VERSION "V1.7.4"

NS_ :

BS_:

BU_: DC RL RR FL FR

BO_ 1934 ReadCmd_FR: 64 FR
 SG_ ReadCmd_Subid_FR : 15|16@0+ (1,0) [0|65535] "" Vector__XXX
 SG_ ReadCmd_Sid_FR : 7|8@0+ (1,0) [0|255] "" Vector__XXX
 SG_ ReadCmd_length_FR : 31|8@0+ (1,0) [0|255] "" Vector__XXX
 SG_ ReadCmd_version2_FR : 103|64@0+ (1,0) [0|1.84467440737096E+019] "" Vector__XXX
 SG_ ReadCmd_version1_FR : 39|64@0+ (1,0) [0|1.84467440737096E+019] "" Vector__XXX

BO_ 1870 ReadCmd_FL: 64 FL
 SG_ ReadCmd_Subid_FL : 15|16@0+ (1,0) [0|65535] "" Vector__XXX
 SG_ ReadCmd_Sid_FL : 7|8@0+ (1,0) [0|255] "" Vector__XXX
 SG_ ReadCmd_length_FL : 31|8@0+ (1,0) [0|255] "" Vector__XXX
 SG_ ReadCmd_version2_FL : 103|64@0+ (1,0) [0|1.84467440737096E+019] "" Vector__XXX
 SG_ ReadCmd_version1_FL : 39|64@0+ (1,0) [0|1.84467440737096E+019] "" Vector__XXX

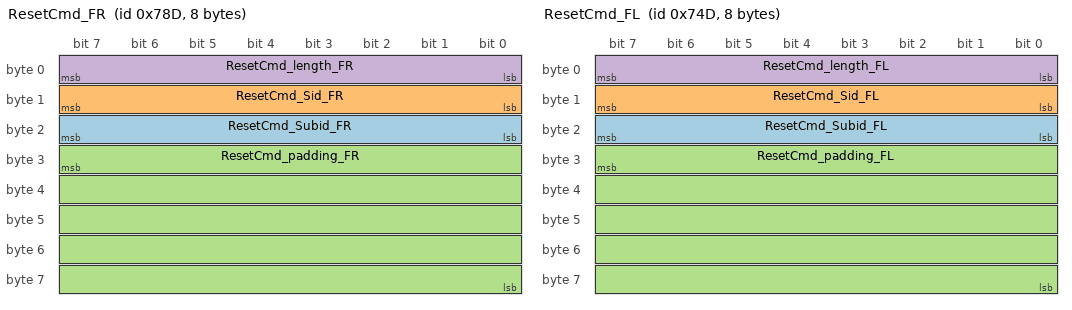
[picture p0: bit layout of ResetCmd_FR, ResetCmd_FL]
BO_ 1933 ResetCmd_FR: 8 FR
 SG_ ResetCmd_Subid_FR : 23|8@0+ (1,0) [0|255] "" Vector__XXX
 SG_ ResetCmd_Sid_FR : 15|8@0+ (1,0) [0|255] "" Vector__XXX
 SG_ ResetCmd_padding_FR : 31|40@0+ (1,0) [0|1099511627775] "" Vector__XXX
 SG_ ResetCmd_length_FR : 7|8@0+ (1,0) [0|255] "" Vector__XXX

BO_ 1869 ResetCmd_FL: 8 FL
 SG_ ResetCmd_Subid_FL : 23|8@0+ (1,0) [0|255] "" Vector__XXX
 SG_ ResetCmd_Sid_FL : 15|8@0+ (1,0) [0|255] "" Vector__XXX
 SG_ ResetCmd_padding_FL : 31|40@0+ (1,0) [0|1099511627775] "" Vector__XXX
 SG_ ResetCmd_length_FL : 7|8@0+ (1,0) [0|255] "" Vector__XXX

BO_ 1408 ObjectList_Obj1_FL: 64 FL
 SG_ RSDS_FL_PER_OBJ1_YawRate : 279|16@0+ (0.002,-3.14) [-3.14|127.93] "" Vector__XXX
 SG_ RSDS_FL_PER_OBJ1_Width : 263|16@0+ (0.01,0) [0|655.35] "" Vector__XXX
 SG_ RSDS_FL_PER_OBJ1_ValidFlag : 97|1@0+ (1,0) [0|1] "" Vector__XXX
 SG_ RSDS_FL_PER_OBJ1_ObstProbability : 255|8@0+ (1,0) [0|255] "" Vector__XXX
 SG_ RSDS_FL_PER_OBJ1_MotionType : 247|3@0+ (1,0) [0|7] "" Vector__XXX
 SG_ RSDS_FL_PER_OBJ1_MeasState : 99|2@0+ (1,0) [0|3] "" Vector__XXX
 SG_ RSDS_FL_PER_OBJ1_LifeCycle : 223|8@0+ (1,0) [0|255] "" Vector__XXX
 SG_ RSDS_FL_PER_OBJ1_Length : 231|16@0+ (0.05,0) [0|3276.75] "" Vector__XXX
 SG_ RSDS_FL_PER_OBJ1_ID : 215|8@0+ (1,0) [0|255] "" Vector__XXX
 SG_ RSDS_FL_PER_OBJ1_HeadingAng : 199|16@0+ (0.002,-3.14) [-3.14|127.93] "" Vector__XXX
 SG_ RSDS_FL_PER_OBJ1_ExistProb : 191|8@0+ (0.03326,0) [0|8.4813] "" Vector__XXX
 SG_ RSDS_FL_PER_OBJ1_DistZStd : 183|8@0+ (0.1,0) [0|25.5] "" Vector__XXX
 SG_ RSDS_FL_PER_OBJ1_DistZ : 167|16@0+ (0.125,-64) [-64|8127.875] "" Vector__XXX
 SG_ RSDS_FL_PER_OBJ1_DistYStd : 143|8@0+ (0.1,0) [0|25.5] "" Vector__XXX
 SG_ RSDS_FL_PER_OBJ1_DistY : 151|16@0+ (0.125,-256) [-256|7935.875] "" Vector__XXX
 SG_ RSDS_FL_PER_OBJ1_DistXStd : 135|8@0+ (0.1,0) [0|25.5] "" Vector__XXX
 SG_ RSDS_FL_PER_OBJ1_DistX : 119|16@0+ (0.0625,-256) [-256|3839.9375] "" Vector__XXX
 SG_ RSDS_FL_PER_OBJ1_ClassTypeProb : 111|8@0+ (1,0) [0|255] "" Vector__XXX
 SG_ RSDS_FL_PER_OBJ1_ClassType : 103|4@0+ (1,0) [0|15] "" Vector__XXX
 SG_ RSDS_FL_PER_OBJ1_AbsVelYStd : 79|8@0+ (0.0625,0) [0|15.9375] "" Vector__XXX
 SG_ RSDS_FL_PER_OBJ1_AbsVelY : 87|16@0+ (0.0312,-128) [-128|1916.692] "" Vector__XXX
 SG_ RSDS_FL_PER_OBJ1_AbsVelXStd : 71|8@0+ (0.0625,0) [0|15.9375] "" Vector__XXX
 SG_ RSDS_FL_PER_OBJ1_AbsVelX : 55|16@0+ (0.0312,-128) [-128|1916.692] "" Vector__XXX
 SG_ RSDS_FL_PER_OBJ1_AbsAccelYStd : 31|8@0+ (0.0625,0) [0|15.9375] "" Vector__XXX
 SG_ RSDS_FL_PER_OBJ1_AbsAccelY : 39|16@0+ (0.03125,-16) [-16|2031.96875] "" Vector__XXX
 SG_ RSDS_FL_PER_OBJ1_AbsAccelXStd : 23|8@0+ (0.0625,0) [0|15.9375] "" Vector__XXX
 SG_ RSDS_FL_PER_OBJ1_AbsAccelX : 7|16@0+ (0.03125,-16) [-16|2031.96875] "" Vector__XXX

BO_ 1502 FrameHeader_RR: 64 RR
 SG_ RSDS_RR_CALIB_RadarStatus : 179|2@0+ (1,0) [0|3] "" Vector__XXX
 SG_ RSDS_RR_NVMBLIND : 181|2@0+ (1,0) [0|3] "" Vector__XXX
 SG_ RSDS_RR_EnabledBLIND : 183|2@0+ (1,0) [0|3] "" Vector__XXX
 SG_ RSDS_RR_algoBLIND : 1|2@0+ (1,0) [0|3] "" Vector__XXX
 SG_ RSDS_RR_CALIB_InCalibState : 175|8@0+ (1,0) [0|255] "" Vector__XXX
 SG_ RSDS_RR_CALIB_FinalCalibState : 167|8@0+ (1,0) [0|255] "" Vector__XXX
 SG_ RSDS_RR_MountPosX : 151|16@0+ (0.001,-10) [-10|10] "" Vector__XXX
 SG_ RSDS_RR_YawMountAngle : 135|16@0+ (0.0001,-3.2) [-3.2|3.2] "" Vector__XXX
 SG_ RSDS_RR_RollMountAngle : 119|16@0+ (0.0001,-0.2) [-0.2|0.2] "" Vector__XXX
 SG_ RSDS_RR_PitchMountAngle : 103|16@0+ (0.0001,-0.2) [-0.2|0.2] "" Vector__XXX
 SG_ RSDS_RR_PER_OBJ_Num : 95|8@0+ (1,0) [0|255] "" Vector__XXX
 SG_ RSDS_RR_PER_HDR_Timestamp : 87|8@0+ (1,0) [0|255] "" Vector__XXX
 SG_ RSDS_RR_PER_HDR_RollingCounter : 5|4@0+ (1,0) [0|15] "" Vector__XXX
 SG_ RSDS_RR_PER_HDR_Checksum : 15|8@0+ (1,0) [0|255] "" Vector__XXX
 SG_ RSDS_RR_MountPosZ : 71|16@0+ (0.001,0) [0|2] "" Vector__XXX
 SG_ RSDS_RR_MountPosY : 55|16@0+ (0.001,-2.5) [-2.5|2.5] "" Vector__XXX
 SG_ RSDS_RR_CALIB_EleOffset : 39|16@0+ (0.0001,-1) [-1|1] "" Vector__XXX
 SG_ RSDS_RR_CALIB_AziOffset : 23|16@0+ (0.0001,-1) [-1|1] "" Vector__XXX
 SG_ RSDS_RR_BLIND : 7|2@0+ (1,0) [0|3] "" Vector__XXX

BO_ 1470 FrameHeader_RL: 64 RL
 SG_ RSDS_RL_CALIB_RadarStatus : 179|2@0+ (1,0) [0|3] "" Vector__XXX
 SG_ RSDS_RL_NVMBLIND : 181|2@0+ (1,0) [0|3] "" Vector__XXX
 SG_ RSDS_RL_EnabledBLIND : 183|2@0+ (1,0) [0|3] "" Vector__XXX
 SG_ RSDS_RL_algoBLIND : 1|2@0+ (1,0) [0|3] "" Vector__XXX
 SG_ RSDS_RL_CALIB_InCalibState : 175|8@0+ (1,0) [0|255] "" Vector__XXX
 SG_ RSDS_RL_CALIB_FinalCalibState : 167|8@0+ (1,0) [0|255] "" Vector__XXX
 SG_ RSDS_RL_MountPosX : 151|16@0+ (0.001,-10) [-10|10] "" Vector__XXX
 SG_ RSDS_RL_YawMountAngle : 135|16@0+ (0.0001,-3.2) [-3.2|3.2] "" Vector__XXX
 SG_ RSDS_RL_RollMountAngle : 119|16@0+ (0.0001,-0.2) [-0.2|0.2] "" Vector__XXX
 SG_ RSDS_RL_PitchMountAngle : 103|16@0+ (0.0001,-0.2) [-0.2|0.2] "" Vector__XXX
 SG_ RSDS_RL_PER_OBJ_Num : 95|8@0+ (1,0) [0|255] "" Vector__XXX
 SG_ RSDS_RL_PER_HDR_Timestamp : 87|8@0+ (1,0) [0|255] "" Vector__XXX
 SG_ RSDS_RL_PER_HDR_RollingCounter : 5|4@0+ (1,0) [0|15] "" Vector__XXX
 SG_ RSDS_RL_PER_HDR_Checksum : 15|8@0+ (1,0) [0|255] "" Vector__XXX
 SG_ RSDS_RL_MountPosZ : 71|16@0+ (0.001,0) [0|2] "" Vector__XXX
 SG_ RSDS_RL_MountPosY : 55|16@0+ (0.001,-2.5) [-2.5|2.5] "" Vector__XXX
 SG_ RSDS_RL_CALIB_EleOffset : 39|16@0+ (0.0001,-1) [-1|1] "" Vector__XXX
 SG_ RSDS_RL_CALIB_AziOffset : 23|16@0+ (0.0001,-1) [-1|1] "" Vector__XXX
 SG_ RSDS_RL_BLIND : 7|2@0+ (1,0) [0|3] "" Vector__XXX

BO_ 1454 FrameHeader_FR: 64 FR
 SG_ RSDS_FR_CALIB_RadarStatus : 179|2@0+ (1,0) [0|3] "" Vector__XXX
 SG_ RSDS_FR_NVMBLIND : 181|2@0+ (1,0) [0|3] "" Vector__XXX
 SG_ RSDS_FR_EnabledBLIND : 183|2@0+ (1,0) [0|3] "" Vector__XXX
 SG_ RSDS_FR_algoBLIND : 1|2@0+ (1,0) [0|3] "" Vector__XXX
 SG_ RSDS_FR_CALIB_InCalibState : 175|8@0+ (1,0) [0|255] "" Vector__XXX
 SG_ RSDS_FR_CALIB_FinalCalibState : 167|8@0+ (1,0) [0|255] "" Vector__XXX
 SG_ RSDS_FR_MountPosX : 151|16@0+ (0.001,-10) [-10|10] "" Vector__XXX
 SG_ RSDS_FR_YawMountAngle : 135|16@0+ (0.0001,-3.2) [-3.2|3.2] "" Vector__XXX
 SG_ RSDS_FR_RollMountAngle : 119|16@0+ (0.0001,-0.2) [-0.2|0.2] "" Vector__XXX
 SG_ RSDS_FR_PitchMountAngle : 103|16@0+ (0.0001,-0.2) [-0.2|0.2] "" Vector__XXX
 SG_ RSDS_FR_PER_OBJ_Num : 95|8@0+ (1,0) [0|255] "" Vector__XXX
 SG_ RSDS_FR_PER_HDR_Timestamp : 87|8@0+ (1,0) [0|255] "" Vector__XXX
 SG_ RSDS_FR_PER_HDR_RollingCounter : 5|4@0+ (1,0) [0|15] "" Vector__XXX
 SG_ RSDS_FR_PER_HDR_Checksum : 15|8@0+ (1,0) [0|255] "" Vector__XXX
 SG_ RSDS_FR_MountPosZ : 71|16@0+ (0.001,0) [0|2] "" Vector__XXX
 SG_ RSDS_FR_MountPosY : 55|16@0+ (0.001,-2.5) [-2.5|2.5] "" Vector__XXX
 SG_ RSDS_FR_CALIB_EleOffset : 39|16@0+ (0.0001,-1) [-1|1] "" Vector__XXX
 SG_ RSDS_FR_CALIB_AziOffset : 23|16@0+ (0.0001,-1) [-1|1] "" Vector__XXX
 SG_ RSDS_FR_BLIND : 7|2@0+ (1,0) [0|3] "" Vector__XXX

BO_ 1486 FrameHeader_FL: 64 FL
 SG_ RSDS_FL_CALIB_RadarStatus : 179|2@0+ (1,0) [0|3] "" Vector__XXX
 SG_ RSDS_FL_NVMBLIND : 181|2@0+ (1,0) [0|3] "" Vector__XXX
 SG_ RSDS_FL_EnabledBLIND : 183|2@0+ (1,0) [0|3] "" Vector__XXX
 SG_ RSDS_FL_algoBLIND : 1|2@0+ (1,0) [0|3] "" Vector__XXX
 SG_ RSDS_FL_CALIB_InCalibState : 175|8@0+ (1,0) [0|255] "" Vector__XXX
 SG_ RSDS_FL_CALIB_FinalCalibState : 167|8@0+ (1,0) [0|255] "" Vector__XXX
 SG_ RSDS_FL_MountPosX : 151|16@0+ (0.001,-10) [-10|10] "" Vector__XXX
 SG_ RSDS_FL_YawMountAngle : 135|16@0+ (0.0001,-3.2) [-3.2|3.2] "" Vector__XXX
 SG_ RSDS_FL_RollMountAngle : 119|16@0+ (0.0001,-0.2) [-0.2|0.2] "" Vector__XXX
 SG_ RSDS_FL_PitchMountAngle : 103|16@0+ (0.0001,-0.2) [-0.2|0.2] "" Vector__XXX
 SG_ RSDS_FL_PER_OBJ_Num : 95|8@0+ (1,0) [0|255] "" Vector__XXX
 SG_ RSDS_FL_PER_HDR_Timestamp : 87|8@0+ (1,0) [0|255] "" Vector__XXX
 SG_ RSDS_FL_PER_HDR_RollingCounter : 5|4@0+ (1,0) [0|15] "" Vector__XXX
 SG_ RSDS_FL_PER_HDR_Checksum : 15|8@0+ (1,0) [0|255] "" Vector__XXX
 SG_ RSDS_FL_MountPosZ : 71|16@0+ (0.001,0) [0|2] "" Vector__XXX
 SG_ RSDS_FL_MountPosY : 55|16@0+ (0.001,-2.5) [-2.5|2.5] "" Vector__XXX
 SG_ RSDS_FL_CALIB_EleOffset : 39|16@0+ (0.0001,-1) [-1|1] "" Vector__XXX
 SG_ RSDS_FL_CALIB_AziOffset : 23|16@0+ (0.0001,-1) [-1|1] "" Vector__XXX
 SG_ RSDS_FL_BLIND : 7|2@0+ (1,0) [0|3] "" Vector__XXX

BO_ 1031 DTC_GROUP2_RR: 64 RR
 SG_ DTC_Entry9_status_mask_RR : 479|8@0+ (1,0) [0|255] "" Vector__XXX
 SG_ DTC_Entry9_dtc_type_RR : 471|8@0+ (1,0) [0|255] "" Vector__XXX
 SG_ DTC_Entry9_dtc_num_RR : 439|32@0+ (1,0) [0|4294967295] "" Vector__XXX
 SG_ DTC_Entry9_change_ts_RR : 407|32@0+ (1,0) [0|4294967295] "" Vector__XXX
 SG_ DTC_Entry8_status_mask_RR : 399|8@0+ (1,0) [0|255] "" Vector__XXX
 SG_ DTC_Entry8_dtc_type_RR : 391|8@0+ (1,0) [0|255] "" Vector__XXX
 SG_ DTC_Entry8_dtc_num_RR : 359|32@0+ (1,0) [0|4294967295] "" Vector__XXX
 SG_ DTC_Entry8_change_ts_RR : 327|32@0+ (1,0) [0|4294967295] "" Vector__XXX
 SG_ DTC_Entry7_status_mask_RR : 319|8@0+ (1,0) [0|255] "" Vector__XXX
 SG_ DTC_Entry7_dtc_type_RR : 311|8@0+ (1,0) [0|255] "" Vector__XXX
 SG_ DTC_Entry7_dtc_num_RR : 279|32@0+ (1,0) [0|4294967295] "" Vector__XXX
 SG_ DTC_Entry7_change_ts_RR : 247|32@0+ (1,0) [0|4294967295] "" Vector__XXX
 SG_ DTC_Entry6_status_mask_RR : 239|8@0+ (1,0) [0|255] "" Vector__XXX
 SG_ DTC_Entry6_dtc_type_RR : 231|8@0+ (1,0) [0|255] "" Vector__XXX
 SG_ DTC_Entry6_dtc_num_RR : 199|32@0+ (1,0) [0|4294967295] "" Vector__XXX
 SG_ DTC_Entry6_change_ts_RR : 167|32@0+ (1,0) [0|4294967295] "" Vector__XXX
 SG_ DTC_Entry11_status_mask_RR : 159|8@0+ (1,0) [0|255] "" Vector__XXX
 SG_ DTC_Entry11_dtc_type_RR : 151|8@0+ (1,0) [0|255] "" Vector__XXX
 SG_ DTC_Entry11_dtc_num_RR : 119|32@0+ (1,0) [0|4294967295] "" Vector__XXX
 SG_ DTC_Entry11_change_ts_RR : 87|32@0+ (1,0) [0|4294967295] "" Vector__XXX
 SG_ DTC_Entry10_status_mask_RR : 79|8@0+ (1,0) [0|255] "" Vector__XXX
 SG_ DTC_Entry10_dtc_type_RR : 71|8@0+ (1,0) [0|255] "" Vector__XXX
 SG_ DTC_Entry10_dtc_num_RR : 39|32@0+ (1,0) [0|4294967295] "" Vector__XXX
 SG_ DTC_Entry10_change_ts_RR : 7|32@0+ (1,0) [0|4294967295] "" Vector__XXX

BO_ 1029 DTC_GROUP2_RL: 64 RL
 SG_ DTC_Entry9_status_mask_RL : 479|8@0+ (1,0) [0|255] "" Vector__XXX
 SG_ DTC_Entry9_dtc_type_RL : 471|8@0+ (1,0) [0|255] "" Vector__XXX
 SG_ DTC_Entry9_dtc_num_RL : 439|32@0+ (1,0) [0|4294967295] "" Vector__XXX
 SG_ DTC_Entry9_change_ts_RL : 407|32@0+ (1,0) [0|4294967295] "" Vector__XXX
 SG_ DTC_Entry8_status_mask_RL : 399|8@0+ (1,0) [0|255] "" Vector__XXX
 SG_ DTC_Entry8_dtc_type_RL : 391|8@0+ (1,0) [0|255] "" Vector__XXX
 SG_ DTC_Entry8_dtc_num_RL : 359|32@0+ (1,0) [0|4294967295] "" Vector__XXX
 SG_ DTC_Entry8_change_ts_RL : 327|32@0+ (1,0) [0|4294967295] "" Vector__XXX
 SG_ DTC_Entry7_status_mask_RL : 319|8@0+ (1,0) [0|255] "" Vector__XXX
 SG_ DTC_Entry7_dtc_type_RL : 311|8@0+ (1,0) [0|255] "" Vector__XXX
 SG_ DTC_Entry7_dtc_num_RL : 279|32@0+ (1,0) [0|4294967295] "" Vector__XXX
 SG_ DTC_Entry7_change_ts_RL : 247|32@0+ (1,0) [0|4294967295] "" Vector__XXX
 SG_ DTC_Entry6_status_mask_RL : 239|8@0+ (1,0) [0|255] "" Vector__XXX
 SG_ DTC_Entry6_dtc_type_RL : 231|8@0+ (1,0) [0|255] "" Vector__XXX
 SG_ DTC_Entry6_dtc_num_RL : 199|32@0+ (1,0) [0|4294967295] "" Vector__XXX
 SG_ DTC_Entry6_change_ts_RL : 167|32@0+ (1,0) [0|4294967295] "" Vector__XXX
 SG_ DTC_Entry11_status_mask_RL : 159|8@0+ (1,0) [0|255] "" Vector__XXX
 SG_ DTC_Entry11_dtc_type_RL : 151|8@0+ (1,0) [0|255] "" Vector__XXX
 SG_ DTC_Entry11_dtc_num_RL : 119|32@0+ (1,0) [0|4294967295] "" Vector__XXX
 SG_ DTC_Entry11_change_ts_RL : 87|32@0+ (1,0) [0|4294967295] "" Vector__XXX
 SG_ DTC_Entry10_status_mask_RL : 79|8@0+ (1,0) [0|255] "" Vector__XXX
 SG_ DTC_Entry10_dtc_type_RL : 71|8@0+ (1,0) [0|255] "" Vector__XXX
 SG_ DTC_Entry10_dtc_num_RL : 39|32@0+ (1,0) [0|4294967295] "" Vector__XXX
 SG_ DTC_Entry10_change_ts_RL : 7|32@0+ (1,0) [0|4294967295] "" Vector__XXX

BO_ 1027 DTC_GROUP2_FR: 64 Vector__XXX
 SG_ DTC_Entry9_status_mask_FR : 479|8@0+ (1,0) [0|255] "" Vector__XXX
 SG_ DTC_Entry9_dtc_type_FR : 471|8@0+ (1,0) [0|255] "" Vector__XXX
 SG_ DTC_Entry9_dtc_num_FR : 439|32@0+ (1,0) [0|4294967295] "" Vector__XXX
 SG_ DTC_Entry9_change_ts_FR : 407|32@0+ (1,0) [0|4294967295] "" Vector__XXX
 SG_ DTC_Entry8_status_mask_FR : 399|8@0+ (1,0) [0|255] "" Vector__XXX
 SG_ DTC_Entry8_dtc_type_FR : 391|8@0+ (1,0) [0|255] "" Vector__XXX
 SG_ DTC_Entry8_dtc_num_FR : 359|32@0+ (1,0) [0|4294967295] "" Vector__XXX
 SG_ DTC_Entry8_change_ts_FR : 327|32@0+ (1,0) [0|4294967295] "" Vector__XXX
 SG_ DTC_Entry7_status_mask_FR : 319|8@0+ (1,0) [0|255] "" Vector__XXX
 SG_ DTC_Entry7_dtc_type_FR : 311|8@0+ (1,0) [0|255] "" Vector__XXX
 SG_ DTC_Entry7_dtc_num_FR : 279|32@0+ (1,0) [0|4294967295] "" Vector__XXX
 SG_ DTC_Entry7_change_ts_FR : 247|32@0+ (1,0) [0|4294967295] "" Vector__XXX
 SG_ DTC_Entry6_status_mask_FR : 239|8@0+ (1,0) [0|255] "" Vector__XXX
 SG_ DTC_Entry6_dtc_type_FR : 231|8@0+ (1,0) [0|255] "" Vector__XXX
 SG_ DTC_Entry6_dtc_num_FR : 199|32@0+ (1,0) [0|4294967295] "" Vector__XXX
 SG_ DTC_Entry6_change_ts_FR : 167|32@0+ (1,0) [0|4294967295] "" Vector__XXX
 SG_ DTC_Entry11_status_mask_FR : 159|8@0+ (1,0) [0|255] "" Vector__XXX
 SG_ DTC_Entry11_dtc_type_FR : 151|8@0+ (1,0) [0|255] "" Vector__XXX
 SG_ DTC_Entry11_dtc_num_FR : 119|32@0+ (1,0) [0|4294967295] "" Vector__XXX
 SG_ DTC_Entry11_change_ts_FR : 87|32@0+ (1,0) [0|4294967295] "" Vector__XXX
 SG_ DTC_Entry10_status_mask_FR : 79|8@0+ (1,0) [0|255] "" Vector__XXX
 SG_ DTC_Entry10_dtc_type_FR : 71|8@0+ (1,0) [0|255] "" Vector__XXX
 SG_ DTC_Entry10_dtc_num_FR : 39|32@0+ (1,0) [0|4294967295] "" Vector__XXX
 SG_ DTC_Entry10_change_ts_FR : 7|32@0+ (1,0) [0|4294967295] "" Vector__XXX

BO_ 1030 DTC_GROUP1_RR: 64 RR
 SG_ DTC_TimeStamp_RR : 439|32@0+ (1,0) [0|4294967295] "" Vector__XXX
 SG_ DTC_Number_RR : 431|8@0+ (1,0) [0|255] "" Vector__XXX
 SG_ DTC_MessageType_RR : 423|8@0+ (1,0) [0|255] "" Vector__XXX
 SG_ DTC_Frame_Number_RR : 407|16@0+ (1,0) [0|65535] "" Vector__XXX
 SG_ DTC_Entry5_status_mask_RR : 399|8@0+ (1,0) [0|255] "" Vector__XXX
 SG_ DTC_Entry5_dtc_type_RR : 391|8@0+ (1,0) [0|255] "" Vector__XXX
 SG_ DTC_Entry5_dtc_num_RR : 359|32@0+ (1,0) [0|4294967295] "" Vector__XXX
 SG_ DTC_Entry5_change_ts_RR : 327|32@0+ (1,0) [0|4294967295] "" Vector__XXX
 SG_ DTC_Entry4_status_mask_RR : 319|8@0+ (1,0) [0|255] "" Vector__XXX
 SG_ DTC_Entry4_dtc_type_RR : 311|8@0+ (1,0) [0|255] "" Vector__XXX
 SG_ DTC_Entry4_dtc_num_RR : 279|32@0+ (1,0) [0|4294967295] "" Vector__XXX
 SG_ DTC_Entry4_change_ts_RR : 247|32@0+ (1,0) [0|4294967295] "" Vector__XXX
 SG_ DTC_Entry3_status_mask_RR : 239|8@0+ (1,0) [0|255] "" Vector__XXX
 SG_ DTC_Entry3_dtc_type_RR : 231|8@0+ (1,0) [0|255] "" Vector__XXX
 SG_ DTC_Entry3_dtc_num_RR : 199|32@0+ (1,0) [0|4294967295] "" Vector__XXX
 SG_ DTC_Entry3_change_ts_RR : 167|32@0+ (1,0) [0|4294967295] "" Vector__XXX
 SG_ DTC_Entry2_status_mask_RR : 159|8@0+ (1,0) [0|255] "" Vector__XXX
 SG_ DTC_Entry2_dtc_type_RR : 151|8@0+ (1,0) [0|255] "" Vector__XXX
 SG_ DTC_Entry2_dtc_num_RR : 119|32@0+ (1,0) [0|4294967295] "" Vector__XXX
 SG_ DTC_Entry2_change_ts_RR : 87|32@0+ (1,0) [0|4294967295] "" Vector__XXX
 SG_ DTC_Entry1_status_mask_RR : 79|8@0+ (1,0) [0|255] "" Vector__XXX
 SG_ DTC_Entry1_dtc_type_RR : 71|8@0+ (1,0) [0|255] "" Vector__XXX
 SG_ DTC_Entry1_dtc_num_RR : 39|32@0+ (1,0) [0|4294967295] "" Vector__XXX
 SG_ DTC_Entry1_change_ts_RR : 7|32@0+ (1,0) [0|4294967295] "" Vector__XXX

BO_ 1028 DTC_GROUP1_RL: 64 RL
 SG_ DTC_TimeStamp_RL : 439|32@0+ (1,0) [0|4294967295] "" Vector__XXX
 SG_ DTC_Number_RL : 431|8@0+ (1,0) [0|255] "" Vector__XXX
 SG_ DTC_MessageType_RL : 423|8@0+ (1,0) [0|255] "" Vector__XXX
 SG_ DTC_Frame_Number_RL : 407|16@0+ (1,0) [0|65535] "" Vector__XXX
 SG_ DTC_Entry5_status_mask_RL : 399|8@0+ (1,0) [0|255] "" Vector__XXX
 SG_ DTC_Entry5_dtc_type_RL : 391|8@0+ (1,0) [0|255] "" Vector__XXX
 SG_ DTC_Entry5_dtc_num_RL : 359|32@0+ (1,0) [0|4294967295] "" Vector__XXX
 SG_ DTC_Entry5_change_ts_RL : 327|32@0+ (1,0) [0|4294967295] "" Vector__XXX
 SG_ DTC_Entry4_status_mask_RL : 319|8@0+ (1,0) [0|255] "" Vector__XXX
 SG_ DTC_Entry4_dtc_type_RL : 311|8@0+ (1,0) [0|255] "" Vector__XXX
 SG_ DTC_Entry4_dtc_num_RL : 279|32@0+ (1,0) [0|4294967295] "" Vector__XXX
 SG_ DTC_Entry4_change_ts_RL : 247|32@0+ (1,0) [0|4294967295] "" Vector__XXX
 SG_ DTC_Entry3_status_mask_RL : 239|8@0+ (1,0) [0|255] "" Vector__XXX
 SG_ DTC_Entry3_dtc_type_RL : 231|8@0+ (1,0) [0|255] "" Vector__XXX
 SG_ DTC_Entry3_dtc_num_RL : 199|32@0+ (1,0) [0|4294967295] "" Vector__XXX
 SG_ DTC_Entry3_change_ts_RL : 167|32@0+ (1,0) [0|4294967295] "" Vector__XXX
 SG_ DTC_Entry2_status_mask_RL : 159|8@0+ (1,0) [0|255] "" Vector__XXX
 SG_ DTC_Entry2_dtc_type_RL : 151|8@0+ (1,0) [0|255] "" Vector__XXX
 SG_ DTC_Entry2_dtc_num_RL : 119|32@0+ (1,0) [0|4294967295] "" Vector__XXX
 SG_ DTC_Entry2_change_ts_RL : 87|32@0+ (1,0) [0|4294967295] "" Vector__XXX
 SG_ DTC_Entry1_status_mask_RL : 79|8@0+ (1,0) [0|255] "" Vector__XXX
 SG_ DTC_Entry1_dtc_type_RL : 71|8@0+ (1,0) [0|255] "" Vector__XXX
 SG_ DTC_Entry1_dtc_num_RL : 39|32@0+ (1,0) [0|4294967295] "" Vector__XXX
 SG_ DTC_Entry1_change_ts_RL : 7|32@0+ (1,0) [0|4294967295] "" Vector__XXX

BO_ 1026 DTC_GROUP1_FR: 64 Vector__XXX
 SG_ DTC_TimeStamp_FR : 439|32@0+ (1,0) [0|4294967295] "" Vector__XXX
 SG_ DTC_Number_FR : 431|8@0+ (1,0) [0|255] "" Vector__XXX
 SG_ DTC_MessageType_FR : 423|8@0+ (1,0) [0|255] "" Vector__XXX
 SG_ DTC_Frame_Number_FR : 407|16@0+ (1,0) [0|65535] "" Vector__XXX
 SG_ DTC_Entry5_status_mask_FR : 399|8@0+ (1,0) [0|255] "" Vector__XXX
 SG_ DTC_Entry5_dtc_type_FR : 391|8@0+ (1,0) [0|255] "" Vector__XXX
 SG_ DTC_Entry5_dtc_num_FR : 359|32@0+ (1,0) [0|4294967295] "" Vector__XXX
 SG_ DTC_Entry5_change_ts_FR : 327|32@0+ (1,0) [0|4294967295] "" Vector__XXX
 SG_ DTC_Entry4_status_mask_FR : 319|8@0+ (1,0) [0|255] "" Vector__XXX
 SG_ DTC_Entry4_dtc_type_FR : 311|8@0+ (1,0) [0|255] "" Vector__XXX
 SG_ DTC_Entry4_dtc_num_FR : 279|32@0+ (1,0) [0|4294967295] "" Vector__XXX
 SG_ DTC_Entry4_change_ts_FR : 247|32@0+ (1,0) [0|4294967295] "" Vector__XXX
 SG_ DTC_Entry3_status_mask_FR : 239|8@0+ (1,0) [0|255] "" Vector__XXX
 SG_ DTC_Entry3_dtc_type_FR : 231|8@0+ (1,0) [0|255] "" Vector__XXX
 SG_ DTC_Entry3_dtc_num_FR : 199|32@0+ (1,0) [0|4294967295] "" Vector__XXX
 SG_ DTC_Entry3_change_ts_FR : 167|32@0+ (1,0) [0|4294967295] "" Vector__XXX
 SG_ DTC_Entry2_status_mask_FR : 159|8@0+ (1,0) [0|255] "" Vector__XXX
 SG_ DTC_Entry2_dtc_type_FR : 151|8@0+ (1,0) [0|255] "" Vector__XXX
 SG_ DTC_Entry2_dtc_num_FR : 119|32@0+ (1,0) [0|4294967295] "" Vector__XXX
 SG_ DTC_Entry2_change_ts_FR : 87|32@0+ (1,0) [0|4294967295] "" Vector__XXX
 SG_ DTC_Entry1_status_mask_FR : 79|8@0+ (1,0) [0|255] "" Vector__XXX
 SG_ DTC_Entry1_dtc_type_FR : 71|8@0+ (1,0) [0|255] "" Vector__XXX
 SG_ DTC_Entry1_dtc_num_FR : 39|32@0+ (1,0) [0|4294967295] "" Vector__XXX
 SG_ DTC_Entry1_change_ts_FR : 7|32@0+ (1,0) [0|4294967295] "" Vector__XXX

BO_ 1025 DTC_GROUP2_FL: 64 FL
 SG_ DTC_Entry9_status_mask_FL : 479|8@0+ (1,0) [0|255] "" Vector__XXX
 SG_ DTC_Entry9_dtc_type_FL : 471|8@0+ (1,0) [0|255] "" Vector__XXX
 SG_ DTC_Entry9_dtc_num_FL : 439|32@0+ (1,0) [0|4294967295] "" Vector__XXX
 SG_ DTC_Entry9_change_ts_FL : 407|32@0+ (1,0) [0|4294967295] "" Vector__XXX
 SG_ DTC_Entry8_status_mask_FL : 399|8@0+ (1,0) [0|255] "" Vector__XXX
 SG_ DTC_Entry8_dtc_type_FL : 391|8@0+ (1,0) [0|255] "" Vector__XXX
 SG_ DTC_Entry8_dtc_num_FL : 359|32@0+ (1,0) [0|4294967295] "" Vector__XXX
 SG_ DTC_Entry8_change_ts_FL : 327|32@0+ (1,0) [0|4294967295] "" Vector__XXX
 SG_ DTC_Entry7_status_mask_FL : 319|8@0+ (1,0) [0|255] "" Vector__XXX
 SG_ DTC_Entry7_dtc_type_FL : 311|8@0+ (1,0) [0|255] "" Vector__XXX
 SG_ DTC_Entry7_dtc_num_FL : 279|32@0+ (1,0) [0|4294967295] "" Vector__XXX
 SG_ DTC_Entry7_change_ts_FL : 247|32@0+ (1,0) [0|4294967295] "" Vector__XXX
 SG_ DTC_Entry6_status_mask_FL : 239|8@0+ (1,0) [0|255] "" Vector__XXX
 SG_ DTC_Entry6_dtc_type_FL : 231|8@0+ (1,0) [0|255] "" Vector__XXX
 SG_ DTC_Entry6_dtc_num_FL : 199|32@0+ (1,0) [0|4294967295] "" Vector__XXX
 SG_ DTC_Entry6_change_ts_FL : 167|32@0+ (1,0) [0|4294967295] "" Vector__XXX
 SG_ DTC_Entry11_status_mask_FL : 159|8@0+ (1,0) [0|255] "" Vector__XXX
 SG_ DTC_Entry11_dtc_type_FL : 151|8@0+ (1,0) [0|255] "" Vector__XXX
 SG_ DTC_Entry11_dtc_num_FL : 119|32@0+ (1,0) [0|4294967295] "" Vector__XXX
 SG_ DTC_Entry11_change_ts_FL : 87|32@0+ (1,0) [0|4294967295] "" Vector__XXX
 SG_ DTC_Entry10_status_mask_FL : 79|8@0+ (1,0) [0|255] "" Vector__XXX
 SG_ DTC_Entry10_dtc_type_FL : 71|8@0+ (1,0) [0|255] "" Vector__XXX
 SG_ DTC_Entry10_dtc_num_FL : 39|32@0+ (1,0) [0|4294967295] "" Vector__XXX
 SG_ DTC_Entry10_change_ts_FL : 7|32@0+ (1,0) [0|4294967295] "" Vector__XXX

BO_ 1024 DTC_GROUP1_FL: 64 FL
 SG_ DTC_TimeStamp_FL : 439|32@0+ (1,0) [0|4294967295] "" Vector__XXX
 SG_ DTC_Number_FL : 431|8@0+ (1,0) [0|255] "" Vector__XXX
 SG_ DTC_MessageType_FL : 423|8@0+ (1,0) [0|255] "" Vector__XXX
 SG_ DTC_Frame_Number_FL : 407|16@0+ (1,0) [0|65535] "" Vector__XXX
 SG_ DTC_Entry5_status_mask_FL : 399|8@0+ (1,0) [0|255] "" Vector__XXX
 SG_ DTC_Entry5_dtc_type_FL : 391|8@0+ (1,0) [0|255] "" Vector__XXX
 SG_ DTC_Entry5_dtc_num_FL : 359|32@0+ (1,0) [0|4294967295] "" Vector__XXX
 SG_ DTC_Entry5_change_ts_FL : 327|32@0+ (1,0) [0|4294967295] "" Vector__XXX
 SG_ DTC_Entry4_status_mask_FL : 319|8@0+ (1,0) [0|255] "" Vector__XXX
 SG_ DTC_Entry4_dtc_type_FL : 311|8@0+ (1,0) [0|255] "" Vector__XXX
 SG_ DTC_Entry4_dtc_num_FL : 279|32@0+ (1,0) [0|4294967295] "" Vector__XXX
 SG_ DTC_Entry4_change_ts_FL : 247|32@0+ (1,0) [0|4294967295] "" Vector__XXX
 SG_ DTC_Entry3_status_mask_FL : 239|8@0+ (1,0) [0|255] "" Vector__XXX
 SG_ DTC_Entry3_dtc_type_FL : 231|8@0+ (1,0) [0|255] "" Vector__XXX
 SG_ DTC_Entry3_dtc_num_FL : 199|32@0+ (1,0) [0|4294967295] "" Vector__XXX
 SG_ DTC_Entry3_change_ts_FL : 167|32@0+ (1,0) [0|4294967295] "" Vector__XXX
 SG_ DTC_Entry2_status_mask_FL : 159|8@0+ (1,0) [0|255] "" Vector__XXX
 SG_ DTC_Entry2_dtc_type_FL : 151|8@0+ (1,0) [0|255] "" Vector__XXX
 SG_ DTC_Entry2_dtc_num_FL : 119|32@0+ (1,0) [0|4294967295] "" Vector__XXX
 SG_ DTC_Entry2_change_ts_FL : 87|32@0+ (1,0) [0|4294967295] "" Vector__XXX
 SG_ DTC_Entry1_status_mask_FL : 79|8@0+ (1,0) [0|255] "" Vector__XXX
 SG_ DTC_Entry1_dtc_type_FL : 71|8@0+ (1,0) [0|255] "" Vector__XXX
 SG_ DTC_Entry1_dtc_num_FL : 39|32@0+ (1,0) [0|4294967295] "" Vector__XXX
 SG_ DTC_Entry1_change_ts_FL : 7|32@0+ (1,0) [0|4294967295] "" Vector__XXX

BO_ 1649 CAL_Static_Result_Res_RR: 64 RR
 SG_ CAL_Static_RouteId_RR : 7|8@0+ (1,0) [0|255] "" Vector__XXX
 SG_ CAL_alignment_Result_RR : 15|16@0+ (1,0) [0|65535] "" Vector__XXX
 SG_ CAL_alignment_failurecode_RR : 31|16@0+ (1,0) [0|65535] "" Vector__XXX

BO_ 1137 CAL_Static_Result_Res_RL: 64 RL
 SG_ CAL_Static_RouteId_RL : 7|8@0+ (1,0) [0|255] "" Vector__XXX
 SG_ CAL_alignment_Result_RL : 15|16@0+ (1,0) [0|65535] "" Vector__XXX
 SG_ CAL_alignment_failurecode_RL : 31|16@0+ (1,0) [0|65535] "" Vector__XXX

BO_ 625 CAL_Static_Result_Res_FR: 64 FR
 SG_ CAL_Static_RouteId_FR : 7|8@0+ (1,0) [0|255] "" Vector__XXX
 SG_ CAL_alignment_Result_FR : 15|16@0+ (1,0) [0|65535] "" Vector__XXX
 SG_ CAL_alignment_failurecode_FR : 31|16@0+ (1,0) [0|65535] "" Vector__XXX

BO_ 113 CAL_Static_Result_Res_FL: 64 FL
 SG_ CAL_Static_RouteId_FL : 7|8@0+ (1,0) [0|255] "" Vector__XXX
 SG_ CAL_alignment_Result_FL : 15|16@0+ (1,0) [0|65535] "" Vector__XXX
 SG_ CAL_alignment_failurecode_FL : 31|16@0+ (1,0) [0|65535] "" Vector__XXX

BO_ 1648 CAL_Cfg_Res_RR: 64 RR
 SG_ CAL_RouteId_RR : 7|8@0+ (1,0) [0|255] "" Vector__XXX
 SG_ CAL_result_status_RR : 15|8@0+ (1,0) [0|255] "" Vector__XXX

BO_ 1136 CAL_Cfg_Res_RL: 64 RL
 SG_ CAL_RouteId_RL : 7|8@0+ (1,0) [0|255] "" Vector__XXX
 SG_ CAL_result_status_RL : 15|8@0+ (1,0) [0|255] "" Vector__XXX

BO_ 624 CAL_Cfg_Res_FR: 64 FR
 SG_ CAL_RouteId_FR : 7|8@0+ (1,0) [0|255] "" Vector__XXX
 SG_ CAL_result_status_FR : 15|8@0+ (1,0) [0|255] "" Vector__XXX

BO_ 112 CAL_Cfg_Res_FL: 64 FL
 SG_ CAL_RouteId_FL : 7|8@0+ (1,0) [0|255] "" Vector__XXX
 SG_ CAL_result_status_FL : 15|8@0+ (1,0) [0|255] "" Vector__XXX

BO_ 263 SYS_M4_RR: 64 RR
 SG_ SYS_valid1_RR : 63|8@0+ (1,0) [0|255] "" Vector__XXX
 SG_ SYS_m4_8_RR : 455|64@0+ (1,0) [0|9.22337203685478E+018] "" Vector__XXX
 SG_ SYS_m4_7_RR : 391|64@0+ (1,0) [0|9.22337203685478E+018] "" Vector__XXX
 SG_ SYS_m4_6_RR : 327|64@0+ (1,0) [0|9.22337203685478E+018] "" Vector__XXX
 SG_ SYS_m4_5_RR : 263|64@0+ (1,0) [0|9.22337203685478E+018] "" Vector__XXX
 SG_ SYS_m4_4_RR : 199|64@0+ (1,0) [0|9.22337203685478E+018] "" Vector__XXX
 SG_ SYS_m4_3_RR : 135|64@0+ (1,0) [0|9.22337203685478E+018] "" Vector__XXX
 SG_ SYS_m4_2_RR : 71|64@0+ (1,0) [0|9.22337203685478E+018] "" Vector__XXX
 SG_ SYS_m4_1_RR : 7|56@0+ (1,0) [0|7.20575940379279E+016] "" Vector__XXX

BO_ 262 SYS_M4_RL: 64 RL
 SG_ SYS_valid1_RL : 63|8@0+ (1,0) [0|255] "" Vector__XXX
 SG_ SYS_m4_8_RL : 455|64@0+ (1,0) [0|9.22337203685478E+018] "" Vector__XXX
 SG_ SYS_m4_7_RL : 391|64@0+ (1,0) [0|9.22337203685478E+018] "" Vector__XXX
 SG_ SYS_m4_6_RL : 327|64@0+ (1,0) [0|9.22337203685478E+018] "" Vector__XXX
 SG_ SYS_m4_5_RL : 263|64@0+ (1,0) [0|9.22337203685478E+018] "" Vector__XXX
 SG_ SYS_m4_4_RL : 199|64@0+ (1,0) [0|9.22337203685478E+018] "" Vector__XXX
 SG_ SYS_m4_3_RL : 135|64@0+ (1,0) [0|9.22337203685478E+018] "" Vector__XXX
 SG_ SYS_m4_2_RL : 71|64@0+ (1,0) [0|9.22337203685478E+018] "" Vector__XXX
 SG_ SYS_m4_1_RL : 7|56@0+ (1,0) [0|7.20575940379279E+016] "" Vector__XXX

BO_ 261 SYS_M4_FR: 64 FR
 SG_ SYS_valid1_FR : 63|8@0+ (1,0) [0|255] "" Vector__XXX
 SG_ SYS_m4_8_FR : 455|64@0+ (1,0) [0|9.22337203685478E+018] "" Vector__XXX
 SG_ SYS_m4_7_FR : 391|64@0+ (1,0) [0|9.22337203685478E+018] "" Vector__XXX
 SG_ SYS_m4_6_FR : 327|64@0+ (1,0) [0|9.22337203685478E+018] "" Vector__XXX
 SG_ SYS_m4_5_FR : 263|64@0+ (1,0) [0|9.22337203685478E+018] "" Vector__XXX
 SG_ SYS_m4_4_FR : 199|64@0+ (1,0) [0|9.22337203685478E+018] "" Vector__XXX
 SG_ SYS_m4_3_FR : 135|64@0+ (1,0) [0|9.22337203685478E+018] "" Vector__XXX
 SG_ SYS_m4_2_FR : 71|64@0+ (1,0) [0|9.22337203685478E+018] "" Vector__XXX
 SG_ SYS_m4_1_FR : 7|56@0+ (1,0) [0|7.20575940379279E+016] "" Vector__XXX

BO_ 260 SYS_M4_FL: 64 FL
 SG_ SYS_valid1_FL : 63|8@0+ (1,0) [0|255] "" Vector__XXX
 SG_ SYS_m4_8_FL : 455|64@0+ (1,0) [0|9.22337203685478E+018] "" Vector__XXX
 SG_ SYS_m4_7_FL : 391|64@0+ (1,0) [0|9.22337203685478E+018] "" Vector__XXX
 SG_ SYS_m4_6_FL : 327|64@0+ (1,0) [0|9.22337203685478E+018] "" Vector__XXX
 SG_ SYS_m4_5_FL : 263|64@0+ (1,0) [0|9.22337203685478E+018] "" Vector__XXX
 SG_ SYS_m4_4_FL : 199|64@0+ (1,0) [0|9.22337203685478E+018] "" Vector__XXX
 SG_ SYS_m4_3_FL : 135|64@0+ (1,0) [0|9.22337203685478E+018] "" Vector__XXX
 SG_ SYS_m4_2_FL : 71|64@0+ (1,0) [0|9.22337203685478E+018] "" Vector__XXX
 SG_ SYS_m4_1_FL : 7|56@0+ (1,0) [0|7.20575940379279E+016] "" Vector__XXX

BO_ 259 SYS_R5_RR: 64 RR
 SG_ SYS_valid2_RR : 63|8@0+ (1,0) [0|255] "" Vector__XXX
 SG_ SYS_r5_8_RR : 455|64@0+ (1,0) [0|9.22337203685478E+018] "" Vector__XXX
 SG_ SYS_r5_7_RR : 391|64@0+ (1,0) [0|9.22337203685478E+018] "" Vector__XXX
 SG_ SYS_r5_6_RR : 327|64@0+ (1,0) [0|9.22337203685478E+018] "" Vector__XXX
 SG_ SYS_r5_5_RR : 263|64@0+ (1,0) [0|9.22337203685478E+018] "" Vector__XXX
 SG_ SYS_r5_4_RR : 199|64@0+ (1,0) [0|9.22337203685478E+018] "" Vector__XXX
 SG_ SYS_r5_3_RR : 135|64@0+ (1,0) [0|9.22337203685478E+018] "" Vector__XXX
 SG_ SYS_r5_2_RR : 71|64@0+ (1,0) [0|9.22337203685478E+018] "" Vector__XXX
 SG_ SYS_r5_1_RR : 7|56@0+ (1,0) [0|7.20575940379279E+016] "" Vector__XXX

BO_ 258 SYS_R5_RL: 64 RL
 SG_ SYS_r5_8_RL : 455|64@0+ (1,0) [0|9.22337203685478E+018] "" Vector__XXX
 SG_ SYS_r5_7_RL : 391|64@0+ (1,0) [0|9.22337203685478E+018] "" Vector__XXX
 SG_ SYS_r5_6_RL : 327|64@0+ (1,0) [0|9.22337203685478E+018] "" Vector__XXX
 SG_ SYS_r5_5_RL : 263|64@0+ (1,0) [0|9.22337203685478E+018] "" Vector__XXX
 SG_ SYS_r5_4_RL : 199|64@0+ (1,0) [0|9.22337203685478E+018] "" Vector__XXX
 SG_ SYS_r5_3_RL : 135|64@0+ (1,0) [0|9.22337203685478E+018] "" Vector__XXX
 SG_ SYS_r5_2_RL : 71|64@0+ (1,0) [0|9.22337203685478E+018] "" Vector__XXX
 SG_ SYS_r5_1_RL : 7|56@0+ (1,0) [0|7.20575940379279E+016] "" Vector__XXX
 SG_ SYS_valid2_RL : 63|8@0+ (1,0) [0|255] "" Vector__XXX

BO_ 257 SYS_R5_FR: 64 FR
 SG_ SYS_valid2_FR : 63|8@0+ (1,0) [0|255] "" Vector__XXX
 SG_ SYS_r5_8_FR : 455|64@0+ (1,0) [0|9.22337203685478E+018] "" Vector__XXX
 SG_ SYS_r5_7_FR : 391|64@0+ (1,0) [0|9.22337203685478E+018] "" Vector__XXX
 SG_ SYS_r5_6_FR : 327|64@0+ (1,0) [0|9.22337203685478E+018] "" Vector__XXX
 SG_ SYS_r5_5_FR : 263|64@0+ (1,0) [0|9.22337203685478E+018] "" Vector__XXX
 SG_ SYS_r5_4_FR : 199|64@0+ (1,0) [0|9.22337203685478E+018] "" Vector__XXX
 SG_ SYS_r5_3_FR : 135|64@0+ (1,0) [0|9.22337203685478E+018] "" Vector__XXX
 SG_ SYS_r5_2_FR : 71|64@0+ (1,0) [0|9.22337203685478E+018] "" Vector__XXX
 SG_ SYS_r5_1_FR : 7|56@0+ (1,0) [0|7.20575940379279E+016] "" Vector__XXX

BO_ 256 SYS_R5_FL: 64 FL
 SG_ SYS_valid2_FL : 63|8@0+ (1,0) [0|255] "" Vector__XXX
 SG_ SYS_r5_8_FL : 455|64@0+ (1,0) [0|9.22337203685478E+018] "" Vector__XXX
 SG_ SYS_r5_7_FL : 391|64@0+ (1,0) [0|9.22337203685478E+018] "" Vector__XXX
 SG_ SYS_r5_6_FL : 327|64@0+ (1,0) [0|9.22337203685478E+018] "" Vector__XXX
 SG_ SYS_r5_5_FL : 263|64@0+ (1,0) [0|9.22337203685478E+018] "" Vector__XXX
 SG_ SYS_r5_4_FL : 199|64@0+ (1,0) [0|9.22337203685478E+018] "" Vector__XXX
 SG_ SYS_r5_3_FL : 135|64@0+ (1,0) [0|9.22337203685478E+018] "" Vector__XXX
 SG_ SYS_r5_2_FL : 71|64@0+ (1,0) [0|9.22337203685478E+018] "" Vector__XXX
 SG_ SYS_r5_1_FL : 7|56@0+ (1,0) [0|7.20575940379279E+016] "" Vector__XXX

BO_ 519 Debug_target_RR: 64 RR
 SG_ Debug_target_info8_RR : 455|64@0+ (1,0) [0|1.84467440737096E+019] "" Vector__XXX
 SG_ Debug_target_info7_RR : 391|64@0+ (1,0) [0|1.84467440737096E+019] "" Vector__XXX
 SG_ Debug_target_info6_RR : 327|64@0+ (1,0) [0|1.84467440737096E+019] "" Vector__XXX
 SG_ Debug_target_info5_RR : 263|64@0+ (1,0) [0|1.84467440737096E+019] "" Vector__XXX
 SG_ Debug_target_info4_RR : 199|64@0+ (1,0) [0|1.84467440737096E+019] "" Vector__XXX
 SG_ Debug_target_info3_RR : 135|64@0+ (1,0) [0|1.84467440737096E+019] "" Vector__XXX
 SG_ Debug_target_info2_RR : 71|64@0+ (1,0) [0|1.84467440737096E+019] "" Vector__XXX
 SG_ Debug_target_info1_RR : 7|64@0+ (1,0) [0|1.84467440737096E+019] "" Vector__XXX

BO_ 518 Debug_target_RL: 64 RL
 SG_ Debug_target_info8_RL : 455|64@0+ (1,0) [0|1.84467440737096E+019] "" Vector__XXX
 SG_ Debug_target_info7_RL : 391|64@0+ (1,0) [0|1.84467440737096E+019] "" Vector__XXX
 SG_ Debug_target_info6_RL : 327|64@0+ (1,0) [0|1.84467440737096E+019] "" Vector__XXX
 SG_ Debug_target_info5_RL : 263|64@0+ (1,0) [0|1.84467440737096E+019] "" Vector__XXX
 SG_ Debug_target_info4_RL : 199|64@0+ (1,0) [0|1.84467440737096E+019] "" Vector__XXX
 SG_ Debug_target_info3_RL : 135|64@0+ (1,0) [0|1.84467440737096E+019] "" Vector__XXX
 SG_ Debug_target_info2_RL : 71|64@0+ (1,0) [0|1.84467440737096E+019] "" Vector__XXX
 SG_ Debug_target_info1_RL : 7|64@0+ (1,0) [0|1.84467440737096E+019] "" Vector__XXX

BO_ 517 Debug_point_RR: 64 RR
 SG_ Debug_point_info8_RR : 455|64@0+ (1,0) [0|1.84467440737096E+019] "" Vector__XXX
 SG_ Debug_point_info7_RR : 391|64@0+ (1,0) [0|1.84467440737096E+019] "" Vector__XXX
 SG_ Debug_point_info6_RR : 327|64@0+ (1,0) [0|1.84467440737096E+019] "" Vector__XXX
 SG_ Debug_point_info5_RR : 263|64@0+ (1,0) [0|1.84467440737096E+019] "" Vector__XXX
 SG_ Debug_point_info4_RR : 199|64@0+ (1,0) [0|1.84467440737096E+019] "" Vector__XXX
 SG_ Debug_point_info3_RR : 135|64@0+ (1,0) [0|1.84467440737096E+019] "" Vector__XXX
 SG_ Debug_point_info2_RR : 71|64@0+ (1,0) [0|1.84467440737096E+019] "" Vector__XXX
 SG_ Debug_point_info1_RR : 7|64@0+ (1,0) [0|1.84467440737096E+019] "" Vector__XXX

BO_ 516 Debug_point_RL: 64 RL
 SG_ Debug_point_info8_RL : 455|64@0+ (1,0) [0|1.84467440737096E+019] "" Vector__XXX
 SG_ Debug_point_info7_RL : 391|64@0+ (1,0) [0|1.84467440737096E+019] "" Vector__XXX
 SG_ Debug_point_info6_RL : 327|64@0+ (1,0) [0|1.84467440737096E+019] "" Vector__XXX
 SG_ Debug_point_info5_RL : 263|64@0+ (1,0) [0|1.84467440737096E+019] "" Vector__XXX
 SG_ Debug_point_info4_RL : 199|64@0+ (1,0) [0|1.84467440737096E+019] "" Vector__XXX
 SG_ Debug_point_info3_RL : 135|64@0+ (1,0) [0|1.84467440737096E+019] "" Vector__XXX
 SG_ Debug_point_info2_RL : 71|64@0+ (1,0) [0|1.84467440737096E+019] "" Vector__XXX
 SG_ Debug_point_info1_RL : 7|64@0+ (1,0) [0|1.84467440737096E+019] "" Vector__XXX

BO_ 515 Debug_point_FR: 64 FR
 SG_ Debug_point_info8_FR : 455|64@0+ (1,0) [0|1.84467440737096E+019] "" Vector__XXX
 SG_ Debug_point_info7_FR : 391|64@0+ (1,0) [0|1.84467440737096E+019] "" Vector__XXX
 SG_ Debug_point_info6_FR : 327|64@0+ (1,0) [0|1.84467440737096E+019] "" Vector__XXX
 SG_ Debug_point_info5_FR : 263|64@0+ (1,0) [0|1.84467440737096E+019] "" Vector__XXX
 SG_ Debug_point_info4_FR : 199|64@0+ (1,0) [0|1.84467440737096E+019] "" Vector__XXX
 SG_ Debug_point_info3_FR : 135|64@0+ (1,0) [0|1.84467440737096E+019] "" Vector__XXX
 SG_ Debug_point_info2_FR : 71|64@0+ (1,0) [0|1.84467440737096E+019] "" Vector__XXX
 SG_ Debug_point_info1_FR : 7|64@0+ (1,0) [0|1.84467440737096E+019] "" Vector__XXX

BO_ 513 Debug_target_FL: 64 FL
 SG_ Debug_target_info8_FL : 455|64@0+ (1,0) [0|1.84467440737096E+019] "" Vector__XXX
 SG_ Debug_target_info7_FL : 391|64@0+ (1,0) [0|1.84467440737096E+019] "" Vector__XXX
 SG_ Debug_target_info6_FL : 327|64@0+ (1,0) [0|1.84467440737096E+019] "" Vector__XXX
 SG_ Debug_target_info5_FL : 263|64@0+ (1,0) [0|1.84467440737096E+019] "" Vector__XXX
 SG_ Debug_target_info4_FL : 199|64@0+ (1,0) [0|1.84467440737096E+019] "" Vector__XXX
 SG_ Debug_target_info3_FL : 135|64@0+ (1,0) [0|1.84467440737096E+019] "" Vector__XXX
 SG_ Debug_target_info2_FL : 71|64@0+ (1,0) [0|1.84467440737096E+019] "" Vector__XXX
 SG_ Debug_target_info1_FL : 7|64@0+ (1,0) [0|1.84467440737096E+019] "" Vector__XXX

BO_ 514 Debug_target_FR: 64 FR
 SG_ Debug_target_info8_FR : 455|64@0+ (1,0) [0|1.84467440737096E+019] "" Vector__XXX
 SG_ Debug_target_info7_FR : 391|64@0+ (1,0) [0|1.84467440737096E+019] "" Vector__XXX
 SG_ Debug_target_info6_FR : 327|64@0+ (1,0) [0|1.84467440737096E+019] "" Vector__XXX
 SG_ Debug_target_info5_FR : 263|64@0+ (1,0) [0|1.84467440737096E+019] "" Vector__XXX
 SG_ Debug_target_info4_FR : 199|64@0+ (1,0) [0|1.84467440737096E+019] "" Vector__XXX
 SG_ Debug_target_info3_FR : 135|64@0+ (1,0) [0|1.84467440737096E+019] "" Vector__XXX
 SG_ Debug_target_info2_FR : 71|64@0+ (1,0) [0|1.84467440737096E+019] "" Vector__XXX
 SG_ Debug_target_info1_FR : 7|64@0+ (1,0) [0|1.84467440737096E+019] "" Vector__XXX

BO_ 512 Debug_point_FL: 64 FL
 SG_ Debug_point_info8_FL : 455|64@0+ (1,0) [0|1.84467440737096E+019] "" Vector__XXX
 SG_ Debug_point_info7_FL : 391|64@0+ (1,0) [0|1.84467440737096E+019] "" Vector__XXX
 SG_ Debug_point_info6_FL : 327|64@0+ (1,0) [0|1.84467440737096E+019] "" Vector__XXX
 SG_ Debug_point_info5_FL : 263|64@0+ (1,0) [0|1.84467440737096E+019] "" Vector__XXX
 SG_ Debug_point_info4_FL : 199|64@0+ (1,0) [0|1.84467440737096E+019] "" Vector__XXX
 SG_ Debug_point_info3_FL : 135|64@0+ (1,0) [0|1.84467440737096E+019] "" Vector__XXX
 SG_ Debug_point_info2_FL : 71|64@0+ (1,0) [0|1.84467440737096E+019] "" Vector__XXX
 SG_ Debug_point_info1_FL : 7|64@0+ (1,0) [0|1.84467440737096E+019] "" Vector__XXX

BO_ 1535 ObjectList_Obj32_RR: 64 RR
 SG_ RSDS_RR_PER_OBJ32_YawRate : 279|16@0+ (0.002,-3.14) [-3.14|127.93] "" Vector__XXX
 SG_ RSDS_RR_PER_OBJ32_Width : 263|16@0+ (0.01,0) [0|655.35] "" Vector__XXX
 SG_ RSDS_RR_PER_OBJ32_ValidFlag : 97|1@0+ (1,0) [0|1] "" Vector__XXX
 SG_ RSDS_RR_PER_OBJ32_ObstProbabilit : 255|8@0+ (1,0) [0|255] "" Vector__XXX
 SG_ RSDS_RR_PER_OBJ32_MotionType : 247|3@0+ (1,0) [0|7] "" Vector__XXX
 SG_ RSDS_RR_PER_OBJ32_MeasState : 99|2@0+ (1,0) [0|3] "" Vector__XXX
 SG_ RSDS_RR_PER_OBJ32_LifeCycle : 223|8@0+ (1,0) [0|255] "" Vector__XXX
 SG_ RSDS_RR_PER_OBJ32_Length : 231|16@0+ (0.05,0) [0|3276.75] "" Vector__XXX
 SG_ RSDS_RR_PER_OBJ32_ID : 215|8@0+ (1,0) [0|255] "" Vector__XXX
 SG_ RSDS_RR_PER_OBJ32_HeadingAng : 199|16@0+ (0.002,-3.14) [-3.14|127.93] "" Vector__XXX
 SG_ RSDS_RR_PER_OBJ32_ExistProb : 191|8@0+ (0.03326,0) [0|8.4813] "" Vector__XXX
 SG_ RSDS_RR_PER_OBJ32_DistZStd : 183|8@0+ (0.1,0) [0|25.5] "" Vector__XXX
 SG_ RSDS_RR_PER_OBJ32_DistZ : 167|16@0+ (0.125,-64) [-64|8127.875] "" Vector__XXX
 SG_ RSDS_RR_PER_OBJ32_DistYStd : 143|8@0+ (0.1,0) [0|25.5] "" Vector__XXX
 SG_ RSDS_RR_PER_OBJ32_DistY : 151|16@0+ (0.125,-256) [-256|7935.875] "" Vector__XXX
 SG_ RSDS_RR_PER_OBJ32_DistXStd : 135|8@0+ (0.1,0) [0|25.5] "" Vector__XXX
 SG_ RSDS_RR_PER_OBJ32_DistX : 119|16@0+ (0.0625,-256) [-256|3839.9375] "" Vector__XXX
 SG_ RSDS_RR_PER_OBJ32_ClassTypeProb : 111|8@0+ (1,0) [0|255] "" Vector__XXX
 SG_ RSDS_RR_PER_OBJ32_ClassType : 103|4@0+ (1,0) [0|15] "" Vector__XXX
 SG_ RSDS_RR_PER_OBJ32_AbsVelYStd : 79|8@0+ (0.0625,0) [0|15.9375] "" Vector__XXX
 SG_ RSDS_RR_PER_OBJ32_AbsVelY : 87|16@0+ (0.0312,-128) [-128|1916.692] "" Vector__XXX
 SG_ RSDS_RR_PER_OBJ32_AbsVelXStd : 71|8@0+ (0.0625,0) [0|15.9375] "" Vector__XXX
 SG_ RSDS_RR_PER_OBJ32_AbsVelX : 55|16@0+ (0.0312,-128) [-128|1916.692] "" Vector__XXX
 SG_ RSDS_RR_PER_OBJ32_AbsAccelYStd : 31|8@0+ (0.0625,0) [0|15.9375] "" Vector__XXX
 SG_ RSDS_RR_PER_OBJ32_AbsAccelY : 39|16@0+ (0.03125,-16) [-16|2031.96875] "" Vector__XXX
 SG_ RSDS_RR_PER_OBJ32_AbsAccelXStd : 23|8@0+ (0.0625,0) [0|15.9375] "" Vector__XXX
 SG_ RSDS_RR_PER_OBJ32_AbsAccelX : 7|16@0+ (0.03125,-16) [-16|2031.96875] "" Vector__XXX

BO_ 1534 ObjectList_Obj31_RR: 64 RR
 SG_ RSDS_RR_PER_OBJ31_YawRate : 279|16@0+ (0.002,-3.14) [-3.14|127.93] "" Vector__XXX
 SG_ RSDS_RR_PER_OBJ31_Width : 263|16@0+ (0.01,0) [0|655.35] "" Vector__XXX
 SG_ RSDS_RR_PER_OBJ31_ValidFlag : 97|1@0+ (1,0) [0|1] "" Vector__XXX
 SG_ RSDS_RR_PER_OBJ31_ObstProbabilit : 255|8@0+ (1,0) [0|255] "" Vector__XXX
 SG_ RSDS_RR_PER_OBJ31_MotionType : 247|3@0+ (1,0) [0|7] "" Vector__XXX
 SG_ RSDS_RR_PER_OBJ31_MeasState : 99|2@0+ (1,0) [0|3] "" Vector__XXX
 SG_ RSDS_RR_PER_OBJ31_LifeCycle : 223|8@0+ (1,0) [0|255] "" Vector__XXX
 SG_ RSDS_RR_PER_OBJ31_Length : 231|16@0+ (0.05,0) [0|3276.75] "" Vector__XXX
 SG_ RSDS_RR_PER_OBJ31_ID : 215|8@0+ (1,0) [0|255] "" Vector__XXX
 SG_ RSDS_RR_PER_OBJ31_HeadingAng : 199|16@0+ (0.002,-3.14) [-3.14|127.93] "" Vector__XXX
 SG_ RSDS_RR_PER_OBJ31_ExistProb : 191|8@0+ (0.03326,0) [0|8.4813] "" Vector__XXX
 SG_ RSDS_RR_PER_OBJ31_DistZStd : 183|8@0+ (0.1,0) [0|25.5] "" Vector__XXX
 SG_ RSDS_RR_PER_OBJ31_DistZ : 167|16@0+ (0.125,-64) [-64|8127.875] "" Vector__XXX
 SG_ RSDS_RR_PER_OBJ31_DistYStd : 143|8@0+ (0.1,0) [0|25.5] "" Vector__XXX
 SG_ RSDS_RR_PER_OBJ31_DistY : 151|16@0+ (0.125,-256) [-256|7935.875] "" Vector__XXX
 SG_ RSDS_RR_PER_OBJ31_DistXStd : 135|8@0+ (0.1,0) [0|25.5] "" Vector__XXX
 SG_ RSDS_RR_PER_OBJ31_DistX : 119|16@0+ (0.0625,-256) [-256|3839.9375] "" Vector__XXX
 SG_ RSDS_RR_PER_OBJ31_ClassTypeProb : 111|8@0+ (1,0) [0|255] "" Vector__XXX
 SG_ RSDS_RR_PER_OBJ31_ClassType : 103|4@0+ (1,0) [0|15] "" Vector__XXX
 SG_ RSDS_RR_PER_OBJ31_AbsVelYStd : 79|8@0+ (0.0625,0) [0|15.9375] "" Vector__XXX
 SG_ RSDS_RR_PER_OBJ31_AbsVelY : 87|16@0+ (0.0312,-128) [-128|1916.692] "" Vector__XXX
 SG_ RSDS_RR_PER_OBJ31_AbsVelXStd : 71|8@0+ (0.0625,0) [0|15.9375] "" Vector__XXX
 SG_ RSDS_RR_PER_OBJ31_AbsVelX : 55|16@0+ (0.0312,-128) [-128|1916.692] "" Vector__XXX
 SG_ RSDS_RR_PER_OBJ31_AbsAccelYStd : 31|8@0+ (0.0625,0) [0|15.9375] "" Vector__XXX
 SG_ RSDS_RR_PER_OBJ31_AbsAccelY : 39|16@0+ (0.03125,-16) [-16|2031.96875] "" Vector__XXX
 SG_ RSDS_RR_PER_OBJ31_AbsAccelXStd : 23|8@0+ (0.0625,0) [0|15.9375] "" Vector__XXX
 SG_ RSDS_RR_PER_OBJ31_AbsAccelX : 7|16@0+ (0.03125,-16) [-16|2031.96875] "" Vector__XXX

BO_ 1533 ObjectList_Obj30_RR: 64 RR
 SG_ RSDS_RR_PER_OBJ30_YawRate : 279|16@0+ (0.002,-3.14) [-3.14|127.93] "" Vector__XXX
 SG_ RSDS_RR_PER_OBJ30_Width : 263|16@0+ (0.01,0) [0|655.35] "" Vector__XXX
 SG_ RSDS_RR_PER_OBJ30_ValidFlag : 97|1@0+ (1,0) [0|1] "" Vector__XXX
 SG_ RSDS_RR_PER_OBJ30_ObstProbabilit : 255|8@0+ (1,0) [0|255] "" Vector__XXX
 SG_ RSDS_RR_PER_OBJ30_MotionType : 247|3@0+ (1,0) [0|7] "" Vector__XXX
 SG_ RSDS_RR_PER_OBJ30_MeasState : 99|2@0+ (1,0) [0|3] "" Vector__XXX
 SG_ RSDS_RR_PER_OBJ30_LifeCycle : 223|8@0+ (1,0) [0|255] "" Vector__XXX
 SG_ RSDS_RR_PER_OBJ30_Length : 231|16@0+ (0.05,0) [0|3276.75] "" Vector__XXX
 SG_ RSDS_RR_PER_OBJ30_ID : 215|8@0+ (1,0) [0|255] "" Vector__XXX
 SG_ RSDS_RR_PER_OBJ30_HeadingAng : 199|16@0+ (0.002,-3.14) [-3.14|127.93] "" Vector__XXX
 SG_ RSDS_RR_PER_OBJ30_ExistProb : 191|8@0+ (0.03326,0) [0|8.4813] "" Vector__XXX
 SG_ RSDS_RR_PER_OBJ30_DistZStd : 183|8@0+ (0.1,0) [0|25.5] "" Vector__XXX
 SG_ RSDS_RR_PER_OBJ30_DistZ : 167|16@0+ (0.125,-64) [-64|8127.875] "" Vector__XXX
 SG_ RSDS_RR_PER_OBJ30_DistYStd : 143|8@0+ (0.1,0) [0|25.5] "" Vector__XXX
 SG_ RSDS_RR_PER_OBJ30_DistY : 151|16@0+ (0.125,-256) [-256|7935.875] "" Vector__XXX
 SG_ RSDS_RR_PER_OBJ30_DistXStd : 135|8@0+ (0.1,0) [0|25.5] "" Vector__XXX
 SG_ RSDS_RR_PER_OBJ30_DistX : 119|16@0+ (0.0625,-256) [-256|3839.9375] "" Vector__XXX
 SG_ RSDS_RR_PER_OBJ30_ClassTypeProb : 111|8@0+ (1,0) [0|255] "" Vector__XXX
 SG_ RSDS_RR_PER_OBJ30_ClassType : 103|4@0+ (1,0) [0|15] "" Vector__XXX
 SG_ RSDS_RR_PER_OBJ30_AbsVelYStd : 79|8@0+ (0.0625,0) [0|15.9375] "" Vector__XXX
 SG_ RSDS_RR_PER_OBJ30_AbsVelY : 87|16@0+ (0.0312,-128) [-128|1916.692] "" Vector__XXX
 SG_ RSDS_RR_PER_OBJ30_AbsVelXStd : 71|8@0+ (0.0625,0) [0|15.9375] "" Vector__XXX
 SG_ RSDS_RR_PER_OBJ30_AbsVelX : 55|16@0+ (0.0312,-128) [-128|1916.692] "" Vector__XXX
 SG_ RSDS_RR_PER_OBJ30_AbsAccelYStd : 31|8@0+ (0.0625,0) [0|15.9375] "" Vector__XXX
 SG_ RSDS_RR_PER_OBJ30_AbsAccelY : 39|16@0+ (0.03125,-16) [-16|2031.96875] "" Vector__XXX
 SG_ RSDS_RR_PER_OBJ30_AbsAccelXStd : 23|8@0+ (0.0625,0) [0|15.9375] "" Vector__XXX
 SG_ RSDS_RR_PER_OBJ30_AbsAccelX : 7|16@0+ (0.03125,-16) [-16|2031.96875] "" Vector__XXX

BO_ 1532 ObjectList_Obj29_RR: 64 RR
 SG_ RSDS_RR_PER_OBJ29_YawRate : 279|16@0+ (0.002,-3.14) [-3.14|127.93] "" Vector__XXX
 SG_ RSDS_RR_PER_OBJ29_Width : 263|16@0+ (0.01,0) [0|655.35] "" Vector__XXX
 SG_ RSDS_RR_PER_OBJ29_ValidFlag : 97|1@0+ (1,0) [0|1] "" Vector__XXX
 SG_ RSDS_RR_PER_OBJ29_ObstProbabilit : 255|8@0+ (1,0) [0|255] "" Vector__XXX
 SG_ RSDS_RR_PER_OBJ29_MotionType : 247|3@0+ (1,0) [0|7] "" Vector__XXX
 SG_ RSDS_RR_PER_OBJ29_MeasState : 99|2@0+ (1,0) [0|3] "" Vector__XXX
 SG_ RSDS_RR_PER_OBJ29_LifeCycle : 223|8@0+ (1,0) [0|255] "" Vector__XXX
 SG_ RSDS_RR_PER_OBJ29_Length : 231|16@0+ (0.05,0) [0|3276.75] "" Vector__XXX
 SG_ RSDS_RR_PER_OBJ29_ID : 215|8@0+ (1,0) [0|255] "" Vector__XXX
 SG_ RSDS_RR_PER_OBJ29_HeadingAng : 199|16@0+ (0.002,-3.14) [-3.14|127.93] "" Vector__XXX
 SG_ RSDS_RR_PER_OBJ29_ExistProb : 191|8@0+ (0.03326,0) [0|8.4813] "" Vector__XXX
 SG_ RSDS_RR_PER_OBJ29_DistZStd : 183|8@0+ (0.1,0) [0|25.5] "" Vector__XXX
 SG_ RSDS_RR_PER_OBJ29_DistZ : 167|16@0+ (0.125,-64) [-64|8127.875] "" Vector__XXX
 SG_ RSDS_RR_PER_OBJ29_DistYStd : 143|8@0+ (0.1,0) [0|25.5] "" Vector__XXX
 SG_ RSDS_RR_PER_OBJ29_DistY : 151|16@0+ (0.125,-256) [-256|7935.875] "" Vector__XXX
 SG_ RSDS_RR_PER_OBJ29_DistXStd : 135|8@0+ (0.1,0) [0|25.5] "" Vector__XXX
 SG_ RSDS_RR_PER_OBJ29_DistX : 119|16@0+ (0.0625,-256) [-256|3839.9375] "" Vector__XXX
 SG_ RSDS_RR_PER_OBJ29_ClassTypeProb : 111|8@0+ (1,0) [0|255] "" Vector__XXX
 SG_ RSDS_RR_PER_OBJ29_ClassType : 103|4@0+ (1,0) [0|15] "" Vector__XXX
 SG_ RSDS_RR_PER_OBJ29_AbsVelYStd : 79|8@0+ (0.0625,0) [0|15.9375] "" Vector__XXX
 SG_ RSDS_RR_PER_OBJ29_AbsVelY : 87|16@0+ (0.0312,-128) [-128|1916.692] "" Vector__XXX
 SG_ RSDS_RR_PER_OBJ29_AbsVelXStd : 71|8@0+ (0.0625,0) [0|15.9375] "" Vector__XXX
 SG_ RSDS_RR_PER_OBJ29_AbsVelX : 55|16@0+ (0.0312,-128) [-128|1916.692] "" Vector__XXX
 SG_ RSDS_RR_PER_OBJ29_AbsAccelYStd : 31|8@0+ (0.0625,0) [0|15.9375] "" Vector__XXX
 SG_ RSDS_RR_PER_OBJ29_AbsAccelY : 39|16@0+ (0.03125,-16) [-16|2031.96875] "" Vector__XXX
 SG_ RSDS_RR_PER_OBJ29_AbsAccelXStd : 23|8@0+ (0.0625,0) [0|15.9375] "" Vector__XXX
 SG_ RSDS_RR_PER_OBJ29_AbsAccelX : 7|16@0+ (0.03125,-16) [-16|2031.96875] "" Vector__XXX

BO_ 1531 ObjectList_Obj28_RR: 64 RR
 SG_ RSDS_RR_PER_OBJ28_YawRate : 279|16@0+ (0.002,-3.14) [-3.14|127.93] "" Vector__XXX
 SG_ RSDS_RR_PER_OBJ28_Width : 263|16@0+ (0.01,0) [0|655.35] "" Vector__XXX
 SG_ RSDS_RR_PER_OBJ28_ValidFlag : 97|1@0+ (1,0) [0|1] "" Vector__XXX
 SG_ RSDS_RR_PER_OBJ28_ObstProbabilit : 255|8@0+ (1,0) [0|255] "" Vector__XXX
 SG_ RSDS_RR_PER_OBJ28_MotionType : 247|3@0+ (1,0) [0|7] "" Vector__XXX
 SG_ RSDS_RR_PER_OBJ28_MeasState : 99|2@0+ (1,0) [0|3] "" Vector__XXX
 SG_ RSDS_RR_PER_OBJ28_LifeCycle : 223|8@0+ (1,0) [0|255] "" Vector__XXX
 SG_ RSDS_RR_PER_OBJ28_Length : 231|16@0+ (0.05,0) [0|3276.75] "" Vector__XXX
 SG_ RSDS_RR_PER_OBJ28_ID : 215|8@0+ (1,0) [0|255] "" Vector__XXX
 SG_ RSDS_RR_PER_OBJ28_HeadingAng : 199|16@0+ (0.002,-3.14) [-3.14|127.93] "" Vector__XXX
 SG_ RSDS_RR_PER_OBJ28_ExistProb : 191|8@0+ (0.03326,0) [0|8.4813] "" Vector__XXX
 SG_ RSDS_RR_PER_OBJ28_DistZStd : 183|8@0+ (0.1,0) [0|25.5] "" Vector__XXX
 SG_ RSDS_RR_PER_OBJ28_DistZ : 167|16@0+ (0.125,-64) [-64|8127.875] "" Vector__XXX
 SG_ RSDS_RR_PER_OBJ28_DistYStd : 143|8@0+ (0.1,0) [0|25.5] "" Vector__XXX
 SG_ RSDS_RR_PER_OBJ28_DistY : 151|16@0+ (0.125,-256) [-256|7935.875] "" Vector__XXX
 SG_ RSDS_RR_PER_OBJ28_DistXStd : 135|8@0+ (0.1,0) [0|25.5] "" Vector__XXX
 SG_ RSDS_RR_PER_OBJ28_DistX : 119|16@0+ (0.0625,-256) [-256|3839.9375] "" Vector__XXX
 SG_ RSDS_RR_PER_OBJ28_ClassTypeProb : 111|8@0+ (1,0) [0|255] "" Vector__XXX
 SG_ RSDS_RR_PER_OBJ28_ClassType : 103|4@0+ (1,0) [0|15] "" Vector__XXX
 SG_ RSDS_RR_PER_OBJ28_AbsVelYStd : 79|8@0+ (0.0625,0) [0|15.9375] "" Vector__XXX
 SG_ RSDS_RR_PER_OBJ28_AbsVelY : 87|16@0+ (0.0312,-128) [-128|1916.692] "" Vector__XXX
 SG_ RSDS_RR_PER_OBJ28_AbsVelXStd : 71|8@0+ (0.0625,0) [0|15.9375] "" Vector__XXX
 SG_ RSDS_RR_PER_OBJ28_AbsVelX : 55|16@0+ (0.0312,-128) [-128|1916.692] "" Vector__XXX
 SG_ RSDS_RR_PER_OBJ28_AbsAccelYStd : 31|8@0+ (0.0625,0) [0|15.9375] "" Vector__XXX
 SG_ RSDS_RR_PER_OBJ28_AbsAccelY : 39|16@0+ (0.03125,-16) [-16|2031.96875] "" Vector__XXX
 SG_ RSDS_RR_PER_OBJ28_AbsAccelXStd : 23|8@0+ (0.0625,0) [0|15.9375] "" Vector__XXX
 SG_ RSDS_RR_PER_OBJ28_AbsAccelX : 7|16@0+ (0.03125,-16) [-16|2031.96875] "" Vector__XXX

BO_ 1530 ObjectList_Obj27_RR: 64 RR
 SG_ RSDS_RR_PER_OBJ27_YawRate : 279|16@0+ (0.002,-3.14) [-3.14|127.93] "" Vector__XXX
 SG_ RSDS_RR_PER_OBJ27_Width : 263|16@0+ (0.01,0) [0|655.35] "" Vector__XXX
 SG_ RSDS_RR_PER_OBJ27_ValidFlag : 97|1@0+ (1,0) [0|1] "" Vector__XXX
 SG_ RSDS_RR_PER_OBJ27_ObstProbabilit : 255|8@0+ (1,0) [0|255] "" Vector__XXX
 SG_ RSDS_RR_PER_OBJ27_MotionType : 247|3@0+ (1,0) [0|7] "" Vector__XXX
 SG_ RSDS_RR_PER_OBJ27_MeasState : 99|2@0+ (1,0) [0|3] "" Vector__XXX
 SG_ RSDS_RR_PER_OBJ27_LifeCycle : 223|8@0+ (1,0) [0|255] "" Vector__XXX
 SG_ RSDS_RR_PER_OBJ27_Length : 231|16@0+ (0.05,0) [0|3276.75] "" Vector__XXX
 SG_ RSDS_RR_PER_OBJ27_ID : 215|8@0+ (1,0) [0|255] "" Vector__XXX
 SG_ RSDS_RR_PER_OBJ27_HeadingAng : 199|16@0+ (0.002,-3.14) [-3.14|127.93] "" Vector__XXX
 SG_ RSDS_RR_PER_OBJ27_ExistProb : 191|8@0+ (0.03326,0) [0|8.4813] "" Vector__XXX
 SG_ RSDS_RR_PER_OBJ27_DistZStd : 183|8@0+ (0.1,0) [0|25.5] "" Vector__XXX
 SG_ RSDS_RR_PER_OBJ27_DistZ : 167|16@0+ (0.125,-64) [-64|8127.875] "" Vector__XXX
 SG_ RSDS_RR_PER_OBJ27_DistYStd : 143|8@0+ (0.1,0) [0|25.5] "" Vector__XXX
 SG_ RSDS_RR_PER_OBJ27_DistY : 151|16@0+ (0.125,-256) [-256|7935.875] "" Vector__XXX
 SG_ RSDS_RR_PER_OBJ27_DistXStd : 135|8@0+ (0.1,0) [0|25.5] "" Vector__XXX
 SG_ RSDS_RR_PER_OBJ27_DistX : 119|16@0+ (0.0625,-256) [-256|3839.9375] "" Vector__XXX
 SG_ RSDS_RR_PER_OBJ27_ClassTypeProb : 111|8@0+ (1,0) [0|255] "" Vector__XXX
 SG_ RSDS_RR_PER_OBJ27_ClassType : 103|4@0+ (1,0) [0|15] "" Vector__XXX
 SG_ RSDS_RR_PER_OBJ27_AbsVelYStd : 79|8@0+ (0.0625,0) [0|15.9375] "" Vector__XXX
 SG_ RSDS_RR_PER_OBJ27_AbsVelY : 87|16@0+ (0.0312,-128) [-128|1916.692] "" Vector__XXX
 SG_ RSDS_RR_PER_OBJ27_AbsVelXStd : 71|8@0+ (0.0625,0) [0|15.9375] "" Vector__XXX
 SG_ RSDS_RR_PER_OBJ27_AbsVelX : 55|16@0+ (0.0312,-128) [-128|1916.692] "" Vector__XXX
 SG_ RSDS_RR_PER_OBJ27_AbsAccelYStd : 31|8@0+ (0.0625,0) [0|15.9375] "" Vector__XXX
 SG_ RSDS_RR_PER_OBJ27_AbsAccelY : 39|16@0+ (0.03125,-16) [-16|2031.96875] "" Vector__XXX
 SG_ RSDS_RR_PER_OBJ27_AbsAccelXStd : 23|8@0+ (0.0625,0) [0|15.9375] "" Vector__XXX
 SG_ RSDS_RR_PER_OBJ27_AbsAccelX : 7|16@0+ (0.03125,-16) [-16|2031.96875] "" Vector__XXX

BO_ 1529 ObjectList_Obj26_RR: 64 RR
 SG_ RSDS_RR_PER_OBJ26_YawRate : 279|16@0+ (0.002,-3.14) [-3.14|127.93] "" Vector__XXX
 SG_ RSDS_RR_PER_OBJ26_Width : 263|16@0+ (0.01,0) [0|655.35] "" Vector__XXX
 SG_ RSDS_RR_PER_OBJ26_ValidFlag : 97|1@0+ (1,0) [0|1] "" Vector__XXX
 SG_ RSDS_RR_PER_OBJ26_ObstProbabilit : 255|8@0+ (1,0) [0|255] "" Vector__XXX
 SG_ RSDS_RR_PER_OBJ26_MotionType : 247|3@0+ (1,0) [0|7] "" Vector__XXX
 SG_ RSDS_RR_PER_OBJ26_MeasState : 99|2@0+ (1,0) [0|3] "" Vector__XXX
 SG_ RSDS_RR_PER_OBJ26_LifeCycle : 223|8@0+ (1,0) [0|255] "" Vector__XXX
 SG_ RSDS_RR_PER_OBJ26_Length : 231|16@0+ (0.05,0) [0|3276.75] "" Vector__XXX
 SG_ RSDS_RR_PER_OBJ26_ID : 215|8@0+ (1,0) [0|255] "" Vector__XXX
 SG_ RSDS_RR_PER_OBJ26_HeadingAng : 199|16@0+ (0.002,-3.14) [-3.14|127.93] "" Vector__XXX
 SG_ RSDS_RR_PER_OBJ26_ExistProb : 191|8@0+ (0.03326,0) [0|8.4813] "" Vector__XXX
 SG_ RSDS_RR_PER_OBJ26_DistZStd : 183|8@0+ (0.1,0) [0|25.5] "" Vector__XXX
 SG_ RSDS_RR_PER_OBJ26_DistZ : 167|16@0+ (0.125,-64) [-64|8127.875] "" Vector__XXX
 SG_ RSDS_RR_PER_OBJ26_DistYStd : 143|8@0+ (0.1,0) [0|25.5] "" Vector__XXX
 SG_ RSDS_RR_PER_OBJ26_DistY : 151|16@0+ (0.125,-256) [-256|7935.875] "" Vector__XXX
 SG_ RSDS_RR_PER_OBJ26_DistXStd : 135|8@0+ (0.1,0) [0|25.5] "" Vector__XXX
 SG_ RSDS_RR_PER_OBJ26_DistX : 119|16@0+ (0.0625,-256) [-256|3839.9375] "" Vector__XXX
 SG_ RSDS_RR_PER_OBJ26_ClassTypeProb : 111|8@0+ (1,0) [0|255] "" Vector__XXX
 SG_ RSDS_RR_PER_OBJ26_ClassType : 103|4@0+ (1,0) [0|15] "" Vector__XXX
 SG_ RSDS_RR_PER_OBJ26_AbsVelYStd : 79|8@0+ (0.0625,0) [0|15.9375] "" Vector__XXX
 SG_ RSDS_RR_PER_OBJ26_AbsVelY : 87|16@0+ (0.0312,-128) [-128|1916.692] "" Vector__XXX
 SG_ RSDS_RR_PER_OBJ26_AbsVelXStd : 71|8@0+ (0.0625,0) [0|15.9375] "" Vector__XXX
 SG_ RSDS_RR_PER_OBJ26_AbsVelX : 55|16@0+ (0.0312,-128) [-128|1916.692] "" Vector__XXX
 SG_ RSDS_RR_PER_OBJ26_AbsAccelYStd : 31|8@0+ (0.0625,0) [0|15.9375] "" Vector__XXX
 SG_ RSDS_RR_PER_OBJ26_AbsAccelY : 39|16@0+ (0.03125,-16) [-16|2031.96875] "" Vector__XXX
 SG_ RSDS_RR_PER_OBJ26_AbsAccelXStd : 23|8@0+ (0.0625,0) [0|15.9375] "" Vector__XXX
 SG_ RSDS_RR_PER_OBJ26_AbsAccelX : 7|16@0+ (0.03125,-16) [-16|2031.96875] "" Vector__XXX

BO_ 1528 ObjectList_Obj25_RR: 64 RR
 SG_ RSDS_RR_PER_OBJ25_YawRate : 279|16@0+ (0.002,-3.14) [-3.14|127.93] "" Vector__XXX
 SG_ RSDS_RR_PER_OBJ25_Width : 263|16@0+ (0.01,0) [0|655.35] "" Vector__XXX
 SG_ RSDS_RR_PER_OBJ25_ValidFlag : 97|1@0+ (1,0) [0|1] "" Vector__XXX
 SG_ RSDS_RR_PER_OBJ25_ObstProbabilit : 255|8@0+ (1,0) [0|255] "" Vector__XXX
 SG_ RSDS_RR_PER_OBJ25_MotionType : 247|3@0+ (1,0) [0|7] "" Vector__XXX
 SG_ RSDS_RR_PER_OBJ25_MeasState : 99|2@0+ (1,0) [0|3] "" Vector__XXX
 SG_ RSDS_RR_PER_OBJ25_LifeCycle : 223|8@0+ (1,0) [0|255] "" Vector__XXX
 SG_ RSDS_RR_PER_OBJ25_Length : 231|16@0+ (0.05,0) [0|3276.75] "" Vector__XXX
 SG_ RSDS_RR_PER_OBJ25_ID : 215|8@0+ (1,0) [0|255] "" Vector__XXX
 SG_ RSDS_RR_PER_OBJ25_HeadingAng : 199|16@0+ (0.002,-3.14) [-3.14|127.93] "" Vector__XXX
 SG_ RSDS_RR_PER_OBJ25_ExistProb : 191|8@0+ (0.03326,0) [0|8.4813] "" Vector__XXX
 SG_ RSDS_RR_PER_OBJ25_DistZStd : 183|8@0+ (0.1,0) [0|25.5] "" Vector__XXX
 SG_ RSDS_RR_PER_OBJ25_DistZ : 167|16@0+ (0.125,-64) [-64|8127.875] "" Vector__XXX
 SG_ RSDS_RR_PER_OBJ25_DistYStd : 143|8@0+ (0.1,0) [0|25.5] "" Vector__XXX
 SG_ RSDS_RR_PER_OBJ25_DistY : 151|16@0+ (0.125,-256) [-256|7935.875] "" Vector__XXX
 SG_ RSDS_RR_PER_OBJ25_DistXStd : 135|8@0+ (0.1,0) [0|25.5] "" Vector__XXX
 SG_ RSDS_RR_PER_OBJ25_DistX : 119|16@0+ (0.0625,-256) [-256|3839.9375] "" Vector__XXX
 SG_ RSDS_RR_PER_OBJ25_ClassTypeProb : 111|8@0+ (1,0) [0|255] "" Vector__XXX
 SG_ RSDS_RR_PER_OBJ25_ClassType : 103|4@0+ (1,0) [0|15] "" Vector__XXX
 SG_ RSDS_RR_PER_OBJ25_AbsVelYStd : 79|8@0+ (0.0625,0) [0|15.9375] "" Vector__XXX
 SG_ RSDS_RR_PER_OBJ25_AbsVelY : 87|16@0+ (0.0312,-128) [-128|1916.692] "" Vector__XXX
 SG_ RSDS_RR_PER_OBJ25_AbsVelXStd : 71|8@0+ (0.0625,0) [0|15.9375] "" Vector__XXX
 SG_ RSDS_RR_PER_OBJ25_AbsVelX : 55|16@0+ (0.0312,-128) [-128|1916.692] "" Vector__XXX
 SG_ RSDS_RR_PER_OBJ25_AbsAccelYStd : 31|8@0+ (0.0625,0) [0|15.9375] "" Vector__XXX
 SG_ RSDS_RR_PER_OBJ25_AbsAccelY : 39|16@0+ (0.03125,-16) [-16|2031.96875] "" Vector__XXX
 SG_ RSDS_RR_PER_OBJ25_AbsAccelXStd : 23|8@0+ (0.0625,0) [0|15.9375] "" Vector__XXX
 SG_ RSDS_RR_PER_OBJ25_AbsAccelX : 7|16@0+ (0.03125,-16) [-16|2031.96875] "" Vector__XXX

BO_ 1527 ObjectList_Obj24_RR: 64 RR
 SG_ RSDS_RR_PER_OBJ24_YawRate : 279|16@0+ (0.002,-3.14) [-3.14|127.93] "" Vector__XXX
 SG_ RSDS_RR_PER_OBJ24_Width : 263|16@0+ (0.01,0) [0|655.35] "" Vector__XXX
 SG_ RSDS_RR_PER_OBJ24_ValidFlag : 97|1@0+ (1,0) [0|1] "" Vector__XXX
 SG_ RSDS_RR_PER_OBJ24_ObstProbabilit : 255|8@0+ (1,0) [0|255] "" Vector__XXX
 SG_ RSDS_RR_PER_OBJ24_MotionType : 247|3@0+ (1,0) [0|7] "" Vector__XXX
 SG_ RSDS_RR_PER_OBJ24_MeasState : 99|2@0+ (1,0) [0|3] "" Vector__XXX
 SG_ RSDS_RR_PER_OBJ24_LifeCycle : 223|8@0+ (1,0) [0|255] "" Vector__XXX
 SG_ RSDS_RR_PER_OBJ24_Length : 231|16@0+ (0.05,0) [0|3276.75] "" Vector__XXX
 SG_ RSDS_RR_PER_OBJ24_ID : 215|8@0+ (1,0) [0|255] "" Vector__XXX
 SG_ RSDS_RR_PER_OBJ24_HeadingAng : 199|16@0+ (0.002,-3.14) [-3.14|127.93] "" Vector__XXX
 SG_ RSDS_RR_PER_OBJ24_ExistProb : 191|8@0+ (0.03326,0) [0|8.4813] "" Vector__XXX
 SG_ RSDS_RR_PER_OBJ24_DistZStd : 183|8@0+ (0.1,0) [0|25.5] "" Vector__XXX
 SG_ RSDS_RR_PER_OBJ24_DistZ : 167|16@0+ (0.125,-64) [-64|8127.875] "" Vector__XXX
 SG_ RSDS_RR_PER_OBJ24_DistYStd : 143|8@0+ (0.1,0) [0|25.5] "" Vector__XXX
 SG_ RSDS_RR_PER_OBJ24_DistY : 151|16@0+ (0.125,-256) [-256|7935.875] "" Vector__XXX
 SG_ RSDS_RR_PER_OBJ24_DistXStd : 135|8@0+ (0.1,0) [0|25.5] "" Vector__XXX
 SG_ RSDS_RR_PER_OBJ24_DistX : 119|16@0+ (0.0625,-256) [-256|3839.9375] "" Vector__XXX
 SG_ RSDS_RR_PER_OBJ24_ClassTypeProb : 111|8@0+ (1,0) [0|255] "" Vector__XXX
 SG_ RSDS_RR_PER_OBJ24_ClassType : 103|4@0+ (1,0) [0|15] "" Vector__XXX
 SG_ RSDS_RR_PER_OBJ24_AbsVelYStd : 79|8@0+ (0.0625,0) [0|15.9375] "" Vector__XXX
 SG_ RSDS_RR_PER_OBJ24_AbsVelY : 87|16@0+ (0.0312,-128) [-128|1916.692] "" Vector__XXX
 SG_ RSDS_RR_PER_OBJ24_AbsVelXStd : 71|8@0+ (0.0625,0) [0|15.9375] "" Vector__XXX
 SG_ RSDS_RR_PER_OBJ24_AbsVelX : 55|16@0+ (0.0312,-128) [-128|1916.692] "" Vector__XXX
 SG_ RSDS_RR_PER_OBJ24_AbsAccelYStd : 31|8@0+ (0.0625,0) [0|15.9375] "" Vector__XXX
 SG_ RSDS_RR_PER_OBJ24_AbsAccelY : 39|16@0+ (0.03125,-16) [-16|2031.96875] "" Vector__XXX
 SG_ RSDS_RR_PER_OBJ24_AbsAccelXStd : 23|8@0+ (0.0625,0) [0|15.9375] "" Vector__XXX
 SG_ RSDS_RR_PER_OBJ24_AbsAccelX : 7|16@0+ (0.03125,-16) [-16|2031.96875] "" Vector__XXX

BO_ 1526 ObjectList_Obj23_RR: 64 RR
 SG_ RSDS_RR_PER_OBJ23_YawRate : 279|16@0+ (0.002,-3.14) [-3.14|127.93] "" Vector__XXX
 SG_ RSDS_RR_PER_OBJ23_Width : 263|16@0+ (0.01,0) [0|655.35] "" Vector__XXX
 SG_ RSDS_RR_PER_OBJ23_ValidFlag : 97|1@0+ (1,0) [0|1] "" Vector__XXX
 SG_ RSDS_RR_PER_OBJ23_ObstProbabilit : 255|8@0+ (1,0) [0|255] "" Vector__XXX
 SG_ RSDS_RR_PER_OBJ23_MotionType : 247|3@0+ (1,0) [0|7] "" Vector__XXX
 SG_ RSDS_RR_PER_OBJ23_MeasState : 99|2@0+ (1,0) [0|3] "" Vector__XXX
 SG_ RSDS_RR_PER_OBJ23_LifeCycle : 223|8@0+ (1,0) [0|255] "" Vector__XXX
 SG_ RSDS_RR_PER_OBJ23_Length : 231|16@0+ (0.05,0) [0|3276.75] "" Vector__XXX
 SG_ RSDS_RR_PER_OBJ23_ID : 215|8@0+ (1,0) [0|255] "" Vector__XXX
 SG_ RSDS_RR_PER_OBJ23_HeadingAng : 199|16@0+ (0.002,-3.14) [-3.14|127.93] "" Vector__XXX
 SG_ RSDS_RR_PER_OBJ23_ExistProb : 191|8@0+ (0.03326,0) [0|8.4813] "" Vector__XXX
 SG_ RSDS_RR_PER_OBJ23_DistZStd : 183|8@0+ (0.1,0) [0|25.5] "" Vector__XXX
 SG_ RSDS_RR_PER_OBJ23_DistZ : 167|16@0+ (0.125,-64) [-64|8127.875] "" Vector__XXX
 SG_ RSDS_RR_PER_OBJ23_DistYStd : 143|8@0+ (0.1,0) [0|25.5] "" Vector__XXX
 SG_ RSDS_RR_PER_OBJ23_DistY : 151|16@0+ (0.125,-256) [-256|7935.875] "" Vector__XXX
 SG_ RSDS_RR_PER_OBJ23_DistXStd : 135|8@0+ (0.1,0) [0|25.5] "" Vector__XXX
 SG_ RSDS_RR_PER_OBJ23_DistX : 119|16@0+ (0.0625,-256) [-256|3839.9375] "" Vector__XXX
 SG_ RSDS_RR_PER_OBJ23_ClassTypeProb : 111|8@0+ (1,0) [0|255] "" Vector__XXX
 SG_ RSDS_RR_PER_OBJ23_ClassType : 103|4@0+ (1,0) [0|15] "" Vector__XXX
 SG_ RSDS_RR_PER_OBJ23_AbsVelYStd : 79|8@0+ (0.0625,0) [0|15.9375] "" Vector__XXX
 SG_ RSDS_RR_PER_OBJ23_AbsVelY : 87|16@0+ (0.0312,-128) [-128|1916.692] "" Vector__XXX
 SG_ RSDS_RR_PER_OBJ23_AbsVelXStd : 71|8@0+ (0.0625,0) [0|15.9375] "" Vector__XXX
 SG_ RSDS_RR_PER_OBJ23_AbsVelX : 55|16@0+ (0.0312,-128) [-128|1916.692] "" Vector__XXX
 SG_ RSDS_RR_PER_OBJ23_AbsAccelYStd : 31|8@0+ (0.0625,0) [0|15.9375] "" Vector__XXX
 SG_ RSDS_RR_PER_OBJ23_AbsAccelY : 39|16@0+ (0.03125,-16) [-16|2031.96875] "" Vector__XXX
 SG_ RSDS_RR_PER_OBJ23_AbsAccelXStd : 23|8@0+ (0.0625,0) [0|15.9375] "" Vector__XXX
 SG_ RSDS_RR_PER_OBJ23_AbsAccelX : 7|16@0+ (0.03125,-16) [-16|2031.96875] "" Vector__XXX

BO_ 1525 ObjectList_Obj22_RR: 64 RR
 SG_ RSDS_RR_PER_OBJ22_YawRate : 279|16@0+ (0.002,-3.14) [-3.14|127.93] "" Vector__XXX
 SG_ RSDS_RR_PER_OBJ22_Width : 263|16@0+ (0.01,0) [0|655.35] "" Vector__XXX
 SG_ RSDS_RR_PER_OBJ22_ValidFlag : 97|1@0+ (1,0) [0|1] "" Vector__XXX
 SG_ RSDS_RR_PER_OBJ22_ObstProbabilit : 255|8@0+ (1,0) [0|255] "" Vector__XXX
 SG_ RSDS_RR_PER_OBJ22_MotionType : 247|3@0+ (1,0) [0|7] "" Vector__XXX
 SG_ RSDS_RR_PER_OBJ22_MeasState : 99|2@0+ (1,0) [0|3] "" Vector__XXX
 SG_ RSDS_RR_PER_OBJ22_LifeCycle : 223|8@0+ (1,0) [0|255] "" Vector__XXX
 SG_ RSDS_RR_PER_OBJ22_Length : 231|16@0+ (0.05,0) [0|3276.75] "" Vector__XXX
 SG_ RSDS_RR_PER_OBJ22_ID : 215|8@0+ (1,0) [0|255] "" Vector__XXX
 SG_ RSDS_RR_PER_OBJ22_HeadingAng : 199|16@0+ (0.002,-3.14) [-3.14|127.93] "" Vector__XXX
 SG_ RSDS_RR_PER_OBJ22_ExistProb : 191|8@0+ (0.03326,0) [0|8.4813] "" Vector__XXX
 SG_ RSDS_RR_PER_OBJ22_DistZStd : 183|8@0+ (0.1,0) [0|25.5] "" Vector__XXX
 SG_ RSDS_RR_PER_OBJ22_DistZ : 167|16@0+ (0.125,-64) [-64|8127.875] "" Vector__XXX
 SG_ RSDS_RR_PER_OBJ22_DistYStd : 143|8@0+ (0.1,0) [0|25.5] "" Vector__XXX
 SG_ RSDS_RR_PER_OBJ22_DistY : 151|16@0+ (0.125,-256) [-256|7935.875] "" Vector__XXX
 SG_ RSDS_RR_PER_OBJ22_DistXStd : 135|8@0+ (0.1,0) [0|25.5] "" Vector__XXX
 SG_ RSDS_RR_PER_OBJ22_DistX : 119|16@0+ (0.0625,-256) [-256|3839.9375] "" Vector__XXX
 SG_ RSDS_RR_PER_OBJ22_ClassTypeProb : 111|8@0+ (1,0) [0|255] "" Vector__XXX
 SG_ RSDS_RR_PER_OBJ22_ClassType : 103|4@0+ (1,0) [0|15] "" Vector__XXX
 SG_ RSDS_RR_PER_OBJ22_AbsVelYStd : 79|8@0+ (0.0625,0) [0|15.9375] "" Vector__XXX
 SG_ RSDS_RR_PER_OBJ22_AbsVelY : 87|16@0+ (0.0312,-128) [-128|1916.692] "" Vector__XXX
 SG_ RSDS_RR_PER_OBJ22_AbsVelXStd : 71|8@0+ (0.0625,0) [0|15.9375] "" Vector__XXX
 SG_ RSDS_RR_PER_OBJ22_AbsVelX : 55|16@0+ (0.0312,-128) [-128|1916.692] "" Vector__XXX
 SG_ RSDS_RR_PER_OBJ22_AbsAccelYStd : 31|8@0+ (0.0625,0) [0|15.9375] "" Vector__XXX
 SG_ RSDS_RR_PER_OBJ22_AbsAccelY : 39|16@0+ (0.03125,-16) [-16|2031.96875] "" Vector__XXX
 SG_ RSDS_RR_PER_OBJ22_AbsAccelXStd : 23|8@0+ (0.0625,0) [0|15.9375] "" Vector__XXX
 SG_ RSDS_RR_PER_OBJ22_AbsAccelX : 7|16@0+ (0.03125,-16) [-16|2031.96875] "" Vector__XXX

BO_ 1524 ObjectList_Obj21_RR: 64 RR
 SG_ RSDS_RR_PER_OBJ21_YawRate : 279|16@0+ (0.002,-3.14) [-3.14|127.93] "" Vector__XXX
 SG_ RSDS_RR_PER_OBJ21_Width : 263|16@0+ (0.01,0) [0|655.35] "" Vector__XXX
 SG_ RSDS_RR_PER_OBJ21_ValidFlag : 97|1@0+ (1,0) [0|1] "" Vector__XXX
 SG_ RSDS_RR_PER_OBJ21_ObstProbabilit : 255|8@0+ (1,0) [0|255] "" Vector__XXX
 SG_ RSDS_RR_PER_OBJ21_MotionType : 247|3@0+ (1,0) [0|7] "" Vector__XXX
 SG_ RSDS_RR_PER_OBJ21_MeasState : 99|2@0+ (1,0) [0|3] "" Vector__XXX
 SG_ RSDS_RR_PER_OBJ21_LifeCycle : 223|8@0+ (1,0) [0|255] "" Vector__XXX
 SG_ RSDS_RR_PER_OBJ21_Length : 231|16@0+ (0.05,0) [0|3276.75] "" Vector__XXX
 SG_ RSDS_RR_PER_OBJ21_ID : 215|8@0+ (1,0) [0|255] "" Vector__XXX
 SG_ RSDS_RR_PER_OBJ21_HeadingAng : 199|16@0+ (0.002,-3.14) [-3.14|127.93] "" Vector__XXX
 SG_ RSDS_RR_PER_OBJ21_ExistProb : 191|8@0+ (0.03326,0) [0|8.4813] "" Vector__XXX
 SG_ RSDS_RR_PER_OBJ21_DistZStd : 183|8@0+ (0.1,0) [0|25.5] "" Vector__XXX
 SG_ RSDS_RR_PER_OBJ21_DistZ : 167|16@0+ (0.125,-64) [-64|8127.875] "" Vector__XXX
 SG_ RSDS_RR_PER_OBJ21_DistYStd : 143|8@0+ (0.1,0) [0|25.5] "" Vector__XXX
 SG_ RSDS_RR_PER_OBJ21_DistY : 151|16@0+ (0.125,-256) [-256|7935.875] "" Vector__XXX
 SG_ RSDS_RR_PER_OBJ21_DistXStd : 135|8@0+ (0.1,0) [0|25.5] "" Vector__XXX
 SG_ RSDS_RR_PER_OBJ21_DistX : 119|16@0+ (0.0625,-256) [-256|3839.9375] "" Vector__XXX
 SG_ RSDS_RR_PER_OBJ21_ClassTypeProb : 111|8@0+ (1,0) [0|255] "" Vector__XXX
 SG_ RSDS_RR_PER_OBJ21_ClassType : 103|4@0+ (1,0) [0|15] "" Vector__XXX
 SG_ RSDS_RR_PER_OBJ21_AbsVelYStd : 79|8@0+ (0.0625,0) [0|15.9375] "" Vector__XXX
 SG_ RSDS_RR_PER_OBJ21_AbsVelY : 87|16@0+ (0.0312,-128) [-128|1916.692] "" Vector__XXX
 SG_ RSDS_RR_PER_OBJ21_AbsVelXStd : 71|8@0+ (0.0625,0) [0|15.9375] "" Vector__XXX
 SG_ RSDS_RR_PER_OBJ21_AbsVelX : 55|16@0+ (0.0312,-128) [-128|1916.692] "" Vector__XXX
 SG_ RSDS_RR_PER_OBJ21_AbsAccelYStd : 31|8@0+ (0.0625,0) [0|15.9375] "" Vector__XXX
 SG_ RSDS_RR_PER_OBJ21_AbsAccelY : 39|16@0+ (0.03125,-16) [-16|2031.96875] "" Vector__XXX
 SG_ RSDS_RR_PER_OBJ21_AbsAccelXStd : 23|8@0+ (0.0625,0) [0|15.9375] "" Vector__XXX
 SG_ RSDS_RR_PER_OBJ21_AbsAccelX : 7|16@0+ (0.03125,-16) [-16|2031.96875] "" Vector__XXX

BO_ 1523 ObjectList_Obj20_RR: 64 RR
 SG_ RSDS_RR_PER_OBJ20_YawRate : 279|16@0+ (0.002,-3.14) [-3.14|127.93] "" Vector__XXX
 SG_ RSDS_RR_PER_OBJ20_Width : 263|16@0+ (0.01,0) [0|655.35] "" Vector__XXX
 SG_ RSDS_RR_PER_OBJ20_ValidFlag : 97|1@0+ (1,0) [0|1] "" Vector__XXX
 SG_ RSDS_RR_PER_OBJ20_ObstProbabilit : 255|8@0+ (1,0) [0|255] "" Vector__XXX
 SG_ RSDS_RR_PER_OBJ20_MotionType : 247|3@0+ (1,0) [0|7] "" Vector__XXX
 SG_ RSDS_RR_PER_OBJ20_MeasState : 99|2@0+ (1,0) [0|3] "" Vector__XXX
 SG_ RSDS_RR_PER_OBJ20_LifeCycle : 223|8@0+ (1,0) [0|255] "" Vector__XXX
 SG_ RSDS_RR_PER_OBJ20_Length : 231|16@0+ (0.05,0) [0|3276.75] "" Vector__XXX
 SG_ RSDS_RR_PER_OBJ20_ID : 215|8@0+ (1,0) [0|255] "" Vector__XXX
 SG_ RSDS_RR_PER_OBJ20_HeadingAng : 199|16@0+ (0.002,-3.14) [-3.14|127.93] "" Vector__XXX
 SG_ RSDS_RR_PER_OBJ20_ExistProb : 191|8@0+ (0.03326,0) [0|8.4813] "" Vector__XXX
 SG_ RSDS_RR_PER_OBJ20_DistZStd : 183|8@0+ (0.1,0) [0|25.5] "" Vector__XXX
 SG_ RSDS_RR_PER_OBJ20_DistZ : 167|16@0+ (0.125,-64) [-64|8127.875] "" Vector__XXX
 SG_ RSDS_RR_PER_OBJ20_DistYStd : 143|8@0+ (0.1,0) [0|25.5] "" Vector__XXX
 SG_ RSDS_RR_PER_OBJ20_DistY : 151|16@0+ (0.125,-256) [-256|7935.875] "" Vector__XXX
 SG_ RSDS_RR_PER_OBJ20_DistXStd : 135|8@0+ (0.1,0) [0|25.5] "" Vector__XXX
 SG_ RSDS_RR_PER_OBJ20_DistX : 119|16@0+ (0.0625,-256) [-256|3839.9375] "" Vector__XXX
 SG_ RSDS_RR_PER_OBJ20_ClassTypeProb : 111|8@0+ (1,0) [0|255] "" Vector__XXX
 SG_ RSDS_RR_PER_OBJ20_ClassType : 103|4@0+ (1,0) [0|15] "" Vector__XXX
 SG_ RSDS_RR_PER_OBJ20_AbsVelYStd : 79|8@0+ (0.0625,0) [0|15.9375] "" Vector__XXX
 SG_ RSDS_RR_PER_OBJ20_AbsVelY : 87|16@0+ (0.0312,-128) [-128|1916.692] "" Vector__XXX
 SG_ RSDS_RR_PER_OBJ20_AbsVelXStd : 71|8@0+ (0.0625,0) [0|15.9375] "" Vector__XXX
 SG_ RSDS_RR_PER_OBJ20_AbsVelX : 55|16@0+ (0.0312,-128) [-128|1916.692] "" Vector__XXX
 SG_ RSDS_RR_PER_OBJ20_AbsAccelYStd : 31|8@0+ (0.0625,0) [0|15.9375] "" Vector__XXX
 SG_ RSDS_RR_PER_OBJ20_AbsAccelY : 39|16@0+ (0.03125,-16) [-16|2031.96875] "" Vector__XXX
 SG_ RSDS_RR_PER_OBJ20_AbsAccelXStd : 23|8@0+ (0.0625,0) [0|15.9375] "" Vector__XXX
 SG_ RSDS_RR_PER_OBJ20_AbsAccelX : 7|16@0+ (0.03125,-16) [-16|2031.96875] "" Vector__XXX

BO_ 1522 ObjectList_Obj19_RR: 64 RR
 SG_ RSDS_RR_PER_OBJ19_YawRate : 279|16@0+ (0.002,-3.14) [-3.14|127.93] "" Vector__XXX
 SG_ RSDS_RR_PER_OBJ19_Width : 263|16@0+ (0.01,0) [0|655.35] "" Vector__XXX
 SG_ RSDS_RR_PER_OBJ19_ValidFlag : 97|1@0+ (1,0) [0|1] "" Vector__XXX
 SG_ RSDS_RR_PER_OBJ19_ObstProbabilit : 255|8@0+ (1,0) [0|255] "" Vector__XXX
 SG_ RSDS_RR_PER_OBJ19_MotionType : 247|3@0+ (1,0) [0|7] "" Vector__XXX
 SG_ RSDS_RR_PER_OBJ19_MeasState : 99|2@0+ (1,0) [0|3] "" Vector__XXX
 SG_ RSDS_RR_PER_OBJ19_LifeCycle : 223|8@0+ (1,0) [0|255] "" Vector__XXX
 SG_ RSDS_RR_PER_OBJ19_Length : 231|16@0+ (0.05,0) [0|3276.75] "" Vector__XXX
 SG_ RSDS_RR_PER_OBJ19_ID : 215|8@0+ (1,0) [0|255] "" Vector__XXX
 SG_ RSDS_RR_PER_OBJ19_HeadingAng : 199|16@0+ (0.002,-3.14) [-3.14|127.93] "" Vector__XXX
 SG_ RSDS_RR_PER_OBJ19_ExistProb : 191|8@0+ (0.03326,0) [0|8.4813] "" Vector__XXX
 SG_ RSDS_RR_PER_OBJ19_DistZStd : 183|8@0+ (0.1,0) [0|25.5] "" Vector__XXX
 SG_ RSDS_RR_PER_OBJ19_DistZ : 167|16@0+ (0.125,-64) [-64|8127.875] "" Vector__XXX
 SG_ RSDS_RR_PER_OBJ19_DistYStd : 143|8@0+ (0.1,0) [0|25.5] "" Vector__XXX
 SG_ RSDS_RR_PER_OBJ19_DistY : 151|16@0+ (0.125,-256) [-256|7935.875] "" Vector__XXX
 SG_ RSDS_RR_PER_OBJ19_DistXStd : 135|8@0+ (0.1,0) [0|25.5] "" Vector__XXX
 SG_ RSDS_RR_PER_OBJ19_DistX : 119|16@0+ (0.0625,-256) [-256|3839.9375] "" Vector__XXX
 SG_ RSDS_RR_PER_OBJ19_ClassTypeProb : 111|8@0+ (1,0) [0|255] "" Vector__XXX
 SG_ RSDS_RR_PER_OBJ19_ClassType : 103|4@0+ (1,0) [0|15] "" Vector__XXX
 SG_ RSDS_RR_PER_OBJ19_AbsVelYStd : 79|8@0+ (0.0625,0) [0|15.9375] "" Vector__XXX
 SG_ RSDS_RR_PER_OBJ19_AbsVelY : 87|16@0+ (0.0312,-128) [-128|1916.692] "" Vector__XXX
 SG_ RSDS_RR_PER_OBJ19_AbsVelXStd : 71|8@0+ (0.0625,0) [0|15.9375] "" Vector__XXX
 SG_ RSDS_RR_PER_OBJ19_AbsVelX : 55|16@0+ (0.0312,-128) [-128|1916.692] "" Vector__XXX
 SG_ RSDS_RR_PER_OBJ19_AbsAccelYStd : 31|8@0+ (0.0625,0) [0|15.9375] "" Vector__XXX
 SG_ RSDS_RR_PER_OBJ19_AbsAccelY : 39|16@0+ (0.03125,-16) [-16|2031.96875] "" Vector__XXX
 SG_ RSDS_RR_PER_OBJ19_AbsAccelXStd : 23|8@0+ (0.0625,0) [0|15.9375] "" Vector__XXX
 SG_ RSDS_RR_PER_OBJ19_AbsAccelX : 7|16@0+ (0.03125,-16) [-16|2031.96875] "" Vector__XXX

BO_ 1521 ObjectList_Obj18_RR: 64 RR
 SG_ RSDS_RR_PER_OBJ18_YawRate : 279|16@0+ (0.002,-3.14) [-3.14|127.93] "" Vector__XXX
 SG_ RSDS_RR_PER_OBJ18_Width : 263|16@0+ (0.01,0) [0|655.35] "" Vector__XXX
 SG_ RSDS_RR_PER_OBJ18_ValidFlag : 97|1@0+ (1,0) [0|1] "" Vector__XXX
 SG_ RSDS_RR_PER_OBJ18_ObstProbabilit : 255|8@0+ (1,0) [0|255] "" Vector__XXX
 SG_ RSDS_RR_PER_OBJ18_MotionType : 247|3@0+ (1,0) [0|7] "" Vector__XXX
 SG_ RSDS_RR_PER_OBJ18_MeasState : 99|2@0+ (1,0) [0|3] "" Vector__XXX
 SG_ RSDS_RR_PER_OBJ18_LifeCycle : 223|8@0+ (1,0) [0|255] "" Vector__XXX
 SG_ RSDS_RR_PER_OBJ18_Length : 231|16@0+ (0.05,0) [0|3276.75] "" Vector__XXX
 SG_ RSDS_RR_PER_OBJ18_ID : 215|8@0+ (1,0) [0|255] "" Vector__XXX
 SG_ RSDS_RR_PER_OBJ18_HeadingAng : 199|16@0+ (0.002,-3.14) [-3.14|127.93] "" Vector__XXX
 SG_ RSDS_RR_PER_OBJ18_ExistProb : 191|8@0+ (0.03326,0) [0|8.4813] "" Vector__XXX
 SG_ RSDS_RR_PER_OBJ18_DistZStd : 183|8@0+ (0.1,0) [0|25.5] "" Vector__XXX
 SG_ RSDS_RR_PER_OBJ18_DistZ : 167|16@0+ (0.125,-64) [-64|8127.875] "" Vector__XXX
 SG_ RSDS_RR_PER_OBJ18_DistYStd : 143|8@0+ (0.1,0) [0|25.5] "" Vector__XXX
 SG_ RSDS_RR_PER_OBJ18_DistY : 151|16@0+ (0.125,-256) [-256|7935.875] "" Vector__XXX
 SG_ RSDS_RR_PER_OBJ18_DistXStd : 135|8@0+ (0.1,0) [0|25.5] "" Vector__XXX
 SG_ RSDS_RR_PER_OBJ18_DistX : 119|16@0+ (0.0625,-256) [-256|3839.9375] "" Vector__XXX
 SG_ RSDS_RR_PER_OBJ18_ClassTypeProb : 111|8@0+ (1,0) [0|255] "" Vector__XXX
 SG_ RSDS_RR_PER_OBJ18_ClassType : 103|4@0+ (1,0) [0|15] "" Vector__XXX
 SG_ RSDS_RR_PER_OBJ18_AbsVelYStd : 79|8@0+ (0.0625,0) [0|15.9375] "" Vector__XXX
 SG_ RSDS_RR_PER_OBJ18_AbsVelY : 87|16@0+ (0.0312,-128) [-128|1916.692] "" Vector__XXX
 SG_ RSDS_RR_PER_OBJ18_AbsVelXStd : 71|8@0+ (0.0625,0) [0|15.9375] "" Vector__XXX
 SG_ RSDS_RR_PER_OBJ18_AbsVelX : 55|16@0+ (0.0312,-128) [-128|1916.692] "" Vector__XXX
 SG_ RSDS_RR_PER_OBJ18_AbsAccelYStd : 31|8@0+ (0.0625,0) [0|15.9375] "" Vector__XXX
 SG_ RSDS_RR_PER_OBJ18_AbsAccelY : 39|16@0+ (0.03125,-16) [-16|2031.96875] "" Vector__XXX
 SG_ RSDS_RR_PER_OBJ18_AbsAccelXStd : 23|8@0+ (0.0625,0) [0|15.9375] "" Vector__XXX
 SG_ RSDS_RR_PER_OBJ18_AbsAccelX : 7|16@0+ (0.03125,-16) [-16|2031.96875] "" Vector__XXX

BO_ 1520 ObjectList_Obj17_RR: 64 RR
 SG_ RSDS_RR_PER_OBJ17_YawRate : 279|16@0+ (0.002,-3.14) [-3.14|127.93] "" Vector__XXX
 SG_ RSDS_RR_PER_OBJ17_Width : 263|16@0+ (0.01,0) [0|655.35] "" Vector__XXX
 SG_ RSDS_RR_PER_OBJ17_ValidFlag : 97|1@0+ (1,0) [0|1] "" Vector__XXX
 SG_ RSDS_RR_PER_OBJ17_ObstProbabilit : 255|8@0+ (1,0) [0|255] "" Vector__XXX
 SG_ RSDS_RR_PER_OBJ17_MotionType : 247|3@0+ (1,0) [0|7] "" Vector__XXX
 SG_ RSDS_RR_PER_OBJ17_MeasState : 99|2@0+ (1,0) [0|3] "" Vector__XXX
 SG_ RSDS_RR_PER_OBJ17_LifeCycle : 223|8@0+ (1,0) [0|255] "" Vector__XXX
 SG_ RSDS_RR_PER_OBJ17_Length : 231|16@0+ (0.05,0) [0|3276.75] "" Vector__XXX
 SG_ RSDS_RR_PER_OBJ17_ID : 215|8@0+ (1,0) [0|255] "" Vector__XXX
 SG_ RSDS_RR_PER_OBJ17_HeadingAng : 199|16@0+ (0.002,-3.14) [-3.14|127.93] "" Vector__XXX
 SG_ RSDS_RR_PER_OBJ17_ExistProb : 191|8@0+ (0.03326,0) [0|8.4813] "" Vector__XXX
 SG_ RSDS_RR_PER_OBJ17_DistZStd : 183|8@0+ (0.1,0) [0|25.5] "" Vector__XXX
 SG_ RSDS_RR_PER_OBJ17_DistZ : 167|16@0+ (0.125,-64) [-64|8127.875] "" Vector__XXX
 SG_ RSDS_RR_PER_OBJ17_DistYStd : 143|8@0+ (0.1,0) [0|25.5] "" Vector__XXX
 SG_ RSDS_RR_PER_OBJ17_DistY : 151|16@0+ (0.125,-256) [-256|7935.875] "" Vector__XXX
 SG_ RSDS_RR_PER_OBJ17_DistXStd : 135|8@0+ (0.1,0) [0|25.5] "" Vector__XXX
 SG_ RSDS_RR_PER_OBJ17_DistX : 119|16@0+ (0.0625,-256) [-256|3839.9375] "" Vector__XXX
 SG_ RSDS_RR_PER_OBJ17_ClassTypeProb : 111|8@0+ (1,0) [0|255] "" Vector__XXX
 SG_ RSDS_RR_PER_OBJ17_ClassType : 103|4@0+ (1,0) [0|15] "" Vector__XXX
 SG_ RSDS_RR_PER_OBJ17_AbsVelYStd : 79|8@0+ (0.0625,0) [0|15.9375] "" Vector__XXX
 SG_ RSDS_RR_PER_OBJ17_AbsVelY : 87|16@0+ (0.0312,-128) [-128|1916.692] "" Vector__XXX
 SG_ RSDS_RR_PER_OBJ17_AbsVelXStd : 71|8@0+ (0.0625,0) [0|15.9375] "" Vector__XXX
 SG_ RSDS_RR_PER_OBJ17_AbsVelX : 55|16@0+ (0.0312,-128) [-128|1916.692] "" Vector__XXX
 SG_ RSDS_RR_PER_OBJ17_AbsAccelYStd : 31|8@0+ (0.0625,0) [0|15.9375] "" Vector__XXX
 SG_ RSDS_RR_PER_OBJ17_AbsAccelY : 39|16@0+ (0.03125,-16) [-16|2031.96875] "" Vector__XXX
 SG_ RSDS_RR_PER_OBJ17_AbsAccelXStd : 23|8@0+ (0.0625,0) [0|15.9375] "" Vector__XXX
 SG_ RSDS_RR_PER_OBJ17_AbsAccelX : 7|16@0+ (0.03125,-16) [-16|2031.96875] "" Vector__XXX

BO_ 1519 ObjectList_Obj16_RR: 64 RR
 SG_ RSDS_RR_PER_OBJ16_YawRate : 279|16@0+ (0.002,-3.14) [-3.14|127.93] "" Vector__XXX
 SG_ RSDS_RR_PER_OBJ16_Width : 263|16@0+ (0.01,0) [0|655.35] "" Vector__XXX
 SG_ RSDS_RR_PER_OBJ16_ValidFlag : 97|1@0+ (1,0) [0|1] "" Vector__XXX
 SG_ RSDS_RR_PER_OBJ16_ObstProbabilit : 255|8@0+ (1,0) [0|255] "" Vector__XXX
 SG_ RSDS_RR_PER_OBJ16_MotionType : 247|3@0+ (1,0) [0|7] "" Vector__XXX
 SG_ RSDS_RR_PER_OBJ16_MeasState : 99|2@0+ (1,0) [0|3] "" Vector__XXX
 SG_ RSDS_RR_PER_OBJ16_LifeCycle : 223|8@0+ (1,0) [0|255] "" Vector__XXX
 SG_ RSDS_RR_PER_OBJ16_Length : 231|16@0+ (0.05,0) [0|3276.75] "" Vector__XXX
 SG_ RSDS_RR_PER_OBJ16_ID : 215|8@0+ (1,0) [0|255] "" Vector__XXX
 SG_ RSDS_RR_PER_OBJ16_HeadingAng : 199|16@0+ (0.002,-3.14) [-3.14|127.93] "" Vector__XXX
 SG_ RSDS_RR_PER_OBJ16_ExistProb : 191|8@0+ (0.03326,0) [0|8.4813] "" Vector__XXX
 SG_ RSDS_RR_PER_OBJ16_DistZStd : 183|8@0+ (0.1,0) [0|25.5] "" Vector__XXX
 SG_ RSDS_RR_PER_OBJ16_DistZ : 167|16@0+ (0.125,-64) [-64|8127.875] "" Vector__XXX
 SG_ RSDS_RR_PER_OBJ16_DistYStd : 143|8@0+ (0.1,0) [0|25.5] "" Vector__XXX
 SG_ RSDS_RR_PER_OBJ16_DistY : 151|16@0+ (0.125,-256) [-256|7935.875] "" Vector__XXX
 SG_ RSDS_RR_PER_OBJ16_DistXStd : 135|8@0+ (0.1,0) [0|25.5] "" Vector__XXX
 SG_ RSDS_RR_PER_OBJ16_DistX : 119|16@0+ (0.0625,-256) [-256|3839.9375] "" Vector__XXX
 SG_ RSDS_RR_PER_OBJ16_ClassTypeProb : 111|8@0+ (1,0) [0|255] "" Vector__XXX
 SG_ RSDS_RR_PER_OBJ16_ClassType : 103|4@0+ (1,0) [0|15] "" Vector__XXX
 SG_ RSDS_RR_PER_OBJ16_AbsVelYStd : 79|8@0+ (0.0625,0) [0|15.9375] "" Vector__XXX
 SG_ RSDS_RR_PER_OBJ16_AbsVelY : 87|16@0+ (0.0312,-128) [-128|1916.692] "" Vector__XXX
 SG_ RSDS_RR_PER_OBJ16_AbsVelXStd : 71|8@0+ (0.0625,0) [0|15.9375] "" Vector__XXX
 SG_ RSDS_RR_PER_OBJ16_AbsVelX : 55|16@0+ (0.0312,-128) [-128|1916.692] "" Vector__XXX
 SG_ RSDS_RR_PER_OBJ16_AbsAccelYStd : 31|8@0+ (0.0625,0) [0|15.9375] "" Vector__XXX
 SG_ RSDS_RR_PER_OBJ16_AbsAccelY : 39|16@0+ (0.03125,-16) [-16|2031.96875] "" Vector__XXX
 SG_ RSDS_RR_PER_OBJ16_AbsAccelXStd : 23|8@0+ (0.0625,0) [0|15.9375] "" Vector__XXX
 SG_ RSDS_RR_PER_OBJ16_AbsAccelX : 7|16@0+ (0.03125,-16) [-16|2031.96875] "" Vector__XXX

BO_ 1518 ObjectList_Obj15_RR: 64 RR
 SG_ RSDS_RR_PER_OBJ15_YawRate : 279|16@0+ (0.002,-3.14) [-3.14|127.93] "" Vector__XXX
 SG_ RSDS_RR_PER_OBJ15_Width : 263|16@0+ (0.01,0) [0|655.35] "" Vector__XXX
 SG_ RSDS_RR_PER_OBJ15_ValidFlag : 97|1@0+ (1,0) [0|1] "" Vector__XXX
 SG_ RSDS_RR_PER_OBJ15_ObstProbabilit : 255|8@0+ (1,0) [0|255] "" Vector__XXX
 SG_ RSDS_RR_PER_OBJ15_MotionType : 247|3@0+ (1,0) [0|7] "" Vector__XXX
 SG_ RSDS_RR_PER_OBJ15_MeasState : 99|2@0+ (1,0) [0|3] "" Vector__XXX
 SG_ RSDS_RR_PER_OBJ15_LifeCycle : 223|8@0+ (1,0) [0|255] "" Vector__XXX
 SG_ RSDS_RR_PER_OBJ15_Length : 231|16@0+ (0.05,0) [0|3276.75] "" Vector__XXX
 SG_ RSDS_RR_PER_OBJ15_ID : 215|8@0+ (1,0) [0|255] "" Vector__XXX
 SG_ RSDS_RR_PER_OBJ15_HeadingAng : 199|16@0+ (0.002,-3.14) [-3.14|127.93] "" Vector__XXX
 SG_ RSDS_RR_PER_OBJ15_ExistProb : 191|8@0+ (0.03326,0) [0|8.4813] "" Vector__XXX
 SG_ RSDS_RR_PER_OBJ15_DistZStd : 183|8@0+ (0.1,0) [0|25.5] "" Vector__XXX
 SG_ RSDS_RR_PER_OBJ15_DistZ : 167|16@0+ (0.125,-64) [-64|8127.875] "" Vector__XXX
 SG_ RSDS_RR_PER_OBJ15_DistYStd : 143|8@0+ (0.1,0) [0|25.5] "" Vector__XXX
 SG_ RSDS_RR_PER_OBJ15_DistY : 151|16@0+ (0.125,-256) [-256|7935.875] "" Vector__XXX
 SG_ RSDS_RR_PER_OBJ15_DistXStd : 135|8@0+ (0.1,0) [0|25.5] "" Vector__XXX
 SG_ RSDS_RR_PER_OBJ15_DistX : 119|16@0+ (0.0625,-256) [-256|3839.9375] "" Vector__XXX
 SG_ RSDS_RR_PER_OBJ15_ClassTypeProb : 111|8@0+ (1,0) [0|255] "" Vector__XXX
 SG_ RSDS_RR_PER_OBJ15_ClassType : 103|4@0+ (1,0) [0|15] "" Vector__XXX
 SG_ RSDS_RR_PER_OBJ15_AbsVelYStd : 79|8@0+ (0.0625,0) [0|15.9375] "" Vector__XXX
 SG_ RSDS_RR_PER_OBJ15_AbsVelY : 87|16@0+ (0.0312,-128) [-128|1916.692] "" Vector__XXX
 SG_ RSDS_RR_PER_OBJ15_AbsVelXStd : 71|8@0+ (0.0625,0) [0|15.9375] "" Vector__XXX
 SG_ RSDS_RR_PER_OBJ15_AbsVelX : 55|16@0+ (0.0312,-128) [-128|1916.692] "" Vector__XXX
 SG_ RSDS_RR_PER_OBJ15_AbsAccelYStd : 31|8@0+ (0.0625,0) [0|15.9375] "" Vector__XXX
 SG_ RSDS_RR_PER_OBJ15_AbsAccelY : 39|16@0+ (0.03125,-16) [-16|2031.96875] "" Vector__XXX
 SG_ RSDS_RR_PER_OBJ15_AbsAccelXStd : 23|8@0+ (0.0625,0) [0|15.9375] "" Vector__XXX
 SG_ RSDS_RR_PER_OBJ15_AbsAccelX : 7|16@0+ (0.03125,-16) [-16|2031.96875] "" Vector__XXX

BO_ 1517 ObjectList_Obj14_RR: 64 RR
 SG_ RSDS_RR_PER_OBJ14_YawRate : 279|16@0+ (0.002,-3.14) [-3.14|127.93] "" Vector__XXX
 SG_ RSDS_RR_PER_OBJ14_Width : 263|16@0+ (0.01,0) [0|655.35] "" Vector__XXX
 SG_ RSDS_RR_PER_OBJ14_ValidFlag : 97|1@0+ (1,0) [0|1] "" Vector__XXX
 SG_ RSDS_RR_PER_OBJ14_ObstProbabilit : 255|8@0+ (1,0) [0|255] "" Vector__XXX
 SG_ RSDS_RR_PER_OBJ14_MotionType : 247|3@0+ (1,0) [0|7] "" Vector__XXX
 SG_ RSDS_RR_PER_OBJ14_MeasState : 99|2@0+ (1,0) [0|3] "" Vector__XXX
 SG_ RSDS_RR_PER_OBJ14_LifeCycle : 223|8@0+ (1,0) [0|255] "" Vector__XXX
 SG_ RSDS_RR_PER_OBJ14_Length : 231|16@0+ (0.05,0) [0|3276.75] "" Vector__XXX
 SG_ RSDS_RR_PER_OBJ14_ID : 215|8@0+ (1,0) [0|255] "" Vector__XXX
 SG_ RSDS_RR_PER_OBJ14_HeadingAng : 199|16@0+ (0.002,-3.14) [-3.14|127.93] "" Vector__XXX
 SG_ RSDS_RR_PER_OBJ14_ExistProb : 191|8@0+ (0.03326,0) [0|8.4813] "" Vector__XXX
 SG_ RSDS_RR_PER_OBJ14_DistZStd : 183|8@0+ (0.1,0) [0|25.5] "" Vector__XXX
 SG_ RSDS_RR_PER_OBJ14_DistZ : 167|16@0+ (0.125,-64) [-64|8127.875] "" Vector__XXX
 SG_ RSDS_RR_PER_OBJ14_DistYStd : 143|8@0+ (0.1,0) [0|25.5] "" Vector__XXX
 SG_ RSDS_RR_PER_OBJ14_DistY : 151|16@0+ (0.125,-256) [-256|7935.875] "" Vector__XXX
 SG_ RSDS_RR_PER_OBJ14_DistXStd : 135|8@0+ (0.1,0) [0|25.5] "" Vector__XXX
 SG_ RSDS_RR_PER_OBJ14_DistX : 119|16@0+ (0.0625,-256) [-256|3839.9375] "" Vector__XXX
 SG_ RSDS_RR_PER_OBJ14_ClassTypeProb : 111|8@0+ (1,0) [0|255] "" Vector__XXX
 SG_ RSDS_RR_PER_OBJ14_ClassType : 103|4@0+ (1,0) [0|15] "" Vector__XXX
 SG_ RSDS_RR_PER_OBJ14_AbsVelYStd : 79|8@0+ (0.0625,0) [0|15.9375] "" Vector__XXX
 SG_ RSDS_RR_PER_OBJ14_AbsVelY : 87|16@0+ (0.0312,-128) [-128|1916.692] "" Vector__XXX
 SG_ RSDS_RR_PER_OBJ14_AbsVelXStd : 71|8@0+ (0.0625,0) [0|15.9375] "" Vector__XXX
 SG_ RSDS_RR_PER_OBJ14_AbsVelX : 55|16@0+ (0.0312,-128) [-128|1916.692] "" Vector__XXX
 SG_ RSDS_RR_PER_OBJ14_AbsAccelYStd : 31|8@0+ (0.0625,0) [0|15.9375] "" Vector__XXX
 SG_ RSDS_RR_PER_OBJ14_AbsAccelY : 39|16@0+ (0.03125,-16) [-16|2031.96875] "" Vector__XXX
 SG_ RSDS_RR_PER_OBJ14_AbsAccelXStd : 23|8@0+ (0.0625,0) [0|15.9375] "" Vector__XXX
 SG_ RSDS_RR_PER_OBJ14_AbsAccelX : 7|16@0+ (0.03125,-16) [-16|2031.96875] "" Vector__XXX

BO_ 1516 ObjectList_Obj13_RR: 64 RR
 SG_ RSDS_RR_PER_OBJ13_YawRate : 279|16@0+ (0.002,-3.14) [-3.14|127.93] "" Vector__XXX
 SG_ RSDS_RR_PER_OBJ13_Width : 263|16@0+ (0.01,0) [0|655.35] "" Vector__XXX
 SG_ RSDS_RR_PER_OBJ13_ValidFlag : 97|1@0+ (1,0) [0|1] "" Vector__XXX
 SG_ RSDS_RR_PER_OBJ13_ObstProbabilit : 255|8@0+ (1,0) [0|255] "" Vector__XXX
 SG_ RSDS_RR_PER_OBJ13_MotionType : 247|3@0+ (1,0) [0|7] "" Vector__XXX
 SG_ RSDS_RR_PER_OBJ13_MeasState : 99|2@0+ (1,0) [0|3] "" Vector__XXX
 SG_ RSDS_RR_PER_OBJ13_LifeCycle : 223|8@0+ (1,0) [0|255] "" Vector__XXX
 SG_ RSDS_RR_PER_OBJ13_Length : 231|16@0+ (0.05,0) [0|3276.75] "" Vector__XXX
 SG_ RSDS_RR_PER_OBJ13_ID : 215|8@0+ (1,0) [0|255] "" Vector__XXX
 SG_ RSDS_RR_PER_OBJ13_HeadingAng : 199|16@0+ (0.002,-3.14) [-3.14|127.93] "" Vector__XXX
 SG_ RSDS_RR_PER_OBJ13_ExistProb : 191|8@0+ (0.03326,0) [0|8.4813] "" Vector__XXX
 SG_ RSDS_RR_PER_OBJ13_DistZStd : 183|8@0+ (0.1,0) [0|25.5] "" Vector__XXX
 SG_ RSDS_RR_PER_OBJ13_DistZ : 167|16@0+ (0.125,-64) [-64|8127.875] "" Vector__XXX
 SG_ RSDS_RR_PER_OBJ13_DistYStd : 143|8@0+ (0.1,0) [0|25.5] "" Vector__XXX
 SG_ RSDS_RR_PER_OBJ13_DistY : 151|16@0+ (0.125,-256) [-256|7935.875] "" Vector__XXX
 SG_ RSDS_RR_PER_OBJ13_DistXStd : 135|8@0+ (0.1,0) [0|25.5] "" Vector__XXX
 SG_ RSDS_RR_PER_OBJ13_DistX : 119|16@0+ (0.0625,-256) [-256|3839.9375] "" Vector__XXX
 SG_ RSDS_RR_PER_OBJ13_ClassTypeProb : 111|8@0+ (1,0) [0|255] "" Vector__XXX
 SG_ RSDS_RR_PER_OBJ13_ClassType : 103|4@0+ (1,0) [0|15] "" Vector__XXX
 SG_ RSDS_RR_PER_OBJ13_AbsVelYStd : 79|8@0+ (0.0625,0) [0|15.9375] "" Vector__XXX
 SG_ RSDS_RR_PER_OBJ13_AbsVelY : 87|16@0+ (0.0312,-128) [-128|1916.692] "" Vector__XXX
 SG_ RSDS_RR_PER_OBJ13_AbsVelXStd : 71|8@0+ (0.0625,0) [0|15.9375] "" Vector__XXX
 SG_ RSDS_RR_PER_OBJ13_AbsVelX : 55|16@0+ (0.0312,-128) [-128|1916.692] "" Vector__XXX
 SG_ RSDS_RR_PER_OBJ13_AbsAccelYStd : 31|8@0+ (0.0625,0) [0|15.9375] "" Vector__XXX
 SG_ RSDS_RR_PER_OBJ13_AbsAccelY : 39|16@0+ (0.03125,-16) [-16|2031.96875] "" Vector__XXX
 SG_ RSDS_RR_PER_OBJ13_AbsAccelXStd : 23|8@0+ (0.0625,0) [0|15.9375] "" Vector__XXX
 SG_ RSDS_RR_PER_OBJ13_AbsAccelX : 7|16@0+ (0.03125,-16) [-16|2031.96875] "" Vector__XXX

BO_ 1515 ObjectList_Obj12_RR: 64 RR
 SG_ RSDS_RR_PER_OBJ12_YawRate : 279|16@0+ (0.002,-3.14) [-3.14|127.93] "" Vector__XXX
 SG_ RSDS_RR_PER_OBJ12_Width : 263|16@0+ (0.01,0) [0|655.35] "" Vector__XXX
 SG_ RSDS_RR_PER_OBJ12_ValidFlag : 97|1@0+ (1,0) [0|1] "" Vector__XXX
 SG_ RSDS_RR_PER_OBJ12_ObstProbabilit : 255|8@0+ (1,0) [0|255] "" Vector__XXX
 SG_ RSDS_RR_PER_OBJ12_MotionType : 247|3@0+ (1,0) [0|7] "" Vector__XXX
 SG_ RSDS_RR_PER_OBJ12_MeasState : 99|2@0+ (1,0) [0|3] "" Vector__XXX
 SG_ RSDS_RR_PER_OBJ12_LifeCycle : 223|8@0+ (1,0) [0|255] "" Vector__XXX
 SG_ RSDS_RR_PER_OBJ12_Length : 231|16@0+ (0.05,0) [0|3276.75] "" Vector__XXX
 SG_ RSDS_RR_PER_OBJ12_ID : 215|8@0+ (1,0) [0|255] "" Vector__XXX
 SG_ RSDS_RR_PER_OBJ12_HeadingAng : 199|16@0+ (0.002,-3.14) [-3.14|127.93] "" Vector__XXX
 SG_ RSDS_RR_PER_OBJ12_ExistProb : 191|8@0+ (0.03326,0) [0|8.4813] "" Vector__XXX
 SG_ RSDS_RR_PER_OBJ12_DistZStd : 183|8@0+ (0.1,0) [0|25.5] "" Vector__XXX
 SG_ RSDS_RR_PER_OBJ12_DistZ : 167|16@0+ (0.125,-64) [-64|8127.875] "" Vector__XXX
 SG_ RSDS_RR_PER_OBJ12_DistYStd : 143|8@0+ (0.1,0) [0|25.5] "" Vector__XXX
 SG_ RSDS_RR_PER_OBJ12_DistY : 151|16@0+ (0.125,-256) [-256|7935.875] "" Vector__XXX
 SG_ RSDS_RR_PER_OBJ12_DistXStd : 135|8@0+ (0.1,0) [0|25.5] "" Vector__XXX
 SG_ RSDS_RR_PER_OBJ12_DistX : 119|16@0+ (0.0625,-256) [-256|3839.9375] "" Vector__XXX
 SG_ RSDS_RR_PER_OBJ12_ClassTypeProb : 111|8@0+ (1,0) [0|255] "" Vector__XXX
 SG_ RSDS_RR_PER_OBJ12_ClassType : 103|4@0+ (1,0) [0|15] "" Vector__XXX
 SG_ RSDS_RR_PER_OBJ12_AbsVelYStd : 79|8@0+ (0.0625,0) [0|15.9375] "" Vector__XXX
 SG_ RSDS_RR_PER_OBJ12_AbsVelY : 87|16@0+ (0.0312,-128) [-128|1916.692] "" Vector__XXX
 SG_ RSDS_RR_PER_OBJ12_AbsVelXStd : 71|8@0+ (0.0625,0) [0|15.9375] "" Vector__XXX
 SG_ RSDS_RR_PER_OBJ12_AbsVelX : 55|16@0+ (0.0312,-128) [-128|1916.692] "" Vector__XXX
 SG_ RSDS_RR_PER_OBJ12_AbsAccelYStd : 31|8@0+ (0.0625,0) [0|15.9375] "" Vector__XXX
 SG_ RSDS_RR_PER_OBJ12_AbsAccelY : 39|16@0+ (0.03125,-16) [-16|2031.96875] "" Vector__XXX
 SG_ RSDS_RR_PER_OBJ12_AbsAccelXStd : 23|8@0+ (0.0625,0) [0|15.9375] "" Vector__XXX
 SG_ RSDS_RR_PER_OBJ12_AbsAccelX : 7|16@0+ (0.03125,-16) [-16|2031.96875] "" Vector__XXX

BO_ 1514 ObjectList_Obj11_RR: 64 RR
 SG_ RSDS_RR_PER_OBJ11_YawRate : 279|16@0+ (0.002,-3.14) [-3.14|127.93] "" Vector__XXX
 SG_ RSDS_RR_PER_OBJ11_Width : 263|16@0+ (0.01,0) [0|655.35] "" Vector__XXX
 SG_ RSDS_RR_PER_OBJ11_ValidFlag : 97|1@0+ (1,0) [0|1] "" Vector__XXX
 SG_ RSDS_RR_PER_OBJ11_ObstProbabilit : 255|8@0+ (1,0) [0|255] "" Vector__XXX
 SG_ RSDS_RR_PER_OBJ11_MotionType : 247|3@0+ (1,0) [0|7] "" Vector__XXX
 SG_ RSDS_RR_PER_OBJ11_MeasState : 99|2@0+ (1,0) [0|3] "" Vector__XXX
 SG_ RSDS_RR_PER_OBJ11_LifeCycle : 223|8@0+ (1,0) [0|255] "" Vector__XXX
 SG_ RSDS_RR_PER_OBJ11_Length : 231|16@0+ (0.05,0) [0|3276.75] "" Vector__XXX
 SG_ RSDS_RR_PER_OBJ11_ID : 215|8@0+ (1,0) [0|255] "" Vector__XXX
 SG_ RSDS_RR_PER_OBJ11_HeadingAng : 199|16@0+ (0.002,-3.14) [-3.14|127.93] "" Vector__XXX
 SG_ RSDS_RR_PER_OBJ11_ExistProb : 191|8@0+ (0.03326,0) [0|8.4813] "" Vector__XXX
 SG_ RSDS_RR_PER_OBJ11_DistZStd : 183|8@0+ (0.1,0) [0|25.5] "" Vector__XXX
 SG_ RSDS_RR_PER_OBJ11_DistZ : 167|16@0+ (0.125,-64) [-64|8127.875] "" Vector__XXX
 SG_ RSDS_RR_PER_OBJ11_DistYStd : 143|8@0+ (0.1,0) [0|25.5] "" Vector__XXX
 SG_ RSDS_RR_PER_OBJ11_DistY : 151|16@0+ (0.125,-256) [-256|7935.875] "" Vector__XXX
 SG_ RSDS_RR_PER_OBJ11_DistXStd : 135|8@0+ (0.1,0) [0|25.5] "" Vector__XXX
 SG_ RSDS_RR_PER_OBJ11_DistX : 119|16@0+ (0.0625,-256) [-256|3839.9375] "" Vector__XXX
 SG_ RSDS_RR_PER_OBJ11_ClassTypeProb : 111|8@0+ (1,0) [0|255] "" Vector__XXX
 SG_ RSDS_RR_PER_OBJ11_ClassType : 103|4@0+ (1,0) [0|15] "" Vector__XXX
 SG_ RSDS_RR_PER_OBJ11_AbsVelYStd : 79|8@0+ (0.0625,0) [0|15.9375] "" Vector__XXX
 SG_ RSDS_RR_PER_OBJ11_AbsVelY : 87|16@0+ (0.0312,-128) [-128|1916.692] "" Vector__XXX
 SG_ RSDS_RR_PER_OBJ11_AbsVelXStd : 71|8@0+ (0.0625,0) [0|15.9375] "" Vector__XXX
 SG_ RSDS_RR_PER_OBJ11_AbsVelX : 55|16@0+ (0.0312,-128) [-128|1916.692] "" Vector__XXX
 SG_ RSDS_RR_PER_OBJ11_AbsAccelYStd : 31|8@0+ (0.0625,0) [0|15.9375] "" Vector__XXX
 SG_ RSDS_RR_PER_OBJ11_AbsAccelY : 39|16@0+ (0.03125,-16) [-16|2031.96875] "" Vector__XXX
 SG_ RSDS_RR_PER_OBJ11_AbsAccelXStd : 23|8@0+ (0.0625,0) [0|15.9375] "" Vector__XXX
 SG_ RSDS_RR_PER_OBJ11_AbsAccelX : 7|16@0+ (0.03125,-16) [-16|2031.96875] "" Vector__XXX

BO_ 1513 ObjectList_Obj10_RR: 64 RR
 SG_ RSDS_RR_PER_OBJ10_YawRate : 279|16@0+ (0.002,-3.14) [-3.14|127.93] "" Vector__XXX
 SG_ RSDS_RR_PER_OBJ10_Width : 263|16@0+ (0.01,0) [0|655.35] "" Vector__XXX
 SG_ RSDS_RR_PER_OBJ10_ValidFlag : 97|1@0+ (1,0) [0|1] "" Vector__XXX
 SG_ RSDS_RR_PER_OBJ10_ObstProbabilit : 255|8@0+ (1,0) [0|255] "" Vector__XXX
 SG_ RSDS_RR_PER_OBJ10_MotionType : 247|3@0+ (1,0) [0|7] "" Vector__XXX
 SG_ RSDS_RR_PER_OBJ10_MeasState : 99|2@0+ (1,0) [0|3] "" Vector__XXX
 SG_ RSDS_RR_PER_OBJ10_LifeCycle : 223|8@0+ (1,0) [0|255] "" Vector__XXX
 SG_ RSDS_RR_PER_OBJ10_Length : 231|16@0+ (0.05,0) [0|3276.75] "" Vector__XXX
 SG_ RSDS_RR_PER_OBJ10_ID : 215|8@0+ (1,0) [0|255] "" Vector__XXX
 SG_ RSDS_RR_PER_OBJ10_HeadingAng : 199|16@0+ (0.002,-3.14) [-3.14|127.93] "" Vector__XXX
 SG_ RSDS_RR_PER_OBJ10_ExistProb : 191|8@0+ (0.03326,0) [0|8.4813] "" Vector__XXX
 SG_ RSDS_RR_PER_OBJ10_DistZStd : 183|8@0+ (0.1,0) [0|25.5] "" Vector__XXX
 SG_ RSDS_RR_PER_OBJ10_DistZ : 167|16@0+ (0.125,-64) [-64|8127.875] "" Vector__XXX
 SG_ RSDS_RR_PER_OBJ10_DistYStd : 143|8@0+ (0.1,0) [0|25.5] "" Vector__XXX
 SG_ RSDS_RR_PER_OBJ10_DistY : 151|16@0+ (0.125,-256) [-256|7935.875] "" Vector__XXX
 SG_ RSDS_RR_PER_OBJ10_DistXStd : 135|8@0+ (0.1,0) [0|25.5] "" Vector__XXX
 SG_ RSDS_RR_PER_OBJ10_DistX : 119|16@0+ (0.0625,-256) [-256|3839.9375] "" Vector__XXX
 SG_ RSDS_RR_PER_OBJ10_ClassTypeProb : 111|8@0+ (1,0) [0|255] "" Vector__XXX
 SG_ RSDS_RR_PER_OBJ10_ClassType : 103|4@0+ (1,0) [0|15] "" Vector__XXX
 SG_ RSDS_RR_PER_OBJ10_AbsVelYStd : 79|8@0+ (0.0625,0) [0|15.9375] "" Vector__XXX
 SG_ RSDS_RR_PER_OBJ10_AbsVelY : 87|16@0+ (0.0312,-128) [-128|1916.692] "" Vector__XXX
 SG_ RSDS_RR_PER_OBJ10_AbsVelXStd : 71|8@0+ (0.0625,0) [0|15.9375] "" Vector__XXX
 SG_ RSDS_RR_PER_OBJ10_AbsVelX : 55|16@0+ (0.0312,-128) [-128|1916.692] "" Vector__XXX
 SG_ RSDS_RR_PER_OBJ10_AbsAccelYStd : 31|8@0+ (0.0625,0) [0|15.9375] "" Vector__XXX
 SG_ RSDS_RR_PER_OBJ10_AbsAccelY : 39|16@0+ (0.03125,-16) [-16|2031.96875] "" Vector__XXX
 SG_ RSDS_RR_PER_OBJ10_AbsAccelXStd : 23|8@0+ (0.0625,0) [0|15.9375] "" Vector__XXX
 SG_ RSDS_RR_PER_OBJ10_AbsAccelX : 7|16@0+ (0.03125,-16) [-16|2031.96875] "" Vector__XXX

BO_ 1512 ObjectList_Obj9_RR: 64 RR
 SG_ RSDS_RR_PER_OBJ9_YawRate : 279|16@0+ (0.002,-3.14) [-3.14|127.93] "" Vector__XXX
 SG_ RSDS_RR_PER_OBJ9_Width : 263|16@0+ (0.01,0) [0|655.35] "" Vector__XXX
 SG_ RSDS_RR_PER_OBJ9_ValidFlag : 97|1@0+ (1,0) [0|1] "" Vector__XXX
 SG_ RSDS_RR_PER_OBJ9_ObstProbability : 255|8@0+ (1,0) [0|255] "" Vector__XXX
 SG_ RSDS_RR_PER_OBJ9_MotionType : 247|3@0+ (1,0) [0|7] "" Vector__XXX
 SG_ RSDS_RR_PER_OBJ9_MeasState : 99|2@0+ (1,0) [0|3] "" Vector__XXX
 SG_ RSDS_RR_PER_OBJ9_LifeCycle : 223|8@0+ (1,0) [0|255] "" Vector__XXX
 SG_ RSDS_RR_PER_OBJ9_Length : 231|16@0+ (0.05,0) [0|3276.75] "" Vector__XXX
 SG_ RSDS_RR_PER_OBJ9_ID : 215|8@0+ (1,0) [0|255] "" Vector__XXX
 SG_ RSDS_RR_PER_OBJ9_HeadingAng : 199|16@0+ (0.002,-3.14) [-3.14|127.93] "" Vector__XXX
 SG_ RSDS_RR_PER_OBJ9_ExistProb : 191|8@0+ (0.03326,0) [0|8.4813] "" Vector__XXX
 SG_ RSDS_RR_PER_OBJ9_DistZStd : 183|8@0+ (0.1,0) [0|25.5] "" Vector__XXX
 SG_ RSDS_RR_PER_OBJ9_DistZ : 167|16@0+ (0.125,-64) [-64|8127.875] "" Vector__XXX
 SG_ RSDS_RR_PER_OBJ9_DistYStd : 143|8@0+ (0.1,0) [0|25.5] "" Vector__XXX
 SG_ RSDS_RR_PER_OBJ9_DistY : 151|16@0+ (0.125,-256) [-256|7935.875] "" Vector__XXX
 SG_ RSDS_RR_PER_OBJ9_DistXStd : 135|8@0+ (0.1,0) [0|25.5] "" Vector__XXX
 SG_ RSDS_RR_PER_OBJ9_DistX : 119|16@0+ (0.0625,-256) [-256|3839.9375] "" Vector__XXX
 SG_ RSDS_RR_PER_OBJ9_ClassTypeProb : 111|8@0+ (1,0) [0|255] "" Vector__XXX
 SG_ RSDS_RR_PER_OBJ9_ClassType : 103|4@0+ (1,0) [0|15] "" Vector__XXX
 SG_ RSDS_RR_PER_OBJ9_AbsVelYStd : 79|8@0+ (0.0625,0) [0|15.9375] "" Vector__XXX
 SG_ RSDS_RR_PER_OBJ9_AbsVelY : 87|16@0+ (0.0312,-128) [-128|1916.692] "" Vector__XXX
 SG_ RSDS_RR_PER_OBJ9_AbsVelXStd : 71|8@0+ (0.0625,0) [0|15.9375] "" Vector__XXX
 SG_ RSDS_RR_PER_OBJ9_AbsVelX : 55|16@0+ (0.0312,-128) [-128|1916.692] "" Vector__XXX
 SG_ RSDS_RR_PER_OBJ9_AbsAccelYStd : 31|8@0+ (0.0625,0) [0|15.9375] "" Vector__XXX
 SG_ RSDS_RR_PER_OBJ9_AbsAccelY : 39|16@0+ (0.03125,-16) [-16|2031.96875] "" Vector__XXX
 SG_ RSDS_RR_PER_OBJ9_AbsAccelXStd : 23|8@0+ (0.0625,0) [0|15.9375] "" Vector__XXX
 SG_ RSDS_RR_PER_OBJ9_AbsAccelX : 7|16@0+ (0.03125,-16) [-16|2031.96875] "" Vector__XXX

BO_ 1511 ObjectList_Obj8_RR: 64 RR
 SG_ RSDS_RR_PER_OBJ8_YawRate : 279|16@0+ (0.002,-3.14) [-3.14|127.93] "" Vector__XXX
 SG_ RSDS_RR_PER_OBJ8_Width : 263|16@0+ (0.01,0) [0|655.35] "" Vector__XXX
 SG_ RSDS_RR_PER_OBJ8_ValidFlag : 97|1@0+ (1,0) [0|1] "" Vector__XXX
 SG_ RSDS_RR_PER_OBJ8_ObstProbability : 255|8@0+ (1,0) [0|255] "" Vector__XXX
 SG_ RSDS_RR_PER_OBJ8_MotionType : 247|3@0+ (1,0) [0|7] "" Vector__XXX
 SG_ RSDS_RR_PER_OBJ8_MeasState : 99|2@0+ (1,0) [0|3] "" Vector__XXX
 SG_ RSDS_RR_PER_OBJ8_LifeCycle : 223|8@0+ (1,0) [0|255] "" Vector__XXX
 SG_ RSDS_RR_PER_OBJ8_Length : 231|16@0+ (0.05,0) [0|3276.75] "" Vector__XXX
 SG_ RSDS_RR_PER_OBJ8_ID : 215|8@0+ (1,0) [0|255] "" Vector__XXX
 SG_ RSDS_RR_PER_OBJ8_HeadingAng : 199|16@0+ (0.002,-3.14) [-3.14|127.93] "" Vector__XXX
 SG_ RSDS_RR_PER_OBJ8_ExistProb : 191|8@0+ (0.03326,0) [0|8.4813] "" Vector__XXX
 SG_ RSDS_RR_PER_OBJ8_DistZStd : 183|8@0+ (0.1,0) [0|25.5] "" Vector__XXX
 SG_ RSDS_RR_PER_OBJ8_DistZ : 167|16@0+ (0.125,-64) [-64|8127.875] "" Vector__XXX
 SG_ RSDS_RR_PER_OBJ8_DistYStd : 143|8@0+ (0.1,0) [0|25.5] "" Vector__XXX
 SG_ RSDS_RR_PER_OBJ8_DistY : 151|16@0+ (0.125,-256) [-256|7935.875] "" Vector__XXX
 SG_ RSDS_RR_PER_OBJ8_DistXStd : 135|8@0+ (0.1,0) [0|25.5] "" Vector__XXX
 SG_ RSDS_RR_PER_OBJ8_DistX : 119|16@0+ (0.0625,-256) [-256|3839.9375] "" Vector__XXX
 SG_ RSDS_RR_PER_OBJ8_ClassTypeProb : 111|8@0+ (1,0) [0|255] "" Vector__XXX
 SG_ RSDS_RR_PER_OBJ8_ClassType : 103|4@0+ (1,0) [0|15] "" Vector__XXX
 SG_ RSDS_RR_PER_OBJ8_AbsVelYStd : 79|8@0+ (0.0625,0) [0|15.9375] "" Vector__XXX
 SG_ RSDS_RR_PER_OBJ8_AbsVelY : 87|16@0+ (0.0312,-128) [-128|1916.692] "" Vector__XXX
 SG_ RSDS_RR_PER_OBJ8_AbsVelXStd : 71|8@0+ (0.0625,0) [0|15.9375] "" Vector__XXX
 SG_ RSDS_RR_PER_OBJ8_AbsVelX : 55|16@0+ (0.0312,-128) [-128|1916.692] "" Vector__XXX
 SG_ RSDS_RR_PER_OBJ8_AbsAccelYStd : 31|8@0+ (0.0625,0) [0|15.9375] "" Vector__XXX
 SG_ RSDS_RR_PER_OBJ8_AbsAccelY : 39|16@0+ (0.03125,-16) [-16|2031.96875] "" Vector__XXX
 SG_ RSDS_RR_PER_OBJ8_AbsAccelXStd : 23|8@0+ (0.0625,0) [0|15.9375] "" Vector__XXX
 SG_ RSDS_RR_PER_OBJ8_AbsAccelX : 7|16@0+ (0.03125,-16) [-16|2031.96875] "" Vector__XXX

BO_ 1510 ObjectList_Obj7_RR: 64 RR
 SG_ RSDS_RR_PER_OBJ7_YawRate : 279|16@0+ (0.002,-3.14) [-3.14|127.93] "" Vector__XXX
 SG_ RSDS_RR_PER_OBJ7_Width : 263|16@0+ (0.01,0) [0|655.35] "" Vector__XXX
 SG_ RSDS_RR_PER_OBJ7_ValidFlag : 97|1@0+ (1,0) [0|1] "" Vector__XXX
 SG_ RSDS_RR_PER_OBJ7_ObstProbability : 255|8@0+ (1,0) [0|255] "" Vector__XXX
 SG_ RSDS_RR_PER_OBJ7_MotionType : 247|3@0+ (1,0) [0|7] "" Vector__XXX
 SG_ RSDS_RR_PER_OBJ7_MeasState : 99|2@0+ (1,0) [0|3] "" Vector__XXX
 SG_ RSDS_RR_PER_OBJ7_LifeCycle : 223|8@0+ (1,0) [0|255] "" Vector__XXX
 SG_ RSDS_RR_PER_OBJ7_Length : 231|16@0+ (0.05,0) [0|3276.75] "" Vector__XXX
 SG_ RSDS_RR_PER_OBJ7_ID : 215|8@0+ (1,0) [0|255] "" Vector__XXX
 SG_ RSDS_RR_PER_OBJ7_HeadingAng : 199|16@0+ (0.002,-3.14) [-3.14|127.93] "" Vector__XXX
 SG_ RSDS_RR_PER_OBJ7_ExistProb : 191|8@0+ (0.03326,0) [0|8.4813] "" Vector__XXX
 SG_ RSDS_RR_PER_OBJ7_DistZStd : 183|8@0+ (0.1,0) [0|25.5] "" Vector__XXX
 SG_ RSDS_RR_PER_OBJ7_DistZ : 167|16@0+ (0.125,-64) [-64|8127.875] "" Vector__XXX
 SG_ RSDS_RR_PER_OBJ7_DistYStd : 143|8@0+ (0.1,0) [0|25.5] "" Vector__XXX
 SG_ RSDS_RR_PER_OBJ7_DistY : 151|16@0+ (0.125,-256) [-256|7935.875] "" Vector__XXX
 SG_ RSDS_RR_PER_OBJ7_DistXStd : 135|8@0+ (0.1,0) [0|25.5] "" Vector__XXX
 SG_ RSDS_RR_PER_OBJ7_DistX : 119|16@0+ (0.0625,-256) [-256|3839.9375] "" Vector__XXX
 SG_ RSDS_RR_PER_OBJ7_ClassTypeProb : 111|8@0+ (1,0) [0|255] "" Vector__XXX
 SG_ RSDS_RR_PER_OBJ7_ClassType : 103|4@0+ (1,0) [0|15] "" Vector__XXX
 SG_ RSDS_RR_PER_OBJ7_AbsVelYStd : 79|8@0+ (0.0625,0) [0|15.9375] "" Vector__XXX
 SG_ RSDS_RR_PER_OBJ7_AbsVelY : 87|16@0+ (0.0312,-128) [-128|1916.692] "" Vector__XXX
 SG_ RSDS_RR_PER_OBJ7_AbsVelXStd : 71|8@0+ (0.0625,0) [0|15.9375] "" Vector__XXX
 SG_ RSDS_RR_PER_OBJ7_AbsVelX : 55|16@0+ (0.0312,-128) [-128|1916.692] "" Vector__XXX
 SG_ RSDS_RR_PER_OBJ7_AbsAccelYStd : 31|8@0+ (0.0625,0) [0|15.9375] "" Vector__XXX
 SG_ RSDS_RR_PER_OBJ7_AbsAccelY : 39|16@0+ (0.03125,-16) [-16|2031.96875] "" Vector__XXX
 SG_ RSDS_RR_PER_OBJ7_AbsAccelXStd : 23|8@0+ (0.0625,0) [0|15.9375] "" Vector__XXX
 SG_ RSDS_RR_PER_OBJ7_AbsAccelX : 7|16@0+ (0.03125,-16) [-16|2031.96875] "" Vector__XXX

BO_TX_BU_ 1025 : FR,FL;
BO_TX_BU_ 1024 : FR,FL;

CM_ SG_ 1535 RSDS_RR_PER_OBJ32_YawRate "RSDS_RR_PER_OBJ32_YawRate";
CM_ SG_ 1535 RSDS_RR_PER_OBJ32_Width "RSDS_RR_PER_OBJ32_Width";
CM_ SG_ 1535 RSDS_RR_PER_OBJ32_ValidFlag "RSDS_RR_PER_OBJ32_ValidFlag";
CM_ SG_ 1535 RSDS_RR_PER_OBJ32_ObstProbabilit "RSDS_RR_PER_OBJ32_ObstProbability";
CM_ SG_ 1535 RSDS_RR_PER_OBJ32_MotionType "RSDS_RR_PER_OBJ32_MotionType";
CM_ SG_ 1535 RSDS_RR_PER_OBJ32_MeasState "RSDS_RR_PER_OBJ32_MeasState";
CM_ SG_ 1535 RSDS_RR_PER_OBJ32_LifeCycle "RSDS_RR_PER_OBJ32_LifeCycle";
CM_ SG_ 1535 RSDS_RR_PER_OBJ32_Length "RSDS_RR_PER_OBJ32_Length";
CM_ SG_ 1535 RSDS_RR_PER_OBJ32_ID "RSDS_RR_PER_OBJ32_ID";
CM_ SG_ 1535 RSDS_RR_PER_OBJ32_HeadingAng "RSDS_RR_PER_OBJ32_HeadingAng";
CM_ SG_ 1535 RSDS_RR_PER_OBJ32_ExistProb "RSDS_RR_PER_OBJ32_ExistProb";
CM_ SG_ 1535 RSDS_RR_PER_OBJ32_DistZStd "RSDS_RR_PER_OBJ32_DistZStd";
CM_ SG_ 1535 RSDS_RR_PER_OBJ32_DistZ "RSDS_RR_PER_OBJ32_DistZ";
CM_ SG_ 1535 RSDS_RR_PER_OBJ32_DistYStd "RSDS_RR_PER_OBJ32_DistYStd";
CM_ SG_ 1535 RSDS_RR_PER_OBJ32_DistY "RSDS_RR_PER_OBJ32_DistY";
CM_ SG_ 1535 RSDS_RR_PER_OBJ32_DistXStd "RSDS_RR_PER_OBJ32_DistXStd";
CM_ SG_ 1535 RSDS_RR_PER_OBJ32_DistX "RSDS_RR_PER_OBJ32_DistX";
CM_ SG_ 1535 RSDS_RR_PER_OBJ32_ClassTypeProb "RSDS_RR_PER_OBJ32_ClassTypeProb";
CM_ SG_ 1535 RSDS_RR_PER_OBJ32_ClassType "RSDS_RR_PER_OBJ32_ClassType";
CM_ SG_ 1535 RSDS_RR_PER_OBJ32_AbsVelYStd "RSDS_RR_PER_OBJ32_AbsVelYStd";
CM_ SG_ 1535 RSDS_RR_PER_OBJ32_AbsVelY "RSDS_RR_PER_OBJ32_AbsVelY";
CM_ SG_ 1535 RSDS_RR_PER_OBJ32_AbsVelXStd "RSDS_RR_PER_OBJ32_AbsVelXStd";
CM_ SG_ 1535 RSDS_RR_PER_OBJ32_AbsVelX "RSDS_RR_PER_OBJ32_AbsVelX";
CM_ SG_ 1535 RSDS_RR_PER_OBJ32_AbsAccelYStd "RSDS_RR_PER_OBJ32_AbsAccelYStd";
CM_ SG_ 1535 RSDS_RR_PER_OBJ32_AbsAccelY "RSDS_RR_PER_OBJ32_AbsAccelY";
CM_ SG_ 1535 RSDS_RR_PER_OBJ32_AbsAccelXStd "RSDS_RR_PER_OBJ32_AbsAccelXStd";
CM_ SG_ 1535 RSDS_RR_PER_OBJ32_AbsAccelX "RSDS_RR_PER_OBJ32_AbsAccelX";
CM_ SG_ 1534 RSDS_RR_PER_OBJ31_YawRate "RSDS_RR_PER_OBJ31_YawRate";
CM_ SG_ 1534 RSDS_RR_PER_OBJ31_Width "RSDS_RR_PER_OBJ31_Width";
CM_ SG_ 1534 RSDS_RR_PER_OBJ31_ValidFlag "RSDS_RR_PER_OBJ31_ValidFlag";
CM_ SG_ 1534 RSDS_RR_PER_OBJ31_ObstProbabilit "RSDS_RR_PER_OBJ31_ObstProbability";
CM_ SG_ 1534 RSDS_RR_PER_OBJ31_MotionType "RSDS_RR_PER_OBJ31_MotionType";
CM_ SG_ 1534 RSDS_RR_PER_OBJ31_MeasState "RSDS_RR_PER_OBJ31_MeasState";
CM_ SG_ 1534 RSDS_RR_PER_OBJ31_LifeCycle "RSDS_RR_PER_OBJ31_LifeCycle";
CM_ SG_ 1534 RSDS_RR_PER_OBJ31_Length "RSDS_RR_PER_OBJ31_Length";
CM_ SG_ 1534 RSDS_RR_PER_OBJ31_ID "RSDS_RR_PER_OBJ31_ID";
CM_ SG_ 1534 RSDS_RR_PER_OBJ31_HeadingAng "RSDS_RR_PER_OBJ31_HeadingAng";
CM_ SG_ 1534 RSDS_RR_PER_OBJ31_ExistProb "RSDS_RR_PER_OBJ31_ExistProb";
CM_ SG_ 1534 RSDS_RR_PER_OBJ31_DistZStd "RSDS_RR_PER_OBJ31_DistZStd";
CM_ SG_ 1534 RSDS_RR_PER_OBJ31_DistZ "RSDS_RR_PER_OBJ31_DistZ";
CM_ SG_ 1534 RSDS_RR_PER_OBJ31_DistYStd "RSDS_RR_PER_OBJ31_DistYStd";
CM_ SG_ 1534 RSDS_RR_PER_OBJ31_DistY "RSDS_RR_PER_OBJ31_DistY";
CM_ SG_ 1534 RSDS_RR_PER_OBJ31_DistXStd "RSDS_RR_PER_OBJ31_DistXStd";
CM_ SG_ 1534 RSDS_RR_PER_OBJ31_DistX "RSDS_RR_PER_OBJ31_DistX";
CM_ SG_ 1534 RSDS_RR_PER_OBJ31_ClassTypeProb "RSDS_RR_PER_OBJ31_ClassTypeProb";
CM_ SG_ 1534 RSDS_RR_PER_OBJ31_ClassType "RSDS_RR_PER_OBJ31_ClassType";
CM_ SG_ 1534 RSDS_RR_PER_OBJ31_AbsVelYStd "RSDS_RR_PER_OBJ31_AbsVelYStd";
CM_ SG_ 1534 RSDS_RR_PER_OBJ31_AbsVelY "RSDS_RR_PER_OBJ31_AbsVelY";
CM_ SG_ 1534 RSDS_RR_PER_OBJ31_AbsVelXStd "RSDS_RR_PER_OBJ31_AbsVelXStd";
CM_ SG_ 1534 RSDS_RR_PER_OBJ31_AbsVelX "RSDS_RR_PER_OBJ31_AbsVelX";
CM_ SG_ 1534 RSDS_RR_PER_OBJ31_AbsAccelYStd "RSDS_RR_PER_OBJ31_AbsAccelYStd";
CM_ SG_ 1534 RSDS_RR_PER_OBJ31_AbsAccelY "RSDS_RR_PER_OBJ31_AbsAccelY";
CM_ SG_ 1534 RSDS_RR_PER_OBJ31_AbsAccelXStd "RSDS_RR_PER_OBJ31_AbsAccelXStd";
CM_ SG_ 1534 RSDS_RR_PER_OBJ31_AbsAccelX "RSDS_RR_PER_OBJ31_AbsAccelX";
CM_ SG_ 1533 RSDS_RR_PER_OBJ30_YawRate "RSDS_RR_PER_OBJ30_YawRate";
CM_ SG_ 1533 RSDS_RR_PER_OBJ30_Width "RSDS_RR_PER_OBJ30_Width";
CM_ SG_ 1533 RSDS_RR_PER_OBJ30_ValidFlag "RSDS_RR_PER_OBJ30_ValidFlag";
CM_ SG_ 1533 RSDS_RR_PER_OBJ30_ObstProbabilit "RSDS_RR_PER_OBJ30_ObstProbability";
CM_ SG_ 1533 RSDS_RR_PER_OBJ30_MotionType "RSDS_RR_PER_OBJ30_MotionType";
CM_ SG_ 1533 RSDS_RR_PER_OBJ30_MeasState "RSDS_RR_PER_OBJ30_MeasState";
CM_ SG_ 1533 RSDS_RR_PER_OBJ30_LifeCycle "RSDS_RR_PER_OBJ30_LifeCycle";
CM_ SG_ 1533 RSDS_RR_PER_OBJ30_Length "RSDS_RR_PER_OBJ30_Length";
CM_ SG_ 1533 RSDS_RR_PER_OBJ30_ID "RSDS_RR_PER_OBJ30_ID";
CM_ SG_ 1533 RSDS_RR_PER_OBJ30_HeadingAng "RSDS_RR_PER_OBJ30_HeadingAng";
CM_ SG_ 1533 RSDS_RR_PER_OBJ30_ExistProb "RSDS_RR_PER_OBJ30_ExistProb";
CM_ SG_ 1533 RSDS_RR_PER_OBJ30_DistZStd "RSDS_RR_PER_OBJ30_DistZStd";
CM_ SG_ 1533 RSDS_RR_PER_OBJ30_DistZ "RSDS_RR_PER_OBJ30_DistZ";
CM_ SG_ 1533 RSDS_RR_PER_OBJ30_DistYStd "RSDS_RR_PER_OBJ30_DistYStd";
CM_ SG_ 1533 RSDS_RR_PER_OBJ30_DistY "RSDS_RR_PER_OBJ30_DistY";
CM_ SG_ 1533 RSDS_RR_PER_OBJ30_DistXStd "RSDS_RR_PER_OBJ30_DistXStd";
CM_ SG_ 1533 RSDS_RR_PER_OBJ30_DistX "RSDS_RR_PER_OBJ30_DistX";
CM_ SG_ 1533 RSDS_RR_PER_OBJ30_ClassTypeProb "RSDS_RR_PER_OBJ30_ClassTypeProb";
CM_ SG_ 1533 RSDS_RR_PER_OBJ30_ClassType "RSDS_RR_PER_OBJ30_ClassType";
CM_ SG_ 1533 RSDS_RR_PER_OBJ30_AbsVelYStd "RSDS_RR_PER_OBJ30_AbsVelYStd";
CM_ SG_ 1533 RSDS_RR_PER_OBJ30_AbsVelY "RSDS_RR_PER_OBJ30_AbsVelY";
CM_ SG_ 1533 RSDS_RR_PER_OBJ30_AbsVelXStd "RSDS_RR_PER_OBJ30_AbsVelXStd";
CM_ SG_ 1533 RSDS_RR_PER_OBJ30_AbsVelX "RSDS_RR_PER_OBJ30_AbsVelX";
CM_ SG_ 1533 RSDS_RR_PER_OBJ30_AbsAccelYStd "RSDS_RR_PER_OBJ30_AbsAccelYStd";
CM_ SG_ 1533 RSDS_RR_PER_OBJ30_AbsAccelY "RSDS_RR_PER_OBJ30_AbsAccelY";
CM_ SG_ 1533 RSDS_RR_PER_OBJ30_AbsAccelXStd "RSDS_RR_PER_OBJ30_AbsAccelXStd";
CM_ SG_ 1533 RSDS_RR_PER_OBJ30_AbsAccelX "RSDS_RR_PER_OBJ30_AbsAccelX";
CM_ SG_ 1532 RSDS_RR_PER_OBJ29_YawRate "RSDS_RR_PER_OBJ29_YawRate";
CM_ SG_ 1532 RSDS_RR_PER_OBJ29_Width "RSDS_RR_PER_OBJ29_Width";
CM_ SG_ 1532 RSDS_RR_PER_OBJ29_ValidFlag "RSDS_RR_PER_OBJ29_ValidFlag";
CM_ SG_ 1532 RSDS_RR_PER_OBJ29_ObstProbabilit "RSDS_RR_PER_OBJ29_ObstProbability";
CM_ SG_ 1532 RSDS_RR_PER_OBJ29_MotionType "RSDS_RR_PER_OBJ29_MotionType";
CM_ SG_ 1532 RSDS_RR_PER_OBJ29_MeasState "RSDS_RR_PER_OBJ29_MeasState";
CM_ SG_ 1532 RSDS_RR_PER_OBJ29_LifeCycle "RSDS_RR_PER_OBJ29_LifeCycle";
CM_ SG_ 1532 RSDS_RR_PER_OBJ29_Length "RSDS_RR_PER_OBJ29_Length";
CM_ SG_ 1532 RSDS_RR_PER_OBJ29_ID "RSDS_RR_PER_OBJ29_ID";
CM_ SG_ 1532 RSDS_RR_PER_OBJ29_HeadingAng "RSDS_RR_PER_OBJ29_HeadingAng";
CM_ SG_ 1532 RSDS_RR_PER_OBJ29_ExistProb "RSDS_RR_PER_OBJ29_ExistProb";
CM_ SG_ 1532 RSDS_RR_PER_OBJ29_DistZStd "RSDS_RR_PER_OBJ29_DistZStd";
CM_ SG_ 1532 RSDS_RR_PER_OBJ29_DistZ "RSDS_RR_PER_OBJ29_DistZ";
CM_ SG_ 1532 RSDS_RR_PER_OBJ29_DistYStd "RSDS_RR_PER_OBJ29_DistYStd";
CM_ SG_ 1532 RSDS_RR_PER_OBJ29_DistY "RSDS_RR_PER_OBJ29_DistY";
CM_ SG_ 1532 RSDS_RR_PER_OBJ29_DistXStd "RSDS_RR_PER_OBJ29_DistXStd";
CM_ SG_ 1532 RSDS_RR_PER_OBJ29_DistX "RSDS_RR_PER_OBJ29_DistX";
CM_ SG_ 1532 RSDS_RR_PER_OBJ29_ClassTypeProb "RSDS_RR_PER_OBJ29_ClassTypeProb";
CM_ SG_ 1532 RSDS_RR_PER_OBJ29_ClassType "RSDS_RR_PER_OBJ29_ClassType";
CM_ SG_ 1532 RSDS_RR_PER_OBJ29_AbsVelYStd "RSDS_RR_PER_OBJ29_AbsVelYStd";
CM_ SG_ 1532 RSDS_RR_PER_OBJ29_AbsVelY "RSDS_RR_PER_OBJ29_AbsVelY";
CM_ SG_ 1532 RSDS_RR_PER_OBJ29_AbsVelXStd "RSDS_RR_PER_OBJ29_AbsVelXStd";
CM_ SG_ 1532 RSDS_RR_PER_OBJ29_AbsVelX "RSDS_RR_PER_OBJ29_AbsVelX";
CM_ SG_ 1532 RSDS_RR_PER_OBJ29_AbsAccelYStd "RSDS_RR_PER_OBJ29_AbsAccelYStd";
CM_ SG_ 1532 RSDS_RR_PER_OBJ29_AbsAccelY "RSDS_RR_PER_OBJ29_AbsAccelY";
CM_ SG_ 1532 RSDS_RR_PER_OBJ29_AbsAccelXStd "RSDS_RR_PER_OBJ29_AbsAccelXStd";
CM_ SG_ 1532 RSDS_RR_PER_OBJ29_AbsAccelX "RSDS_RR_PER_OBJ29_AbsAccelX";
CM_ SG_ 1531 RSDS_RR_PER_OBJ28_YawRate "RSDS_RR_PER_OBJ28_YawRate";
CM_ SG_ 1531 RSDS_RR_PER_OBJ28_Width "RSDS_RR_PER_OBJ28_Width";
CM_ SG_ 1531 RSDS_RR_PER_OBJ28_ValidFlag "RSDS_RR_PER_OBJ28_ValidFlag";
CM_ SG_ 1531 RSDS_RR_PER_OBJ28_ObstProbabilit "RSDS_RR_PER_OBJ28_ObstProbability";
CM_ SG_ 1531 RSDS_RR_PER_OBJ28_MotionType "RSDS_RR_PER_OBJ28_MotionType";
CM_ SG_ 1531 RSDS_RR_PER_OBJ28_MeasState "RSDS_RR_PER_OBJ28_MeasState";
CM_ SG_ 1531 RSDS_RR_PER_OBJ28_LifeCycle "RSDS_RR_PER_OBJ28_LifeCycle";
CM_ SG_ 1531 RSDS_RR_PER_OBJ28_Length "RSDS_RR_PER_OBJ28_Length";
CM_ SG_ 1531 RSDS_RR_PER_OBJ28_ID "RSDS_RR_PER_OBJ28_ID";
CM_ SG_ 1531 RSDS_RR_PER_OBJ28_HeadingAng "RSDS_RR_PER_OBJ28_HeadingAng";
CM_ SG_ 1531 RSDS_RR_PER_OBJ28_ExistProb "RSDS_RR_PER_OBJ28_ExistProb";
CM_ SG_ 1531 RSDS_RR_PER_OBJ28_DistZStd "RSDS_RR_PER_OBJ28_DistZStd";
CM_ SG_ 1531 RSDS_RR_PER_OBJ28_DistZ "RSDS_RR_PER_OBJ28_DistZ";
CM_ SG_ 1531 RSDS_RR_PER_OBJ28_DistYStd "RSDS_RR_PER_OBJ28_DistYStd";
CM_ SG_ 1531 RSDS_RR_PER_OBJ28_DistY "RSDS_RR_PER_OBJ28_DistY";
CM_ SG_ 1531 RSDS_RR_PER_OBJ28_DistXStd "RSDS_RR_PER_OBJ28_DistXStd";
CM_ SG_ 1531 RSDS_RR_PER_OBJ28_DistX "RSDS_RR_PER_OBJ28_DistX";
CM_ SG_ 1531 RSDS_RR_PER_OBJ28_ClassTypeProb "RSDS_RR_PER_OBJ28_ClassTypeProb";
CM_ SG_ 1531 RSDS_RR_PER_OBJ28_ClassType "RSDS_RR_PER_OBJ28_ClassType";
CM_ SG_ 1531 RSDS_RR_PER_OBJ28_AbsVelYStd "RSDS_RR_PER_OBJ28_AbsVelYStd";
CM_ SG_ 1531 RSDS_RR_PER_OBJ28_AbsVelY "RSDS_RR_PER_OBJ28_AbsVelY";
CM_ SG_ 1531 RSDS_RR_PER_OBJ28_AbsVelXStd "RSDS_RR_PER_OBJ28_AbsVelXStd";
CM_ SG_ 1531 RSDS_RR_PER_OBJ28_AbsVelX "RSDS_RR_PER_OBJ28_AbsVelX";
CM_ SG_ 1531 RSDS_RR_PER_OBJ28_AbsAccelYStd "RSDS_RR_PER_OBJ28_AbsAccelYStd";
CM_ SG_ 1531 RSDS_RR_PER_OBJ28_AbsAccelY "RSDS_RR_PER_OBJ28_AbsAccelY";
CM_ SG_ 1531 RSDS_RR_PER_OBJ28_AbsAccelXStd "RSDS_RR_PER_OBJ28_AbsAccelXStd";
CM_ SG_ 1531 RSDS_RR_PER_OBJ28_AbsAccelX "RSDS_RR_PER_OBJ28_AbsAccelX";
CM_ SG_ 1530 RSDS_RR_PER_OBJ27_YawRate "RSDS_RR_PER_OBJ27_YawRate";
CM_ SG_ 1530 RSDS_RR_PER_OBJ27_Width "RSDS_RR_PER_OBJ27_Width";
CM_ SG_ 1530 RSDS_RR_PER_OBJ27_ValidFlag "RSDS_RR_PER_OBJ27_ValidFlag";
CM_ SG_ 1530 RSDS_RR_PER_OBJ27_ObstProbabilit "RSDS_RR_PER_OBJ27_ObstProbability";
CM_ SG_ 1530 RSDS_RR_PER_OBJ27_MotionType "RSDS_RR_PER_OBJ27_MotionType";
CM_ SG_ 1530 RSDS_RR_PER_OBJ27_MeasState "RSDS_RR_PER_OBJ27_MeasState";
CM_ SG_ 1530 RSDS_RR_PER_OBJ27_LifeCycle "RSDS_RR_PER_OBJ27_LifeCycle";
CM_ SG_ 1530 RSDS_RR_PER_OBJ27_Length "RSDS_RR_PER_OBJ27_Length";
CM_ SG_ 1530 RSDS_RR_PER_OBJ27_ID "RSDS_RR_PER_OBJ27_ID";
CM_ SG_ 1530 RSDS_RR_PER_OBJ27_HeadingAng "RSDS_RR_PER_OBJ27_HeadingAng";
CM_ SG_ 1530 RSDS_RR_PER_OBJ27_ExistProb "RSDS_RR_PER_OBJ27_ExistProb";
CM_ SG_ 1530 RSDS_RR_PER_OBJ27_DistZStd "RSDS_RR_PER_OBJ27_DistZStd";
CM_ SG_ 1530 RSDS_RR_PER_OBJ27_DistZ "RSDS_RR_PER_OBJ27_DistZ";
CM_ SG_ 1530 RSDS_RR_PER_OBJ27_DistYStd "RSDS_RR_PER_OBJ27_DistYStd";
CM_ SG_ 1530 RSDS_RR_PER_OBJ27_DistY "RSDS_RR_PER_OBJ27_DistY";
CM_ SG_ 1530 RSDS_RR_PER_OBJ27_DistXStd "RSDS_RR_PER_OBJ27_DistXStd";
CM_ SG_ 1530 RSDS_RR_PER_OBJ27_DistX "RSDS_RR_PER_OBJ27_DistX";
CM_ SG_ 1530 RSDS_RR_PER_OBJ27_ClassTypeProb "RSDS_RR_PER_OBJ27_ClassTypeProb";
CM_ SG_ 1530 RSDS_RR_PER_OBJ27_ClassType "RSDS_RR_PER_OBJ27_ClassType";
CM_ SG_ 1530 RSDS_RR_PER_OBJ27_AbsVelYStd "RSDS_RR_PER_OBJ27_AbsVelYStd";
CM_ SG_ 1530 RSDS_RR_PER_OBJ27_AbsVelY "RSDS_RR_PER_OBJ27_AbsVelY";
CM_ SG_ 1530 RSDS_RR_PER_OBJ27_AbsVelXStd "RSDS_RR_PER_OBJ27_AbsVelXStd";
CM_ SG_ 1530 RSDS_RR_PER_OBJ27_AbsVelX "RSDS_RR_PER_OBJ27_AbsVelX";
CM_ SG_ 1530 RSDS_RR_PER_OBJ27_AbsAccelYStd "RSDS_RR_PER_OBJ27_AbsAccelYStd";
CM_ SG_ 1530 RSDS_RR_PER_OBJ27_AbsAccelY "RSDS_RR_PER_OBJ27_AbsAccelY";
CM_ SG_ 1530 RSDS_RR_PER_OBJ27_AbsAccelXStd "RSDS_RR_PER_OBJ27_AbsAccelXStd";
CM_ SG_ 1530 RSDS_RR_PER_OBJ27_AbsAccelX "RSDS_RR_PER_OBJ27_AbsAccelX";
CM_ SG_ 1529 RSDS_RR_PER_OBJ26_YawRate "RSDS_RR_PER_OBJ26_YawRate";
CM_ SG_ 1529 RSDS_RR_PER_OBJ26_Width "RSDS_RR_PER_OBJ26_Width";
CM_ SG_ 1529 RSDS_RR_PER_OBJ26_ValidFlag "RSDS_RR_PER_OBJ26_ValidFlag";
CM_ SG_ 1529 RSDS_RR_PER_OBJ26_ObstProbabilit "RSDS_RR_PER_OBJ26_ObstProbability";
CM_ SG_ 1529 RSDS_RR_PER_OBJ26_MotionType "RSDS_RR_PER_OBJ26_MotionType";
CM_ SG_ 1529 RSDS_RR_PER_OBJ26_MeasState "RSDS_RR_PER_OBJ26_MeasState";
CM_ SG_ 1529 RSDS_RR_PER_OBJ26_LifeCycle "RSDS_RR_PER_OBJ26_LifeCycle";
CM_ SG_ 1529 RSDS_RR_PER_OBJ26_Length "RSDS_RR_PER_OBJ26_Length";
CM_ SG_ 1529 RSDS_RR_PER_OBJ26_ID "RSDS_RR_PER_OBJ26_ID";
CM_ SG_ 1529 RSDS_RR_PER_OBJ26_HeadingAng "RSDS_RR_PER_OBJ26_HeadingAng";
CM_ SG_ 1529 RSDS_RR_PER_OBJ26_ExistProb "RSDS_RR_PER_OBJ26_ExistProb";
CM_ SG_ 1529 RSDS_RR_PER_OBJ26_DistZStd "RSDS_RR_PER_OBJ26_DistZStd";
CM_ SG_ 1529 RSDS_RR_PER_OBJ26_DistZ "RSDS_RR_PER_OBJ26_DistZ";
CM_ SG_ 1529 RSDS_RR_PER_OBJ26_DistYStd "RSDS_RR_PER_OBJ26_DistYStd";
CM_ SG_ 1529 RSDS_RR_PER_OBJ26_DistY "RSDS_RR_PER_OBJ26_DistY";
CM_ SG_ 1529 RSDS_RR_PER_OBJ26_DistXStd "RSDS_RR_PER_OBJ26_DistXStd";
CM_ SG_ 1529 RSDS_RR_PER_OBJ26_DistX "RSDS_RR_PER_OBJ26_DistX";
CM_ SG_ 1529 RSDS_RR_PER_OBJ26_ClassTypeProb "RSDS_RR_PER_OBJ26_ClassTypeProb";
CM_ SG_ 1529 RSDS_RR_PER_OBJ26_ClassType "RSDS_RR_PER_OBJ26_ClassType";
CM_ SG_ 1529 RSDS_RR_PER_OBJ26_AbsVelYStd "RSDS_RR_PER_OBJ26_AbsVelYStd";
CM_ SG_ 1529 RSDS_RR_PER_OBJ26_AbsVelY "RSDS_RR_PER_OBJ26_AbsVelY";
CM_ SG_ 1529 RSDS_RR_PER_OBJ26_AbsVelXStd "RSDS_RR_PER_OBJ26_AbsVelXStd";
CM_ SG_ 1529 RSDS_RR_PER_OBJ26_AbsVelX "RSDS_RR_PER_OBJ26_AbsVelX";
CM_ SG_ 1529 RSDS_RR_PER_OBJ26_AbsAccelYStd "RSDS_RR_PER_OBJ26_AbsAccelYStd";
CM_ SG_ 1529 RSDS_RR_PER_OBJ26_AbsAccelY "RSDS_RR_PER_OBJ26_AbsAccelY";
CM_ SG_ 1529 RSDS_RR_PER_OBJ26_AbsAccelXStd "RSDS_RR_PER_OBJ26_AbsAccelXStd";
CM_ SG_ 1529 RSDS_RR_PER_OBJ26_AbsAccelX "RSDS_RR_PER_OBJ26_AbsAccelX";
CM_ SG_ 1528 RSDS_RR_PER_OBJ25_YawRate "RSDS_RR_PER_OBJ25_YawRate";
CM_ SG_ 1528 RSDS_RR_PER_OBJ25_Width "RSDS_RR_PER_OBJ25_Width";
CM_ SG_ 1528 RSDS_RR_PER_OBJ25_ValidFlag "RSDS_RR_PER_OBJ25_ValidFlag";
CM_ SG_ 1528 RSDS_RR_PER_OBJ25_ObstProbabilit "RSDS_RR_PER_OBJ25_ObstProbability";
CM_ SG_ 1528 RSDS_RR_PER_OBJ25_MotionType "RSDS_RR_PER_OBJ25_MotionType";
CM_ SG_ 1528 RSDS_RR_PER_OBJ25_MeasState "RSDS_RR_PER_OBJ25_MeasState";
CM_ SG_ 1528 RSDS_RR_PER_OBJ25_LifeCycle "RSDS_RR_PER_OBJ25_LifeCycle";
CM_ SG_ 1528 RSDS_RR_PER_OBJ25_Length "RSDS_RR_PER_OBJ25_Length";
CM_ SG_ 1528 RSDS_RR_PER_OBJ25_ID "RSDS_RR_PER_OBJ25_ID";
CM_ SG_ 1528 RSDS_RR_PER_OBJ25_HeadingAng "RSDS_RR_PER_OBJ25_HeadingAng";
CM_ SG_ 1528 RSDS_RR_PER_OBJ25_ExistProb "RSDS_RR_PER_OBJ25_ExistProb";
CM_ SG_ 1528 RSDS_RR_PER_OBJ25_DistZStd "RSDS_RR_PER_OBJ25_DistZStd";
CM_ SG_ 1528 RSDS_RR_PER_OBJ25_DistZ "RSDS_RR_PER_OBJ25_DistZ";
CM_ SG_ 1528 RSDS_RR_PER_OBJ25_DistYStd "RSDS_RR_PER_OBJ25_DistYStd";
CM_ SG_ 1528 RSDS_RR_PER_OBJ25_DistY "RSDS_RR_PER_OBJ25_DistY";
CM_ SG_ 1528 RSDS_RR_PER_OBJ25_DistXStd "RSDS_RR_PER_OBJ25_DistXStd";
CM_ SG_ 1528 RSDS_RR_PER_OBJ25_DistX "RSDS_RR_PER_OBJ25_DistX";
CM_ SG_ 1528 RSDS_RR_PER_OBJ25_ClassTypeProb "RSDS_RR_PER_OBJ25_ClassTypeProb";
CM_ SG_ 1528 RSDS_RR_PER_OBJ25_ClassType "RSDS_RR_PER_OBJ25_ClassType";
CM_ SG_ 1528 RSDS_RR_PER_OBJ25_AbsVelYStd "RSDS_RR_PER_OBJ25_AbsVelYStd";
CM_ SG_ 1528 RSDS_RR_PER_OBJ25_AbsVelY "RSDS_RR_PER_OBJ25_AbsVelY";
CM_ SG_ 1528 RSDS_RR_PER_OBJ25_AbsVelXStd "RSDS_RR_PER_OBJ25_AbsVelXStd";
CM_ SG_ 1528 RSDS_RR_PER_OBJ25_AbsVelX "RSDS_RR_PER_OBJ25_AbsVelX";
CM_ SG_ 1528 RSDS_RR_PER_OBJ25_AbsAccelYStd "RSDS_RR_PER_OBJ25_AbsAccelYStd";
CM_ SG_ 1528 RSDS_RR_PER_OBJ25_AbsAccelY "RSDS_RR_PER_OBJ25_AbsAccelY";
CM_ SG_ 1528 RSDS_RR_PER_OBJ25_AbsAccelXStd "RSDS_RR_PER_OBJ25_AbsAccelXStd";
CM_ SG_ 1528 RSDS_RR_PER_OBJ25_AbsAccelX "RSDS_RR_PER_OBJ25_AbsAccelX";
CM_ SG_ 1527 RSDS_RR_PER_OBJ24_YawRate "RSDS_RR_PER_OBJ24_YawRate";
CM_ SG_ 1527 RSDS_RR_PER_OBJ24_Width "RSDS_RR_PER_OBJ24_Width";
CM_ SG_ 1527 RSDS_RR_PER_OBJ24_ValidFlag "RSDS_RR_PER_OBJ24_ValidFlag";
CM_ SG_ 1527 RSDS_RR_PER_OBJ24_ObstProbabilit "RSDS_RR_PER_OBJ24_ObstProbability";
CM_ SG_ 1527 RSDS_RR_PER_OBJ24_MotionType "RSDS_RR_PER_OBJ24_MotionType";
CM_ SG_ 1527 RSDS_RR_PER_OBJ24_MeasState "RSDS_RR_PER_OBJ24_MeasState";
CM_ SG_ 1527 RSDS_RR_PER_OBJ24_LifeCycle "RSDS_RR_PER_OBJ24_LifeCycle";
CM_ SG_ 1527 RSDS_RR_PER_OBJ24_Length "RSDS_RR_PER_OBJ24_Length";
CM_ SG_ 1527 RSDS_RR_PER_OBJ24_ID "RSDS_RR_PER_OBJ24_ID";
CM_ SG_ 1527 RSDS_RR_PER_OBJ24_HeadingAng "RSDS_RR_PER_OBJ24_HeadingAng";
CM_ SG_ 1527 RSDS_RR_PER_OBJ24_ExistProb "RSDS_RR_PER_OBJ24_ExistProb";
CM_ SG_ 1527 RSDS_RR_PER_OBJ24_DistZStd "RSDS_RR_PER_OBJ24_DistZStd";
CM_ SG_ 1527 RSDS_RR_PER_OBJ24_DistZ "RSDS_RR_PER_OBJ24_DistZ";
CM_ SG_ 1527 RSDS_RR_PER_OBJ24_DistYStd "RSDS_RR_PER_OBJ24_DistYStd";
CM_ SG_ 1527 RSDS_RR_PER_OBJ24_DistY "RSDS_RR_PER_OBJ24_DistY";
CM_ SG_ 1527 RSDS_RR_PER_OBJ24_DistXStd "RSDS_RR_PER_OBJ24_DistXStd";
CM_ SG_ 1527 RSDS_RR_PER_OBJ24_DistX "RSDS_RR_PER_OBJ24_DistX";
CM_ SG_ 1527 RSDS_RR_PER_OBJ24_ClassTypeProb "RSDS_RR_PER_OBJ24_ClassTypeProb";
CM_ SG_ 1527 RSDS_RR_PER_OBJ24_ClassType "RSDS_RR_PER_OBJ24_ClassType";
CM_ SG_ 1527 RSDS_RR_PER_OBJ24_AbsVelYStd "RSDS_RR_PER_OBJ24_AbsVelYStd";
CM_ SG_ 1527 RSDS_RR_PER_OBJ24_AbsVelY "RSDS_RR_PER_OBJ24_AbsVelY";
CM_ SG_ 1527 RSDS_RR_PER_OBJ24_AbsVelXStd "RSDS_RR_PER_OBJ24_AbsVelXStd";
CM_ SG_ 1527 RSDS_RR_PER_OBJ24_AbsVelX "RSDS_RR_PER_OBJ24_AbsVelX";
CM_ SG_ 1527 RSDS_RR_PER_OBJ24_AbsAccelYStd "RSDS_RR_PER_OBJ24_AbsAccelYStd";
CM_ SG_ 1527 RSDS_RR_PER_OBJ24_AbsAccelY "RSDS_RR_PER_OBJ24_AbsAccelY";
CM_ SG_ 1527 RSDS_RR_PER_OBJ24_AbsAccelXStd "RSDS_RR_PER_OBJ24_AbsAccelXStd";
CM_ SG_ 1527 RSDS_RR_PER_OBJ24_AbsAccelX "RSDS_RR_PER_OBJ24_AbsAccelX";
CM_ SG_ 1526 RSDS_RR_PER_OBJ23_YawRate "RSDS_RR_PER_OBJ23_YawRate";
CM_ SG_ 1526 RSDS_RR_PER_OBJ23_Width "RSDS_RR_PER_OBJ23_Width";
CM_ SG_ 1526 RSDS_RR_PER_OBJ23_ValidFlag "RSDS_RR_PER_OBJ23_ValidFlag";
CM_ SG_ 1526 RSDS_RR_PER_OBJ23_ObstProbabilit "RSDS_RR_PER_OBJ23_ObstProbability";
CM_ SG_ 1526 RSDS_RR_PER_OBJ23_MotionType "RSDS_RR_PER_OBJ23_MotionType";
CM_ SG_ 1526 RSDS_RR_PER_OBJ23_MeasState "RSDS_RR_PER_OBJ23_MeasState";
CM_ SG_ 1526 RSDS_RR_PER_OBJ23_LifeCycle "RSDS_RR_PER_OBJ23_LifeCycle";
CM_ SG_ 1526 RSDS_RR_PER_OBJ23_Length "RSDS_RR_PER_OBJ23_Length";
CM_ SG_ 1526 RSDS_RR_PER_OBJ23_ID "RSDS_RR_PER_OBJ23_ID";
CM_ SG_ 1526 RSDS_RR_PER_OBJ23_HeadingAng "RSDS_RR_PER_OBJ23_HeadingAng";
CM_ SG_ 1526 RSDS_RR_PER_OBJ23_ExistProb "RSDS_RR_PER_OBJ23_ExistProb";
CM_ SG_ 1526 RSDS_RR_PER_OBJ23_DistZStd "RSDS_RR_PER_OBJ23_DistZStd";
CM_ SG_ 1526 RSDS_RR_PER_OBJ23_DistZ "RSDS_RR_PER_OBJ23_DistZ";
CM_ SG_ 1526 RSDS_RR_PER_OBJ23_DistYStd "RSDS_RR_PER_OBJ23_DistYStd";
CM_ SG_ 1526 RSDS_RR_PER_OBJ23_DistY "RSDS_RR_PER_OBJ23_DistY";
CM_ SG_ 1526 RSDS_RR_PER_OBJ23_DistXStd "RSDS_RR_PER_OBJ23_DistXStd";
CM_ SG_ 1526 RSDS_RR_PER_OBJ23_DistX "RSDS_RR_PER_OBJ23_DistX";
CM_ SG_ 1526 RSDS_RR_PER_OBJ23_ClassTypeProb "RSDS_RR_PER_OBJ23_ClassTypeProb";
CM_ SG_ 1526 RSDS_RR_PER_OBJ23_ClassType "RSDS_RR_PER_OBJ23_ClassType";
CM_ SG_ 1526 RSDS_RR_PER_OBJ23_AbsVelYStd "RSDS_RR_PER_OBJ23_AbsVelYStd";
CM_ SG_ 1526 RSDS_RR_PER_OBJ23_AbsVelY "RSDS_RR_PER_OBJ23_AbsVelY";
CM_ SG_ 1526 RSDS_RR_PER_OBJ23_AbsVelXStd "RSDS_RR_PER_OBJ23_AbsVelXStd";
CM_ SG_ 1526 RSDS_RR_PER_OBJ23_AbsVelX "RSDS_RR_PER_OBJ23_AbsVelX";
CM_ SG_ 1526 RSDS_RR_PER_OBJ23_AbsAccelYStd "RSDS_RR_PER_OBJ23_AbsAccelYStd";
CM_ SG_ 1526 RSDS_RR_PER_OBJ23_AbsAccelY "RSDS_RR_PER_OBJ23_AbsAccelY";
CM_ SG_ 1526 RSDS_RR_PER_OBJ23_AbsAccelXStd "RSDS_RR_PER_OBJ23_AbsAccelXStd";
CM_ SG_ 1526 RSDS_RR_PER_OBJ23_AbsAccelX "RSDS_RR_PER_OBJ23_AbsAccelX";
CM_ SG_ 1525 RSDS_RR_PER_OBJ22_YawRate "RSDS_RR_PER_OBJ22_YawRate";
CM_ SG_ 1525 RSDS_RR_PER_OBJ22_Width "RSDS_RR_PER_OBJ22_Width";
CM_ SG_ 1525 RSDS_RR_PER_OBJ22_ValidFlag "RSDS_RR_PER_OBJ22_ValidFlag";
CM_ SG_ 1525 RSDS_RR_PER_OBJ22_ObstProbabilit "RSDS_RR_PER_OBJ22_ObstProbability";
CM_ SG_ 1525 RSDS_RR_PER_OBJ22_MotionType "RSDS_RR_PER_OBJ22_MotionType";
CM_ SG_ 1525 RSDS_RR_PER_OBJ22_MeasState "RSDS_RR_PER_OBJ22_MeasState";
CM_ SG_ 1525 RSDS_RR_PER_OBJ22_LifeCycle "RSDS_RR_PER_OBJ22_LifeCycle";
CM_ SG_ 1525 RSDS_RR_PER_OBJ22_Length "RSDS_RR_PER_OBJ22_Length";
CM_ SG_ 1525 RSDS_RR_PER_OBJ22_ID "RSDS_RR_PER_OBJ22_ID";
CM_ SG_ 1525 RSDS_RR_PER_OBJ22_HeadingAng "RSDS_RR_PER_OBJ22_HeadingAng";
CM_ SG_ 1525 RSDS_RR_PER_OBJ22_ExistProb "RSDS_RR_PER_OBJ22_ExistProb";
CM_ SG_ 1525 RSDS_RR_PER_OBJ22_DistZStd "RSDS_RR_PER_OBJ22_DistZStd";
CM_ SG_ 1525 RSDS_RR_PER_OBJ22_DistZ "RSDS_RR_PER_OBJ22_DistZ";
CM_ SG_ 1525 RSDS_RR_PER_OBJ22_DistYStd "RSDS_RR_PER_OBJ22_DistYStd";
CM_ SG_ 1525 RSDS_RR_PER_OBJ22_DistY "RSDS_RR_PER_OBJ22_DistY";
CM_ SG_ 1525 RSDS_RR_PER_OBJ22_DistXStd "RSDS_RR_PER_OBJ22_DistXStd";
CM_ SG_ 1525 RSDS_RR_PER_OBJ22_DistX "RSDS_RR_PER_OBJ22_DistX";
CM_ SG_ 1525 RSDS_RR_PER_OBJ22_ClassTypeProb "RSDS_RR_PER_OBJ22_ClassTypeProb";
CM_ SG_ 1525 RSDS_RR_PER_OBJ22_ClassType "RSDS_RR_PER_OBJ22_ClassType";
CM_ SG_ 1525 RSDS_RR_PER_OBJ22_AbsVelYStd "RSDS_RR_PER_OBJ22_AbsVelYStd";
CM_ SG_ 1525 RSDS_RR_PER_OBJ22_AbsVelY "RSDS_RR_PER_OBJ22_AbsVelY";
CM_ SG_ 1525 RSDS_RR_PER_OBJ22_AbsVelXStd "RSDS_RR_PER_OBJ22_AbsVelXStd";
CM_ SG_ 1525 RSDS_RR_PER_OBJ22_AbsVelX "RSDS_RR_PER_OBJ22_AbsVelX";
CM_ SG_ 1525 RSDS_RR_PER_OBJ22_AbsAccelYStd "RSDS_RR_PER_OBJ22_AbsAccelYStd";
CM_ SG_ 1525 RSDS_RR_PER_OBJ22_AbsAccelY "RSDS_RR_PER_OBJ22_AbsAccelY";
CM_ SG_ 1525 RSDS_RR_PER_OBJ22_AbsAccelXStd "RSDS_RR_PER_OBJ22_AbsAccelXStd";
CM_ SG_ 1525 RSDS_RR_PER_OBJ22_AbsAccelX "RSDS_RR_PER_OBJ22_AbsAccelX";
CM_ SG_ 1524 RSDS_RR_PER_OBJ21_YawRate "RSDS_RR_PER_OBJ21_YawRate";
CM_ SG_ 1524 RSDS_RR_PER_OBJ21_Width "RSDS_RR_PER_OBJ21_Width";
CM_ SG_ 1524 RSDS_RR_PER_OBJ21_ValidFlag "RSDS_RR_PER_OBJ21_ValidFlag";
CM_ SG_ 1524 RSDS_RR_PER_OBJ21_ObstProbabilit "RSDS_RR_PER_OBJ21_ObstProbability";
CM_ SG_ 1524 RSDS_RR_PER_OBJ21_MotionType "RSDS_RR_PER_OBJ21_MotionType";
CM_ SG_ 1524 RSDS_RR_PER_OBJ21_MeasState "RSDS_RR_PER_OBJ21_MeasState";
CM_ SG_ 1524 RSDS_RR_PER_OBJ21_LifeCycle "RSDS_RR_PER_OBJ21_LifeCycle";
CM_ SG_ 1524 RSDS_RR_PER_OBJ21_Length "RSDS_RR_PER_OBJ21_Length";
CM_ SG_ 1524 RSDS_RR_PER_OBJ21_ID "RSDS_RR_PER_OBJ21_ID";
CM_ SG_ 1524 RSDS_RR_PER_OBJ21_HeadingAng "RSDS_RR_PER_OBJ21_HeadingAng";
CM_ SG_ 1524 RSDS_RR_PER_OBJ21_ExistProb "RSDS_RR_PER_OBJ21_ExistProb";
CM_ SG_ 1524 RSDS_RR_PER_OBJ21_DistZStd "RSDS_RR_PER_OBJ21_DistZStd";
CM_ SG_ 1524 RSDS_RR_PER_OBJ21_DistZ "RSDS_RR_PER_OBJ21_DistZ";
CM_ SG_ 1524 RSDS_RR_PER_OBJ21_DistYStd "RSDS_RR_PER_OBJ21_DistYStd";
CM_ SG_ 1524 RSDS_RR_PER_OBJ21_DistY "RSDS_RR_PER_OBJ21_DistY";
CM_ SG_ 1524 RSDS_RR_PER_OBJ21_DistXStd "RSDS_RR_PER_OBJ21_DistXStd";
CM_ SG_ 1524 RSDS_RR_PER_OBJ21_DistX "RSDS_RR_PER_OBJ21_DistX";
CM_ SG_ 1524 RSDS_RR_PER_OBJ21_ClassTypeProb "RSDS_RR_PER_OBJ21_ClassTypeProb";
CM_ SG_ 1524 RSDS_RR_PER_OBJ21_ClassType "RSDS_RR_PER_OBJ21_ClassType";
CM_ SG_ 1524 RSDS_RR_PER_OBJ21_AbsVelYStd "RSDS_RR_PER_OBJ21_AbsVelYStd";
CM_ SG_ 1524 RSDS_RR_PER_OBJ21_AbsVelY "RSDS_RR_PER_OBJ21_AbsVelY";
CM_ SG_ 1524 RSDS_RR_PER_OBJ21_AbsVelXStd "RSDS_RR_PER_OBJ21_AbsVelXStd";
CM_ SG_ 1524 RSDS_RR_PER_OBJ21_AbsVelX "RSDS_RR_PER_OBJ21_AbsVelX";
CM_ SG_ 1524 RSDS_RR_PER_OBJ21_AbsAccelYStd "RSDS_RR_PER_OBJ21_AbsAccelYStd";
CM_ SG_ 1524 RSDS_RR_PER_OBJ21_AbsAccelY "RSDS_RR_PER_OBJ21_AbsAccelY";
CM_ SG_ 1524 RSDS_RR_PER_OBJ21_AbsAccelXStd "RSDS_RR_PER_OBJ21_AbsAccelXStd";
CM_ SG_ 1524 RSDS_RR_PER_OBJ21_AbsAccelX "RSDS_RR_PER_OBJ21_AbsAccelX";
CM_ SG_ 1523 RSDS_RR_PER_OBJ20_YawRate "RSDS_RR_PER_OBJ20_YawRate";
CM_ SG_ 1523 RSDS_RR_PER_OBJ20_Width "RSDS_RR_PER_OBJ20_Width";
CM_ SG_ 1523 RSDS_RR_PER_OBJ20_ValidFlag "RSDS_RR_PER_OBJ20_ValidFlag";
CM_ SG_ 1523 RSDS_RR_PER_OBJ20_ObstProbabilit "RSDS_RR_PER_OBJ20_ObstProbability";
CM_ SG_ 1523 RSDS_RR_PER_OBJ20_MotionType "RSDS_RR_PER_OBJ20_MotionType";
CM_ SG_ 1523 RSDS_RR_PER_OBJ20_MeasState "RSDS_RR_PER_OBJ20_MeasState";
CM_ SG_ 1523 RSDS_RR_PER_OBJ20_LifeCycle "RSDS_RR_PER_OBJ20_LifeCycle";
CM_ SG_ 1523 RSDS_RR_PER_OBJ20_Length "RSDS_RR_PER_OBJ20_Length";
CM_ SG_ 1523 RSDS_RR_PER_OBJ20_ID "RSDS_RR_PER_OBJ20_ID";
CM_ SG_ 1523 RSDS_RR_PER_OBJ20_HeadingAng "RSDS_RR_PER_OBJ20_HeadingAng";
CM_ SG_ 1523 RSDS_RR_PER_OBJ20_ExistProb "RSDS_RR_PER_OBJ20_ExistProb";
CM_ SG_ 1523 RSDS_RR_PER_OBJ20_DistZStd "RSDS_RR_PER_OBJ20_DistZStd";
CM_ SG_ 1523 RSDS_RR_PER_OBJ20_DistZ "RSDS_RR_PER_OBJ20_DistZ";
CM_ SG_ 1523 RSDS_RR_PER_OBJ20_DistYStd "RSDS_RR_PER_OBJ20_DistYStd";
CM_ SG_ 1523 RSDS_RR_PER_OBJ20_DistY "RSDS_RR_PER_OBJ20_DistY";
CM_ SG_ 1523 RSDS_RR_PER_OBJ20_DistXStd "RSDS_RR_PER_OBJ20_DistXStd";
CM_ SG_ 1523 RSDS_RR_PER_OBJ20_DistX "RSDS_RR_PER_OBJ20_DistX";
CM_ SG_ 1523 RSDS_RR_PER_OBJ20_ClassTypeProb "RSDS_RR_PER_OBJ20_ClassTypeProb";
CM_ SG_ 1523 RSDS_RR_PER_OBJ20_ClassType "RSDS_RR_PER_OBJ20_ClassType";
CM_ SG_ 1523 RSDS_RR_PER_OBJ20_AbsVelYStd "RSDS_RR_PER_OBJ20_AbsVelYStd";
CM_ SG_ 1523 RSDS_RR_PER_OBJ20_AbsVelY "RSDS_RR_PER_OBJ20_AbsVelY";
CM_ SG_ 1523 RSDS_RR_PER_OBJ20_AbsVelXStd "RSDS_RR_PER_OBJ20_AbsVelXStd";
CM_ SG_ 1523 RSDS_RR_PER_OBJ20_AbsVelX "RSDS_RR_PER_OBJ20_AbsVelX";
CM_ SG_ 1523 RSDS_RR_PER_OBJ20_AbsAccelYStd "RSDS_RR_PER_OBJ20_AbsAccelYStd";
CM_ SG_ 1523 RSDS_RR_PER_OBJ20_AbsAccelY "RSDS_RR_PER_OBJ20_AbsAccelY";
CM_ SG_ 1523 RSDS_RR_PER_OBJ20_AbsAccelXStd "RSDS_RR_PER_OBJ20_AbsAccelXStd";
CM_ SG_ 1523 RSDS_RR_PER_OBJ20_AbsAccelX "RSDS_RR_PER_OBJ20_AbsAccelX";
CM_ SG_ 1522 RSDS_RR_PER_OBJ19_YawRate "RSDS_RR_PER_OBJ19_YawRate";
CM_ SG_ 1522 RSDS_RR_PER_OBJ19_Width "RSDS_RR_PER_OBJ19_Width";
CM_ SG_ 1522 RSDS_RR_PER_OBJ19_ValidFlag "RSDS_RR_PER_OBJ19_ValidFlag";
CM_ SG_ 1522 RSDS_RR_PER_OBJ19_ObstProbabilit "RSDS_RR_PER_OBJ19_ObstProbability";
CM_ SG_ 1522 RSDS_RR_PER_OBJ19_MotionType "RSDS_RR_PER_OBJ19_MotionType";
CM_ SG_ 1522 RSDS_RR_PER_OBJ19_MeasState "RSDS_RR_PER_OBJ19_MeasState";
CM_ SG_ 1522 RSDS_RR_PER_OBJ19_LifeCycle "RSDS_RR_PER_OBJ19_LifeCycle";
CM_ SG_ 1522 RSDS_RR_PER_OBJ19_Length "RSDS_RR_PER_OBJ19_Length";
CM_ SG_ 1522 RSDS_RR_PER_OBJ19_ID "RSDS_RR_PER_OBJ19_ID";
CM_ SG_ 1522 RSDS_RR_PER_OBJ19_HeadingAng "RSDS_RR_PER_OBJ19_HeadingAng";
CM_ SG_ 1522 RSDS_RR_PER_OBJ19_ExistProb "RSDS_RR_PER_OBJ19_ExistProb";
CM_ SG_ 1522 RSDS_RR_PER_OBJ19_DistZStd "RSDS_RR_PER_OBJ19_DistZStd";
CM_ SG_ 1522 RSDS_RR_PER_OBJ19_DistZ "RSDS_RR_PER_OBJ19_DistZ";
CM_ SG_ 1522 RSDS_RR_PER_OBJ19_DistYStd "RSDS_RR_PER_OBJ19_DistYStd";
CM_ SG_ 1522 RSDS_RR_PER_OBJ19_DistY "RSDS_RR_PER_OBJ19_DistY";
CM_ SG_ 1522 RSDS_RR_PER_OBJ19_DistXStd "RSDS_RR_PER_OBJ19_DistXStd";
CM_ SG_ 1522 RSDS_RR_PER_OBJ19_DistX "RSDS_RR_PER_OBJ19_DistX";
CM_ SG_ 1522 RSDS_RR_PER_OBJ19_ClassTypeProb "RSDS_RR_PER_OBJ19_ClassTypeProb";
CM_ SG_ 1522 RSDS_RR_PER_OBJ19_ClassType "RSDS_RR_PER_OBJ19_ClassType";
CM_ SG_ 1522 RSDS_RR_PER_OBJ19_AbsVelYStd "RSDS_RR_PER_OBJ19_AbsVelYStd";
CM_ SG_ 1522 RSDS_RR_PER_OBJ19_AbsVelY "RSDS_RR_PER_OBJ19_AbsVelY";
CM_ SG_ 1522 RSDS_RR_PER_OBJ19_AbsVelXStd "RSDS_RR_PER_OBJ19_AbsVelXStd";
CM_ SG_ 1522 RSDS_RR_PER_OBJ19_AbsVelX "RSDS_RR_PER_OBJ19_AbsVelX";
CM_ SG_ 1522 RSDS_RR_PER_OBJ19_AbsAccelYStd "RSDS_RR_PER_OBJ19_AbsAccelYStd";
CM_ SG_ 1522 RSDS_RR_PER_OBJ19_AbsAccelY "RSDS_RR_PER_OBJ19_AbsAccelY";
CM_ SG_ 1522 RSDS_RR_PER_OBJ19_AbsAccelXStd "RSDS_RR_PER_OBJ19_AbsAccelXStd";
CM_ SG_ 1522 RSDS_RR_PER_OBJ19_AbsAccelX "RSDS_RR_PER_OBJ19_AbsAccelX";
CM_ SG_ 1521 RSDS_RR_PER_OBJ18_YawRate "RSDS_RR_PER_OBJ18_YawRate";
CM_ SG_ 1521 RSDS_RR_PER_OBJ18_Width "RSDS_RR_PER_OBJ18_Width";
CM_ SG_ 1521 RSDS_RR_PER_OBJ18_ValidFlag "RSDS_RR_PER_OBJ18_ValidFlag";
CM_ SG_ 1521 RSDS_RR_PER_OBJ18_ObstProbabilit "RSDS_RR_PER_OBJ18_ObstProbability";
CM_ SG_ 1521 RSDS_RR_PER_OBJ18_MotionType "RSDS_RR_PER_OBJ18_MotionType";
CM_ SG_ 1521 RSDS_RR_PER_OBJ18_MeasState "RSDS_RR_PER_OBJ18_MeasState";
CM_ SG_ 1521 RSDS_RR_PER_OBJ18_LifeCycle "RSDS_RR_PER_OBJ18_LifeCycle";
CM_ SG_ 1521 RSDS_RR_PER_OBJ18_Length "RSDS_RR_PER_OBJ18_Length";
CM_ SG_ 1521 RSDS_RR_PER_OBJ18_ID "RSDS_RR_PER_OBJ18_ID";
CM_ SG_ 1521 RSDS_RR_PER_OBJ18_HeadingAng "RSDS_RR_PER_OBJ18_HeadingAng";
CM_ SG_ 1521 RSDS_RR_PER_OBJ18_ExistProb "RSDS_RR_PER_OBJ18_ExistProb";
CM_ SG_ 1521 RSDS_RR_PER_OBJ18_DistZStd "RSDS_RR_PER_OBJ18_DistZStd";
CM_ SG_ 1521 RSDS_RR_PER_OBJ18_DistZ "RSDS_RR_PER_OBJ18_DistZ";
CM_ SG_ 1521 RSDS_RR_PER_OBJ18_DistYStd "RSDS_RR_PER_OBJ18_DistYStd";
CM_ SG_ 1521 RSDS_RR_PER_OBJ18_DistY "RSDS_RR_PER_OBJ18_DistY";
CM_ SG_ 1521 RSDS_RR_PER_OBJ18_DistXStd "RSDS_RR_PER_OBJ18_DistXStd";
CM_ SG_ 1521 RSDS_RR_PER_OBJ18_DistX "RSDS_RR_PER_OBJ18_DistX";
CM_ SG_ 1521 RSDS_RR_PER_OBJ18_ClassTypeProb "RSDS_RR_PER_OBJ18_ClassTypeProb";
CM_ SG_ 1521 RSDS_RR_PER_OBJ18_ClassType "RSDS_RR_PER_OBJ18_ClassType";
CM_ SG_ 1521 RSDS_RR_PER_OBJ18_AbsVelYStd "RSDS_RR_PER_OBJ18_AbsVelYStd";
CM_ SG_ 1521 RSDS_RR_PER_OBJ18_AbsVelY "RSDS_RR_PER_OBJ18_AbsVelY";
CM_ SG_ 1521 RSDS_RR_PER_OBJ18_AbsVelXStd "RSDS_RR_PER_OBJ18_AbsVelXStd";
CM_ SG_ 1521 RSDS_RR_PER_OBJ18_AbsVelX "RSDS_RR_PER_OBJ18_AbsVelX";
CM_ SG_ 1521 RSDS_RR_PER_OBJ18_AbsAccelYStd "RSDS_RR_PER_OBJ18_AbsAccelYStd";
CM_ SG_ 1521 RSDS_RR_PER_OBJ18_AbsAccelY "RSDS_RR_PER_OBJ18_AbsAccelY";
CM_ SG_ 1521 RSDS_RR_PER_OBJ18_AbsAccelXStd "RSDS_RR_PER_OBJ18_AbsAccelXStd";
CM_ SG_ 1521 RSDS_RR_PER_OBJ18_AbsAccelX "RSDS_RR_PER_OBJ18_AbsAccelX";
CM_ SG_ 1520 RSDS_RR_PER_OBJ17_YawRate "RSDS_RR_PER_OBJ17_YawRate";
CM_ SG_ 1520 RSDS_RR_PER_OBJ17_Width "RSDS_RR_PER_OBJ17_Width";
CM_ SG_ 1520 RSDS_RR_PER_OBJ17_ValidFlag "RSDS_RR_PER_OBJ17_ValidFlag";
CM_ SG_ 1520 RSDS_RR_PER_OBJ17_ObstProbabilit "RSDS_RR_PER_OBJ17_ObstProbability";
CM_ SG_ 1520 RSDS_RR_PER_OBJ17_MotionType "RSDS_RR_PER_OBJ17_MotionType";
CM_ SG_ 1520 RSDS_RR_PER_OBJ17_MeasState "RSDS_RR_PER_OBJ17_MeasState";
CM_ SG_ 1520 RSDS_RR_PER_OBJ17_LifeCycle "RSDS_RR_PER_OBJ17_LifeCycle";
CM_ SG_ 1520 RSDS_RR_PER_OBJ17_Length "RSDS_RR_PER_OBJ17_Length";
CM_ SG_ 1520 RSDS_RR_PER_OBJ17_ID "RSDS_RR_PER_OBJ17_ID";
CM_ SG_ 1520 RSDS_RR_PER_OBJ17_HeadingAng "RSDS_RR_PER_OBJ17_HeadingAng";
CM_ SG_ 1520 RSDS_RR_PER_OBJ17_ExistProb "RSDS_RR_PER_OBJ17_ExistProb";
CM_ SG_ 1520 RSDS_RR_PER_OBJ17_DistZStd "RSDS_RR_PER_OBJ17_DistZStd";
CM_ SG_ 1520 RSDS_RR_PER_OBJ17_DistZ "RSDS_RR_PER_OBJ17_DistZ";
CM_ SG_ 1520 RSDS_RR_PER_OBJ17_DistYStd "RSDS_RR_PER_OBJ17_DistYStd";
CM_ SG_ 1520 RSDS_RR_PER_OBJ17_DistY "RSDS_RR_PER_OBJ17_DistY";
CM_ SG_ 1520 RSDS_RR_PER_OBJ17_DistXStd "RSDS_RR_PER_OBJ17_DistXStd";
CM_ SG_ 1520 RSDS_RR_PER_OBJ17_DistX "RSDS_RR_PER_OBJ17_DistX";
CM_ SG_ 1520 RSDS_RR_PER_OBJ17_ClassTypeProb "RSDS_RR_PER_OBJ17_ClassTypeProb";
CM_ SG_ 1520 RSDS_RR_PER_OBJ17_ClassType "RSDS_RR_PER_OBJ17_ClassType";
CM_ SG_ 1520 RSDS_RR_PER_OBJ17_AbsVelYStd "RSDS_RR_PER_OBJ17_AbsVelYStd";
CM_ SG_ 1520 RSDS_RR_PER_OBJ17_AbsVelY "RSDS_RR_PER_OBJ17_AbsVelY";
CM_ SG_ 1520 RSDS_RR_PER_OBJ17_AbsVelXStd "RSDS_RR_PER_OBJ17_AbsVelXStd";
CM_ SG_ 1520 RSDS_RR_PER_OBJ17_AbsVelX "RSDS_RR_PER_OBJ17_AbsVelX";
CM_ SG_ 1520 RSDS_RR_PER_OBJ17_AbsAccelYStd "RSDS_RR_PER_OBJ17_AbsAccelYStd";
CM_ SG_ 1520 RSDS_RR_PER_OBJ17_AbsAccelY "RSDS_RR_PER_OBJ17_AbsAccelY";
CM_ SG_ 1520 RSDS_RR_PER_OBJ17_AbsAccelXStd "RSDS_RR_PER_OBJ17_AbsAccelXStd";
CM_ SG_ 1520 RSDS_RR_PER_OBJ17_AbsAccelX "RSDS_RR_PER_OBJ17_AbsAccelX";
CM_ SG_ 1519 RSDS_RR_PER_OBJ16_YawRate "RSDS_RR_PER_OBJ16_YawRate";
CM_ SG_ 1519 RSDS_RR_PER_OBJ16_Width "RSDS_RR_PER_OBJ16_Width";
CM_ SG_ 1519 RSDS_RR_PER_OBJ16_ValidFlag "RSDS_RR_PER_OBJ16_ValidFlag";
CM_ SG_ 1519 RSDS_RR_PER_OBJ16_ObstProbabilit "RSDS_RR_PER_OBJ16_ObstProbability";
CM_ SG_ 1519 RSDS_RR_PER_OBJ16_MotionType "RSDS_RR_PER_OBJ16_MotionType";
CM_ SG_ 1519 RSDS_RR_PER_OBJ16_MeasState "RSDS_RR_PER_OBJ16_MeasState";
CM_ SG_ 1519 RSDS_RR_PER_OBJ16_LifeCycle "RSDS_RR_PER_OBJ16_LifeCycle";
CM_ SG_ 1519 RSDS_RR_PER_OBJ16_Length "RSDS_RR_PER_OBJ16_Length";
CM_ SG_ 1519 RSDS_RR_PER_OBJ16_ID "RSDS_RR_PER_OBJ16_ID";
CM_ SG_ 1519 RSDS_RR_PER_OBJ16_HeadingAng "RSDS_RR_PER_OBJ16_HeadingAng";
CM_ SG_ 1519 RSDS_RR_PER_OBJ16_ExistProb "RSDS_RR_PER_OBJ16_ExistProb";
CM_ SG_ 1519 RSDS_RR_PER_OBJ16_DistZStd "RSDS_RR_PER_OBJ16_DistZStd";
CM_ SG_ 1519 RSDS_RR_PER_OBJ16_DistZ "RSDS_RR_PER_OBJ16_DistZ";
CM_ SG_ 1519 RSDS_RR_PER_OBJ16_DistYStd "RSDS_RR_PER_OBJ16_DistYStd";
CM_ SG_ 1519 RSDS_RR_PER_OBJ16_DistY "RSDS_RR_PER_OBJ16_DistY";
CM_ SG_ 1519 RSDS_RR_PER_OBJ16_DistXStd "RSDS_RR_PER_OBJ16_DistXStd";
CM_ SG_ 1519 RSDS_RR_PER_OBJ16_DistX "RSDS_RR_PER_OBJ16_DistX";
CM_ SG_ 1519 RSDS_RR_PER_OBJ16_ClassTypeProb "RSDS_RR_PER_OBJ16_ClassTypeProb";
CM_ SG_ 1519 RSDS_RR_PER_OBJ16_ClassType "RSDS_RR_PER_OBJ16_ClassType";
CM_ SG_ 1519 RSDS_RR_PER_OBJ16_AbsVelYStd "RSDS_RR_PER_OBJ16_AbsVelYStd";
CM_ SG_ 1519 RSDS_RR_PER_OBJ16_AbsVelY "RSDS_RR_PER_OBJ16_AbsVelY";
CM_ SG_ 1519 RSDS_RR_PER_OBJ16_AbsVelXStd "RSDS_RR_PER_OBJ16_AbsVelXStd";
CM_ SG_ 1519 RSDS_RR_PER_OBJ16_AbsVelX "RSDS_RR_PER_OBJ16_AbsVelX";
CM_ SG_ 1519 RSDS_RR_PER_OBJ16_AbsAccelYStd "RSDS_RR_PER_OBJ16_AbsAccelYStd";
CM_ SG_ 1519 RSDS_RR_PER_OBJ16_AbsAccelY "RSDS_RR_PER_OBJ16_AbsAccelY";
CM_ SG_ 1519 RSDS_RR_PER_OBJ16_AbsAccelXStd "RSDS_RR_PER_OBJ16_AbsAccelXStd";
CM_ SG_ 1519 RSDS_RR_PER_OBJ16_AbsAccelX "RSDS_RR_PER_OBJ16_AbsAccelX";
CM_ SG_ 1518 RSDS_RR_PER_OBJ15_YawRate "RSDS_RR_PER_OBJ15_YawRate";
CM_ SG_ 1518 RSDS_RR_PER_OBJ15_Width "RSDS_RR_PER_OBJ15_Width";
CM_ SG_ 1518 RSDS_RR_PER_OBJ15_ValidFlag "RSDS_RR_PER_OBJ15_ValidFlag";
CM_ SG_ 1518 RSDS_RR_PER_OBJ15_ObstProbabilit "RSDS_RR_PER_OBJ15_ObstProbability";
CM_ SG_ 1518 RSDS_RR_PER_OBJ15_MotionType "RSDS_RR_PER_OBJ15_MotionType";
CM_ SG_ 1518 RSDS_RR_PER_OBJ15_MeasState "RSDS_RR_PER_OBJ15_MeasState";
CM_ SG_ 1518 RSDS_RR_PER_OBJ15_LifeCycle "RSDS_RR_PER_OBJ15_LifeCycle";
CM_ SG_ 1518 RSDS_RR_PER_OBJ15_Length "RSDS_RR_PER_OBJ15_Length";
CM_ SG_ 1518 RSDS_RR_PER_OBJ15_ID "RSDS_RR_PER_OBJ15_ID";
CM_ SG_ 1518 RSDS_RR_PER_OBJ15_HeadingAng "RSDS_RR_PER_OBJ15_HeadingAng";
CM_ SG_ 1518 RSDS_RR_PER_OBJ15_ExistProb "RSDS_RR_PER_OBJ15_ExistProb";
CM_ SG_ 1518 RSDS_RR_PER_OBJ15_DistZStd "RSDS_RR_PER_OBJ15_DistZStd";
CM_ SG_ 1518 RSDS_RR_PER_OBJ15_DistZ "RSDS_RR_PER_OBJ15_DistZ";
CM_ SG_ 1518 RSDS_RR_PER_OBJ15_DistYStd "RSDS_RR_PER_OBJ15_DistYStd";
CM_ SG_ 1518 RSDS_RR_PER_OBJ15_DistY "RSDS_RR_PER_OBJ15_DistY";
CM_ SG_ 1518 RSDS_RR_PER_OBJ15_DistXStd "RSDS_RR_PER_OBJ15_DistXStd";
CM_ SG_ 1518 RSDS_RR_PER_OBJ15_DistX "RSDS_RR_PER_OBJ15_DistX";
CM_ SG_ 1518 RSDS_RR_PER_OBJ15_ClassTypeProb "RSDS_RR_PER_OBJ15_ClassTypeProb";
CM_ SG_ 1518 RSDS_RR_PER_OBJ15_ClassType "RSDS_RR_PER_OBJ15_ClassType";
CM_ SG_ 1518 RSDS_RR_PER_OBJ15_AbsVelYStd "RSDS_RR_PER_OBJ15_AbsVelYStd";
CM_ SG_ 1518 RSDS_RR_PER_OBJ15_AbsVelY "RSDS_RR_PER_OBJ15_AbsVelY";
CM_ SG_ 1518 RSDS_RR_PER_OBJ15_AbsVelXStd "RSDS_RR_PER_OBJ15_AbsVelXStd";
CM_ SG_ 1518 RSDS_RR_PER_OBJ15_AbsVelX "RSDS_RR_PER_OBJ15_AbsVelX";
CM_ SG_ 1518 RSDS_RR_PER_OBJ15_AbsAccelYStd "RSDS_RR_PER_OBJ15_AbsAccelYStd";
CM_ SG_ 1518 RSDS_RR_PER_OBJ15_AbsAccelY "RSDS_RR_PER_OBJ15_AbsAccelY";
CM_ SG_ 1518 RSDS_RR_PER_OBJ15_AbsAccelXStd "RSDS_RR_PER_OBJ15_AbsAccelXStd";
CM_ SG_ 1518 RSDS_RR_PER_OBJ15_AbsAccelX "RSDS_RR_PER_OBJ15_AbsAccelX";
CM_ SG_ 1517 RSDS_RR_PER_OBJ14_YawRate "RSDS_RR_PER_OBJ14_YawRate";
CM_ SG_ 1517 RSDS_RR_PER_OBJ14_Width "RSDS_RR_PER_OBJ14_Width";
CM_ SG_ 1517 RSDS_RR_PER_OBJ14_ValidFlag "RSDS_RR_PER_OBJ14_ValidFlag";
CM_ SG_ 1517 RSDS_RR_PER_OBJ14_ObstProbabilit "RSDS_RR_PER_OBJ14_ObstProbability";
CM_ SG_ 1517 RSDS_RR_PER_OBJ14_MotionType "RSDS_RR_PER_OBJ14_MotionType";
CM_ SG_ 1517 RSDS_RR_PER_OBJ14_MeasState "RSDS_RR_PER_OBJ14_MeasState";
CM_ SG_ 1517 RSDS_RR_PER_OBJ14_LifeCycle "RSDS_RR_PER_OBJ14_LifeCycle";
CM_ SG_ 1517 RSDS_RR_PER_OBJ14_Length "RSDS_RR_PER_OBJ14_Length";
CM_ SG_ 1517 RSDS_RR_PER_OBJ14_ID "RSDS_RR_PER_OBJ14_ID";
CM_ SG_ 1517 RSDS_RR_PER_OBJ14_HeadingAng "RSDS_RR_PER_OBJ14_HeadingAng";
CM_ SG_ 1517 RSDS_RR_PER_OBJ14_ExistProb "RSDS_RR_PER_OBJ14_ExistProb";
CM_ SG_ 1517 RSDS_RR_PER_OBJ14_DistZStd "RSDS_RR_PER_OBJ14_DistZStd";
CM_ SG_ 1517 RSDS_RR_PER_OBJ14_DistZ "RSDS_RR_PER_OBJ14_DistZ";
CM_ SG_ 1517 RSDS_RR_PER_OBJ14_DistYStd "RSDS_RR_PER_OBJ14_DistYStd";
CM_ SG_ 1517 RSDS_RR_PER_OBJ14_DistY "RSDS_RR_PER_OBJ14_DistY";
CM_ SG_ 1517 RSDS_RR_PER_OBJ14_DistXStd "RSDS_RR_PER_OBJ14_DistXStd";
CM_ SG_ 1517 RSDS_RR_PER_OBJ14_DistX "RSDS_RR_PER_OBJ14_DistX";
CM_ SG_ 1517 RSDS_RR_PER_OBJ14_ClassTypeProb "RSDS_RR_PER_OBJ14_ClassTypeProb";
CM_ SG_ 1517 RSDS_RR_PER_OBJ14_ClassType "RSDS_RR_PER_OBJ14_ClassType";
CM_ SG_ 1517 RSDS_RR_PER_OBJ14_AbsVelYStd "RSDS_RR_PER_OBJ14_AbsVelYStd";
CM_ SG_ 1517 RSDS_RR_PER_OBJ14_AbsVelY "RSDS_RR_PER_OBJ14_AbsVelY";
CM_ SG_ 1517 RSDS_RR_PER_OBJ14_AbsVelXStd "RSDS_RR_PER_OBJ14_AbsVelXStd";
CM_ SG_ 1517 RSDS_RR_PER_OBJ14_AbsVelX "RSDS_RR_PER_OBJ14_AbsVelX";
CM_ SG_ 1517 RSDS_RR_PER_OBJ14_AbsAccelYStd "RSDS_RR_PER_OBJ14_AbsAccelYStd";
CM_ SG_ 1517 RSDS_RR_PER_OBJ14_AbsAccelY "RSDS_RR_PER_OBJ14_AbsAccelY";
CM_ SG_ 1517 RSDS_RR_PER_OBJ14_AbsAccelXStd "RSDS_RR_PER_OBJ14_AbsAccelXStd";
CM_ SG_ 1517 RSDS_RR_PER_OBJ14_AbsAccelX "RSDS_RR_PER_OBJ14_AbsAccelX";
CM_ SG_ 1516 RSDS_RR_PER_OBJ13_YawRate "RSDS_RR_PER_OBJ13_YawRate";
CM_ SG_ 1516 RSDS_RR_PER_OBJ13_Width "RSDS_RR_PER_OBJ13_Width";
CM_ SG_ 1516 RSDS_RR_PER_OBJ13_ValidFlag "RSDS_RR_PER_OBJ13_ValidFlag";
CM_ SG_ 1516 RSDS_RR_PER_OBJ13_ObstProbabilit "RSDS_RR_PER_OBJ13_ObstProbability";
CM_ SG_ 1516 RSDS_RR_PER_OBJ13_MotionType "RSDS_RR_PER_OBJ13_MotionType";
CM_ SG_ 1516 RSDS_RR_PER_OBJ13_MeasState "RSDS_RR_PER_OBJ13_MeasState";
CM_ SG_ 1516 RSDS_RR_PER_OBJ13_LifeCycle "RSDS_RR_PER_OBJ13_LifeCycle";
CM_ SG_ 1516 RSDS_RR_PER_OBJ13_Length "RSDS_RR_PER_OBJ13_Length";
CM_ SG_ 1516 RSDS_RR_PER_OBJ13_ID "RSDS_RR_PER_OBJ13_ID";
CM_ SG_ 1516 RSDS_RR_PER_OBJ13_HeadingAng "RSDS_RR_PER_OBJ13_HeadingAng";
CM_ SG_ 1516 RSDS_RR_PER_OBJ13_ExistProb "RSDS_RR_PER_OBJ13_ExistProb";
CM_ SG_ 1516 RSDS_RR_PER_OBJ13_DistZStd "RSDS_RR_PER_OBJ13_DistZStd";
CM_ SG_ 1516 RSDS_RR_PER_OBJ13_DistZ "RSDS_RR_PER_OBJ13_DistZ";
CM_ SG_ 1516 RSDS_RR_PER_OBJ13_DistYStd "RSDS_RR_PER_OBJ13_DistYStd";
CM_ SG_ 1516 RSDS_RR_PER_OBJ13_DistY "RSDS_RR_PER_OBJ13_DistY";
CM_ SG_ 1516 RSDS_RR_PER_OBJ13_DistXStd "RSDS_RR_PER_OBJ13_DistXStd";
CM_ SG_ 1516 RSDS_RR_PER_OBJ13_DistX "RSDS_RR_PER_OBJ13_DistX";
CM_ SG_ 1516 RSDS_RR_PER_OBJ13_ClassTypeProb "RSDS_RR_PER_OBJ13_ClassTypeProb";
CM_ SG_ 1516 RSDS_RR_PER_OBJ13_ClassType "RSDS_RR_PER_OBJ13_ClassType";
CM_ SG_ 1516 RSDS_RR_PER_OBJ13_AbsVelYStd "RSDS_RR_PER_OBJ13_AbsVelYStd";
CM_ SG_ 1516 RSDS_RR_PER_OBJ13_AbsVelY "RSDS_RR_PER_OBJ13_AbsVelY";
CM_ SG_ 1516 RSDS_RR_PER_OBJ13_AbsVelXStd "RSDS_RR_PER_OBJ13_AbsVelXStd";
CM_ SG_ 1516 RSDS_RR_PER_OBJ13_AbsVelX "RSDS_RR_PER_OBJ13_AbsVelX";
CM_ SG_ 1516 RSDS_RR_PER_OBJ13_AbsAccelYStd "RSDS_RR_PER_OBJ13_AbsAccelYStd";
CM_ SG_ 1516 RSDS_RR_PER_OBJ13_AbsAccelY "RSDS_RR_PER_OBJ13_AbsAccelY";
CM_ SG_ 1516 RSDS_RR_PER_OBJ13_AbsAccelXStd "RSDS_RR_PER_OBJ13_AbsAccelXStd";
CM_ SG_ 1516 RSDS_RR_PER_OBJ13_AbsAccelX "RSDS_RR_PER_OBJ13_AbsAccelX";
CM_ SG_ 1515 RSDS_RR_PER_OBJ12_YawRate "RSDS_RR_PER_OBJ12_YawRate";
CM_ SG_ 1515 RSDS_RR_PER_OBJ12_Width "RSDS_RR_PER_OBJ12_Width";
CM_ SG_ 1515 RSDS_RR_PER_OBJ12_ValidFlag "RSDS_RR_PER_OBJ12_ValidFlag";
CM_ SG_ 1515 RSDS_RR_PER_OBJ12_ObstProbabilit "RSDS_RR_PER_OBJ12_ObstProbability";
CM_ SG_ 1515 RSDS_RR_PER_OBJ12_MotionType "RSDS_RR_PER_OBJ12_MotionType";
CM_ SG_ 1515 RSDS_RR_PER_OBJ12_MeasState "RSDS_RR_PER_OBJ12_MeasState";
CM_ SG_ 1515 RSDS_RR_PER_OBJ12_LifeCycle "RSDS_RR_PER_OBJ12_LifeCycle";
CM_ SG_ 1515 RSDS_RR_PER_OBJ12_Length "RSDS_RR_PER_OBJ12_Length";
CM_ SG_ 1515 RSDS_RR_PER_OBJ12_ID "RSDS_RR_PER_OBJ12_ID";
CM_ SG_ 1515 RSDS_RR_PER_OBJ12_HeadingAng "RSDS_RR_PER_OBJ12_HeadingAng";
CM_ SG_ 1515 RSDS_RR_PER_OBJ12_ExistProb "RSDS_RR_PER_OBJ12_ExistProb";
CM_ SG_ 1515 RSDS_RR_PER_OBJ12_DistZStd "RSDS_RR_PER_OBJ12_DistZStd";
CM_ SG_ 1515 RSDS_RR_PER_OBJ12_DistZ "RSDS_RR_PER_OBJ12_DistZ";
CM_ SG_ 1515 RSDS_RR_PER_OBJ12_DistYStd "RSDS_RR_PER_OBJ12_DistYStd";
CM_ SG_ 1515 RSDS_RR_PER_OBJ12_DistY "RSDS_RR_PER_OBJ12_DistY";
CM_ SG_ 1515 RSDS_RR_PER_OBJ12_DistXStd "RSDS_RR_PER_OBJ12_DistXStd";
CM_ SG_ 1515 RSDS_RR_PER_OBJ12_DistX "RSDS_RR_PER_OBJ12_DistX";
CM_ SG_ 1515 RSDS_RR_PER_OBJ12_ClassTypeProb "RSDS_RR_PER_OBJ12_ClassTypeProb";
CM_ SG_ 1515 RSDS_RR_PER_OBJ12_ClassType "RSDS_RR_PER_OBJ12_ClassType";
CM_ SG_ 1515 RSDS_RR_PER_OBJ12_AbsVelYStd "RSDS_RR_PER_OBJ12_AbsVelYStd";
CM_ SG_ 1515 RSDS_RR_PER_OBJ12_AbsVelY "RSDS_RR_PER_OBJ12_AbsVelY";
CM_ SG_ 1515 RSDS_RR_PER_OBJ12_AbsVelXStd "RSDS_RR_PER_OBJ12_AbsVelXStd";
CM_ SG_ 1515 RSDS_RR_PER_OBJ12_AbsVelX "RSDS_RR_PER_OBJ12_AbsVelX";
CM_ SG_ 1515 RSDS_RR_PER_OBJ12_AbsAccelYStd "RSDS_RR_PER_OBJ12_AbsAccelYStd";
CM_ SG_ 1515 RSDS_RR_PER_OBJ12_AbsAccelY "RSDS_RR_PER_OBJ12_AbsAccelY";
CM_ SG_ 1515 RSDS_RR_PER_OBJ12_AbsAccelXStd "RSDS_RR_PER_OBJ12_AbsAccelXStd";
CM_ SG_ 1515 RSDS_RR_PER_OBJ12_AbsAccelX "RSDS_RR_PER_OBJ12_AbsAccelX";
CM_ SG_ 1514 RSDS_RR_PER_OBJ11_YawRate "RSDS_RR_PER_OBJ11_YawRate";
CM_ SG_ 1514 RSDS_RR_PER_OBJ11_Width "RSDS_RR_PER_OBJ11_Width";
CM_ SG_ 1514 RSDS_RR_PER_OBJ11_ValidFlag "RSDS_RR_PER_OBJ11_ValidFlag";
CM_ SG_ 1514 RSDS_RR_PER_OBJ11_ObstProbabilit "RSDS_RR_PER_OBJ11_ObstProbability";
CM_ SG_ 1514 RSDS_RR_PER_OBJ11_MotionType "RSDS_RR_PER_OBJ11_MotionType";
CM_ SG_ 1514 RSDS_RR_PER_OBJ11_MeasState "RSDS_RR_PER_OBJ11_MeasState";
CM_ SG_ 1514 RSDS_RR_PER_OBJ11_LifeCycle "RSDS_RR_PER_OBJ11_LifeCycle";
CM_ SG_ 1514 RSDS_RR_PER_OBJ11_Length "RSDS_RR_PER_OBJ11_Length";
CM_ SG_ 1514 RSDS_RR_PER_OBJ11_ID "RSDS_RR_PER_OBJ11_ID";
CM_ SG_ 1514 RSDS_RR_PER_OBJ11_HeadingAng "RSDS_RR_PER_OBJ11_HeadingAng";
CM_ SG_ 1514 RSDS_RR_PER_OBJ11_ExistProb "RSDS_RR_PER_OBJ11_ExistProb";
CM_ SG_ 1514 RSDS_RR_PER_OBJ11_DistZStd "RSDS_RR_PER_OBJ11_DistZStd";
CM_ SG_ 1514 RSDS_RR_PER_OBJ11_DistZ "RSDS_RR_PER_OBJ11_DistZ";
CM_ SG_ 1514 RSDS_RR_PER_OBJ11_DistYStd "RSDS_RR_PER_OBJ11_DistYStd";
CM_ SG_ 1514 RSDS_RR_PER_OBJ11_DistY "RSDS_RR_PER_OBJ11_DistY";
CM_ SG_ 1514 RSDS_RR_PER_OBJ11_DistXStd "RSDS_RR_PER_OBJ11_DistXStd";
CM_ SG_ 1514 RSDS_RR_PER_OBJ11_DistX "RSDS_RR_PER_OBJ11_DistX";
CM_ SG_ 1514 RSDS_RR_PER_OBJ11_ClassTypeProb "RSDS_RR_PER_OBJ11_ClassTypeProb";
CM_ SG_ 1514 RSDS_RR_PER_OBJ11_ClassType "RSDS_RR_PER_OBJ11_ClassType";
CM_ SG_ 1514 RSDS_RR_PER_OBJ11_AbsVelYStd "RSDS_RR_PER_OBJ11_AbsVelYStd";
CM_ SG_ 1514 RSDS_RR_PER_OBJ11_AbsVelY "RSDS_RR_PER_OBJ11_AbsVelY";
CM_ SG_ 1514 RSDS_RR_PER_OBJ11_AbsVelXStd "RSDS_RR_PER_OBJ11_AbsVelXStd";
CM_ SG_ 1514 RSDS_RR_PER_OBJ11_AbsVelX "RSDS_RR_PER_OBJ11_AbsVelX";
CM_ SG_ 1514 RSDS_RR_PER_OBJ11_AbsAccelYStd "RSDS_RR_PER_OBJ11_AbsAccelYStd";
CM_ SG_ 1514 RSDS_RR_PER_OBJ11_AbsAccelY "RSDS_RR_PER_OBJ11_AbsAccelY";
CM_ SG_ 1514 RSDS_RR_PER_OBJ11_AbsAccelXStd "RSDS_RR_PER_OBJ11_AbsAccelXStd";
CM_ SG_ 1514 RSDS_RR_PER_OBJ11_AbsAccelX "RSDS_RR_PER_OBJ11_AbsAccelX";
CM_ SG_ 1513 RSDS_RR_PER_OBJ10_YawRate "RSDS_RR_PER_OBJ10_YawRate";
CM_ SG_ 1513 RSDS_RR_PER_OBJ10_Width "RSDS_RR_PER_OBJ10_Width";
CM_ SG_ 1513 RSDS_RR_PER_OBJ10_ValidFlag "RSDS_RR_PER_OBJ10_ValidFlag";
CM_ SG_ 1513 RSDS_RR_PER_OBJ10_ObstProbabilit "RSDS_RR_PER_OBJ10_ObstProbability";
CM_ SG_ 1513 RSDS_RR_PER_OBJ10_MotionType "RSDS_RR_PER_OBJ10_MotionType";
CM_ SG_ 1513 RSDS_RR_PER_OBJ10_MeasState "RSDS_RR_PER_OBJ10_MeasState";
CM_ SG_ 1513 RSDS_RR_PER_OBJ10_LifeCycle "RSDS_RR_PER_OBJ10_LifeCycle";
CM_ SG_ 1513 RSDS_RR_PER_OBJ10_Length "RSDS_RR_PER_OBJ10_Length";
CM_ SG_ 1513 RSDS_RR_PER_OBJ10_ID "RSDS_RR_PER_OBJ10_ID";
CM_ SG_ 1513 RSDS_RR_PER_OBJ10_HeadingAng "RSDS_RR_PER_OBJ10_HeadingAng";
CM_ SG_ 1513 RSDS_RR_PER_OBJ10_ExistProb "RSDS_RR_PER_OBJ10_ExistProb";
CM_ SG_ 1513 RSDS_RR_PER_OBJ10_DistZStd "RSDS_RR_PER_OBJ10_DistZStd";
CM_ SG_ 1513 RSDS_RR_PER_OBJ10_DistZ "RSDS_RR_PER_OBJ10_DistZ";
CM_ SG_ 1513 RSDS_RR_PER_OBJ10_DistYStd "RSDS_RR_PER_OBJ10_DistYStd";
CM_ SG_ 1513 RSDS_RR_PER_OBJ10_DistY "RSDS_RR_PER_OBJ10_DistY";
CM_ SG_ 1513 RSDS_RR_PER_OBJ10_DistXStd "RSDS_RR_PER_OBJ10_DistXStd";
CM_ SG_ 1513 RSDS_RR_PER_OBJ10_DistX "RSDS_RR_PER_OBJ10_DistX";
CM_ SG_ 1513 RSDS_RR_PER_OBJ10_ClassTypeProb "RSDS_RR_PER_OBJ10_ClassTypeProb";
CM_ SG_ 1513 RSDS_RR_PER_OBJ10_ClassType "RSDS_RR_PER_OBJ10_ClassType";
CM_ SG_ 1513 RSDS_RR_PER_OBJ10_AbsVelYStd "RSDS_RR_PER_OBJ10_AbsVelYStd";
CM_ SG_ 1513 RSDS_RR_PER_OBJ10_AbsVelY "RSDS_RR_PER_OBJ10_AbsVelY";
CM_ SG_ 1513 RSDS_RR_PER_OBJ10_AbsVelXStd "RSDS_RR_PER_OBJ10_AbsVelXStd";
CM_ SG_ 1513 RSDS_RR_PER_OBJ10_AbsVelX "RSDS_RR_PER_OBJ10_AbsVelX";
CM_ SG_ 1513 RSDS_RR_PER_OBJ10_AbsAccelYStd "RSDS_RR_PER_OBJ10_AbsAccelYStd";
CM_ SG_ 1513 RSDS_RR_PER_OBJ10_AbsAccelY "RSDS_RR_PER_OBJ10_AbsAccelY";
CM_ SG_ 1513 RSDS_RR_PER_OBJ10_AbsAccelXStd "RSDS_RR_PER_OBJ10_AbsAccelXStd";
CM_ SG_ 1513 RSDS_RR_PER_OBJ10_AbsAccelX "RSDS_RR_PER_OBJ10_AbsAccelX";
CM_ SG_ 1512 RSDS_RR_PER_OBJ9_YawRate "RSDS_RR_PER_OBJ9_YawRate";
CM_ SG_ 1512 RSDS_RR_PER_OBJ9_Width "RSDS_RR_PER_OBJ9_Width";
CM_ SG_ 1512 RSDS_RR_PER_OBJ9_ValidFlag "RSDS_RR_PER_OBJ9_ValidFlag";
CM_ SG_ 1512 RSDS_RR_PER_OBJ9_ObstProbability "RSDS_RR_PER_OBJ9_ObstProbability";
CM_ SG_ 1512 RSDS_RR_PER_OBJ9_MotionType "RSDS_RR_PER_OBJ9_MotionType";
CM_ SG_ 1512 RSDS_RR_PER_OBJ9_MeasState "RSDS_RR_PER_OBJ9_MeasState";
CM_ SG_ 1512 RSDS_RR_PER_OBJ9_LifeCycle "RSDS_RR_PER_OBJ9_LifeCycle";
CM_ SG_ 1512 RSDS_RR_PER_OBJ9_Length "RSDS_RR_PER_OBJ9_Length";
CM_ SG_ 1512 RSDS_RR_PER_OBJ9_ID "RSDS_RR_PER_OBJ9_ID";
CM_ SG_ 1512 RSDS_RR_PER_OBJ9_HeadingAng "RSDS_RR_PER_OBJ9_HeadingAng";
CM_ SG_ 1512 RSDS_RR_PER_OBJ9_ExistProb "RSDS_RR_PER_OBJ9_ExistProb";
CM_ SG_ 1512 RSDS_RR_PER_OBJ9_DistZStd "RSDS_RR_PER_OBJ9_DistZStd";
CM_ SG_ 1512 RSDS_RR_PER_OBJ9_DistZ "RSDS_RR_PER_OBJ9_DistZ";
CM_ SG_ 1512 RSDS_RR_PER_OBJ9_DistYStd "RSDS_RR_PER_OBJ9_DistYStd";
CM_ SG_ 1512 RSDS_RR_PER_OBJ9_DistY "RSDS_RR_PER_OBJ9_DistY";
CM_ SG_ 1512 RSDS_RR_PER_OBJ9_DistXStd "RSDS_RR_PER_OBJ9_DistXStd";
CM_ SG_ 1512 RSDS_RR_PER_OBJ9_DistX "RSDS_RR_PER_OBJ9_DistX";
CM_ SG_ 1512 RSDS_RR_PER_OBJ9_ClassTypeProb "RSDS_RR_PER_OBJ9_ClassTypeProb";
CM_ SG_ 1512 RSDS_RR_PER_OBJ9_ClassType "RSDS_RR_PER_OBJ9_ClassType";
CM_ SG_ 1512 RSDS_RR_PER_OBJ9_AbsVelYStd "RSDS_RR_PER_OBJ9_AbsVelYStd";
CM_ SG_ 1512 RSDS_RR_PER_OBJ9_AbsVelY "RSDS_RR_PER_OBJ9_AbsVelY";
CM_ SG_ 1512 RSDS_RR_PER_OBJ9_AbsVelXStd "RSDS_RR_PER_OBJ9_AbsVelXStd";
CM_ SG_ 1512 RSDS_RR_PER_OBJ9_AbsVelX "RSDS_RR_PER_OBJ9_AbsVelX";
CM_ SG_ 1512 RSDS_RR_PER_OBJ9_AbsAccelYStd "RSDS_RR_PER_OBJ9_AbsAccelYStd";
CM_ SG_ 1512 RSDS_RR_PER_OBJ9_AbsAccelY "RSDS_RR_PER_OBJ9_AbsAccelY";
CM_ SG_ 1512 RSDS_RR_PER_OBJ9_AbsAccelXStd "RSDS_RR_PER_OBJ9_AbsAccelXStd";
CM_ SG_ 1512 RSDS_RR_PER_OBJ9_AbsAccelX "RSDS_RR_PER_OBJ9_AbsAccelX";
CM_ SG_ 1511 RSDS_RR_PER_OBJ8_YawRate "RSDS_RR_PER_OBJ8_YawRate";
CM_ SG_ 1511 RSDS_RR_PER_OBJ8_Width "RSDS_RR_PER_OBJ8_Width";
CM_ SG_ 1511 RSDS_RR_PER_OBJ8_ValidFlag "RSDS_RR_PER_OBJ8_ValidFlag";
CM_ SG_ 1511 RSDS_RR_PER_OBJ8_ObstProbability "RSDS_RR_PER_OBJ8_ObstProbability";
CM_ SG_ 1511 RSDS_RR_PER_OBJ8_MotionType "RSDS_RR_PER_OBJ8_MotionType";
CM_ SG_ 1511 RSDS_RR_PER_OBJ8_MeasState "RSDS_RR_PER_OBJ8_MeasState";
CM_ SG_ 1511 RSDS_RR_PER_OBJ8_LifeCycle "RSDS_RR_PER_OBJ8_LifeCycle";
CM_ SG_ 1511 RSDS_RR_PER_OBJ8_Length "RSDS_RR_PER_OBJ8_Length";
CM_ SG_ 1511 RSDS_RR_PER_OBJ8_ID "RSDS_RR_PER_OBJ8_ID";
CM_ SG_ 1511 RSDS_RR_PER_OBJ8_HeadingAng "RSDS_RR_PER_OBJ8_HeadingAng";
CM_ SG_ 1511 RSDS_RR_PER_OBJ8_ExistProb "RSDS_RR_PER_OBJ8_ExistProb";
CM_ SG_ 1511 RSDS_RR_PER_OBJ8_DistZStd "RSDS_RR_PER_OBJ8_DistZStd";
CM_ SG_ 1511 RSDS_RR_PER_OBJ8_DistZ "RSDS_RR_PER_OBJ8_DistZ";
CM_ SG_ 1511 RSDS_RR_PER_OBJ8_DistYStd "RSDS_RR_PER_OBJ8_DistYStd";
CM_ SG_ 1511 RSDS_RR_PER_OBJ8_DistY "RSDS_RR_PER_OBJ8_DistY";
CM_ SG_ 1511 RSDS_RR_PER_OBJ8_DistXStd "RSDS_RR_PER_OBJ8_DistXStd";
CM_ SG_ 1511 RSDS_RR_PER_OBJ8_DistX "RSDS_RR_PER_OBJ8_DistX";
CM_ SG_ 1511 RSDS_RR_PER_OBJ8_ClassTypeProb "RSDS_RR_PER_OBJ8_ClassTypeProb";
CM_ SG_ 1511 RSDS_RR_PER_OBJ8_ClassType "RSDS_RR_PER_OBJ8_ClassType";
CM_ SG_ 1511 RSDS_RR_PER_OBJ8_AbsVelYStd "RSDS_RR_PER_OBJ8_AbsVelYStd";
CM_ SG_ 1511 RSDS_RR_PER_OBJ8_AbsVelY "RSDS_RR_PER_OBJ8_AbsVelY";
CM_ SG_ 1511 RSDS_RR_PER_OBJ8_AbsVelXStd "RSDS_RR_PER_OBJ8_AbsVelXStd";
CM_ SG_ 1511 RSDS_RR_PER_OBJ8_AbsVelX "RSDS_RR_PER_OBJ8_AbsVelX";
CM_ SG_ 1511 RSDS_RR_PER_OBJ8_AbsAccelYStd "RSDS_RR_PER_OBJ8_AbsAccelYStd";
CM_ SG_ 1511 RSDS_RR_PER_OBJ8_AbsAccelY "RSDS_RR_PER_OBJ8_AbsAccelY";
CM_ SG_ 1511 RSDS_RR_PER_OBJ8_AbsAccelXStd "RSDS_RR_PER_OBJ8_AbsAccelXStd";
CM_ SG_ 1511 RSDS_RR_PER_OBJ8_AbsAccelX "RSDS_RR_PER_OBJ8_AbsAccelX";
CM_ SG_ 1510 RSDS_RR_PER_OBJ7_YawRate "RSDS_RR_PER_OBJ7_YawRate";
CM_ SG_ 1510 RSDS_RR_PER_OBJ7_Width "RSDS_RR_PER_OBJ7_Width";
CM_ SG_ 1510 RSDS_RR_PER_OBJ7_ValidFlag "RSDS_RR_PER_OBJ7_ValidFlag";
CM_ SG_ 1510 RSDS_RR_PER_OBJ7_ObstProbability "RSDS_RR_PER_OBJ7_ObstProbability";
CM_ SG_ 1510 RSDS_RR_PER_OBJ7_MotionType "RSDS_RR_PER_OBJ7_MotionType";
CM_ SG_ 1510 RSDS_RR_PER_OBJ7_MeasState "RSDS_RR_PER_OBJ7_MeasState";
CM_ SG_ 1510 RSDS_RR_PER_OBJ7_LifeCycle "RSDS_RR_PER_OBJ7_LifeCycle";
CM_ SG_ 1510 RSDS_RR_PER_OBJ7_Length "RSDS_RR_PER_OBJ7_Length";
CM_ SG_ 1510 RSDS_RR_PER_OBJ7_ID "RSDS_RR_PER_OBJ7_ID";
CM_ SG_ 1510 RSDS_RR_PER_OBJ7_HeadingAng "RSDS_RR_PER_OBJ7_HeadingAng";
CM_ SG_ 1510 RSDS_RR_PER_OBJ7_ExistProb "RSDS_RR_PER_OBJ7_ExistProb";
CM_ SG_ 1510 RSDS_RR_PER_OBJ7_DistZStd "RSDS_RR_PER_OBJ7_DistZStd";
CM_ SG_ 1510 RSDS_RR_PER_OBJ7_DistZ "RSDS_RR_PER_OBJ7_DistZ";
CM_ SG_ 1510 RSDS_RR_PER_OBJ7_DistYStd "RSDS_RR_PER_OBJ7_DistYStd";
CM_ SG_ 1510 RSDS_RR_PER_OBJ7_DistY "RSDS_RR_PER_OBJ7_DistY";
CM_ SG_ 1510 RSDS_RR_PER_OBJ7_DistXStd "RSDS_RR_PER_OBJ7_DistXStd";
CM_ SG_ 1510 RSDS_RR_PER_OBJ7_DistX "RSDS_RR_PER_OBJ7_DistX";
CM_ SG_ 1510 RSDS_RR_PER_OBJ7_ClassTypeProb "RSDS_RR_PER_OBJ7_ClassTypeProb";
CM_ SG_ 1510 RSDS_RR_PER_OBJ7_ClassType "RSDS_RR_PER_OBJ7_ClassType";
CM_ SG_ 1510 RSDS_RR_PER_OBJ7_AbsVelYStd "RSDS_RR_PER_OBJ7_AbsVelYStd";
CM_ SG_ 1510 RSDS_RR_PER_OBJ7_AbsVelY "RSDS_RR_PER_OBJ7_AbsVelY";
CM_ SG_ 1510 RSDS_RR_PER_OBJ7_AbsVelXStd "RSDS_RR_PER_OBJ7_AbsVelXStd";
CM_ SG_ 1510 RSDS_RR_PER_OBJ7_AbsVelX "RSDS_RR_PER_OBJ7_AbsVelX";
CM_ SG_ 1510 RSDS_RR_PER_OBJ7_AbsAccelYStd "RSDS_RR_PER_OBJ7_AbsAccelYStd";
CM_ SG_ 1510 RSDS_RR_PER_OBJ7_AbsAccelY "RSDS_RR_PER_OBJ7_AbsAccelY";
CM_ SG_ 1510 RSDS_RR_PER_OBJ7_AbsAccelXStd "RSDS_RR_PER_OBJ7_AbsAccelXStd";
CM_ SG_ 1510 RSDS_RR_PER_OBJ7_AbsAccelX "RSDS_RR_PER_OBJ7_AbsAccelX";
BA_DEF_ SG_  "GenSigStartValue" FLOAT -1.79769313486232E+019 1.84467440737096E+019;
BA_DEF_  "BaudRate" FLOAT 1000 1000000;
BA_DEF_ BO_  "CANFD_BRS" ENUM  "0","1";
BA_DEF_  "DBName" STRING ;
BA_DEF_  "BusType" STRING ;
BA_DEF_ BO_  "VFrameFormat" ENUM  "StandardCAN","ExtendedCAN","reserved","reserved","reserved","reserved","reserved","reserved","reserved","reserved","reserved","reserved","reserved","reserved","StandardCAN_FD","ExtendedCAN_FD";
BA_DEF_ SG_  "SystemSignalLongSymbol" STRING ;
BA_DEF_DEF_  "GenSigStartValue" 0;
BA_DEF_DEF_  "BaudRate" 2000;
BA_DEF_DEF_  "CANFD_BRS" "1";
BA_DEF_DEF_  "DBName" "";
BA_DEF_DEF_  "BusType" "";
BA_DEF_DEF_  "VFrameFormat" "StandardCAN_FD";
BA_DEF_DEF_  "SystemSignalLongSymbol" "";
BA_ "BusType" "CAN FD";
BA_ "DBName" "VCANFD";
BA_ "GenSigStartValue" SG_ 1408 RSDS_FL_PER_OBJ1_YawRate 1570;
BA_ "GenSigStartValue" SG_ 1408 RSDS_FL_PER_OBJ1_HeadingAng 1570;
BA_ "GenSigStartValue" SG_ 1408 RSDS_FL_PER_OBJ1_DistZ 512;
BA_ "GenSigStartValue" SG_ 1408 RSDS_FL_PER_OBJ1_DistY 2048;
BA_ "GenSigStartValue" SG_ 1408 RSDS_FL_PER_OBJ1_DistX 4096;
BA_ "GenSigStartValue" SG_ 1408 RSDS_FL_PER_OBJ1_AbsVelY 4102.5641025641;
BA_ "GenSigStartValue" SG_ 1408 RSDS_FL_PER_OBJ1_AbsVelX 4102.5641025641;
BA_ "GenSigStartValue" SG_ 1408 RSDS_FL_PER_OBJ1_AbsAccelY 512;
BA_ "GenSigStartValue" SG_ 1408 RSDS_FL_PER_OBJ1_AbsAccelX 512;
BA_ "GenSigStartValue" SG_ 1502 RSDS_RR_MountPosX 10000;
BA_ "GenSigStartValue" SG_ 1502 RSDS_RR_YawMountAngle 32000;
BA_ "GenSigStartValue" SG_ 1502 RSDS_RR_RollMountAngle 2000;
BA_ "GenSigStartValue" SG_ 1502 RSDS_RR_PitchMountAngle 2000;
BA_ "GenSigStartValue" SG_ 1502 RSDS_RR_MountPosY 2500;
BA_ "GenSigStartValue" SG_ 1502 RSDS_RR_CALIB_EleOffset 10000;
BA_ "GenSigStartValue" SG_ 1502 RSDS_RR_CALIB_AziOffset 10000;
BA_ "GenSigStartValue" SG_ 1470 RSDS_RL_MountPosX 10000;
BA_ "GenSigStartValue" SG_ 1470 RSDS_RL_YawMountAngle 32000;
BA_ "GenSigStartValue" SG_ 1470 RSDS_RL_RollMountAngle 2000;
BA_ "GenSigStartValue" SG_ 1470 RSDS_RL_PitchMountAngle 2000;
BA_ "GenSigStartValue" SG_ 1470 RSDS_RL_MountPosY 2500;
BA_ "GenSigStartValue" SG_ 1470 RSDS_RL_CALIB_EleOffset 10000;
BA_ "GenSigStartValue" SG_ 1470 RSDS_RL_CALIB_AziOffset 10000;
BA_ "GenSigStartValue" SG_ 1454 RSDS_FR_MountPosX 10000;
BA_ "GenSigStartValue" SG_ 1454 RSDS_FR_YawMountAngle 32000;
BA_ "GenSigStartValue" SG_ 1454 RSDS_FR_RollMountAngle 2000;
BA_ "GenSigStartValue" SG_ 1454 RSDS_FR_PitchMountAngle 2000;
BA_ "GenSigStartValue" SG_ 1454 RSDS_FR_MountPosY 2500;
BA_ "GenSigStartValue" SG_ 1454 RSDS_FR_CALIB_EleOffset 10000;
BA_ "GenSigStartValue" SG_ 1454 RSDS_FR_CALIB_AziOffset 10000;
BA_ "GenSigStartValue" SG_ 1486 RSDS_FL_MountPosX 10000;
BA_ "GenSigStartValue" SG_ 1486 RSDS_FL_YawMountAngle 32000;
BA_ "GenSigStartValue" SG_ 1486 RSDS_FL_RollMountAngle 2000;
BA_ "GenSigStartValue" SG_ 1486 RSDS_FL_PitchMountAngle 2000;
BA_ "GenSigStartValue" SG_ 1486 RSDS_FL_MountPosY 2500;
BA_ "GenSigStartValue" SG_ 1486 RSDS_FL_CALIB_EleOffset 10000;
BA_ "GenSigStartValue" SG_ 1486 RSDS_FL_CALIB_AziOffset 10000;
BA_ "GenSigStartValue" SG_ 1535 RSDS_RR_PER_OBJ32_YawRate 1570;
BA_ "SystemSignalLongSymbol" SG_ 1535 RSDS_RR_PER_OBJ32_ObstProbabilit "RSDS_RR_PER_OBJ32_ObstProbability";
BA_ "GenSigStartValue" SG_ 1535 RSDS_RR_PER_OBJ32_HeadingAng 1570;
BA_ "GenSigStartValue" SG_ 1535 RSDS_RR_PER_OBJ32_DistZ 512;
BA_ "GenSigStartValue" SG_ 1535 RSDS_RR_PER_OBJ32_DistY 2048;
BA_ "GenSigStartValue" SG_ 1535 RSDS_RR_PER_OBJ32_DistX 4096;
BA_ "GenSigStartValue" SG_ 1535 RSDS_RR_PER_OBJ32_AbsVelY 4102.5641025641;
BA_ "GenSigStartValue" SG_ 1535 RSDS_RR_PER_OBJ32_AbsVelX 4102.5641025641;
BA_ "GenSigStartValue" SG_ 1535 RSDS_RR_PER_OBJ32_AbsAccelY 512;
BA_ "GenSigStartValue" SG_ 1535 RSDS_RR_PER_OBJ32_AbsAccelX 512;
BA_ "GenSigStartValue" SG_ 1534 RSDS_RR_PER_OBJ31_YawRate 1570;
BA_ "SystemSignalLongSymbol" SG_ 1534 RSDS_RR_PER_OBJ31_ObstProbabilit "RSDS_RR_PER_OBJ31_ObstProbability";
BA_ "GenSigStartValue" SG_ 1534 RSDS_RR_PER_OBJ31_HeadingAng 1570;
BA_ "GenSigStartValue" SG_ 1534 RSDS_RR_PER_OBJ31_DistZ 512;
BA_ "GenSigStartValue" SG_ 1534 RSDS_RR_PER_OBJ31_DistY 2048;
BA_ "GenSigStartValue" SG_ 1534 RSDS_RR_PER_OBJ31_DistX 4096;
BA_ "GenSigStartValue" SG_ 1534 RSDS_RR_PER_OBJ31_AbsVelY 4102.5641025641;
BA_ "GenSigStartValue" SG_ 1534 RSDS_RR_PER_OBJ31_AbsVelX 4102.5641025641;
BA_ "GenSigStartValue" SG_ 1534 RSDS_RR_PER_OBJ31_AbsAccelY 512;
BA_ "GenSigStartValue" SG_ 1534 RSDS_RR_PER_OBJ31_AbsAccelX 512;
BA_ "GenSigStartValue" SG_ 1533 RSDS_RR_PER_OBJ30_YawRate 1570;
BA_ "SystemSignalLongSymbol" SG_ 1533 RSDS_RR_PER_OBJ30_ObstProbabilit "RSDS_RR_PER_OBJ30_ObstProbability";
BA_ "GenSigStartValue" SG_ 1533 RSDS_RR_PER_OBJ30_HeadingAng 1570;
BA_ "GenSigStartValue" SG_ 1533 RSDS_RR_PER_OBJ30_DistZ 512;
BA_ "GenSigStartValue" SG_ 1533 RSDS_RR_PER_OBJ30_DistY 2048;
BA_ "GenSigStartValue" SG_ 1533 RSDS_RR_PER_OBJ30_DistX 4096;
BA_ "GenSigStartValue" SG_ 1533 RSDS_RR_PER_OBJ30_AbsVelY 4102.5641025641;
BA_ "GenSigStartValue" SG_ 1533 RSDS_RR_PER_OBJ30_AbsVelX 4102.5641025641;
BA_ "GenSigStartValue" SG_ 1533 RSDS_RR_PER_OBJ30_AbsAccelY 512;
BA_ "GenSigStartValue" SG_ 1533 RSDS_RR_PER_OBJ30_AbsAccelX 512;
BA_ "GenSigStartValue" SG_ 1532 RSDS_RR_PER_OBJ29_YawRate 1570;
BA_ "SystemSignalLongSymbol" SG_ 1532 RSDS_RR_PER_OBJ29_ObstProbabilit "RSDS_RR_PER_OBJ29_ObstProbability";
BA_ "GenSigStartValue" SG_ 1532 RSDS_RR_PER_OBJ29_HeadingAng 1570;
BA_ "GenSigStartValue" SG_ 1532 RSDS_RR_PER_OBJ29_DistZ 512;
BA_ "GenSigStartValue" SG_ 1532 RSDS_RR_PER_OBJ29_DistY 2048;
BA_ "GenSigStartValue" SG_ 1532 RSDS_RR_PER_OBJ29_DistX 4096;
BA_ "GenSigStartValue" SG_ 1532 RSDS_RR_PER_OBJ29_AbsVelY 4102.5641025641;
BA_ "GenSigStartValue" SG_ 1532 RSDS_RR_PER_OBJ29_AbsVelX 4102.5641025641;
BA_ "GenSigStartValue" SG_ 1532 RSDS_RR_PER_OBJ29_AbsAccelY 512;
BA_ "GenSigStartValue" SG_ 1532 RSDS_RR_PER_OBJ29_AbsAccelX 512;
BA_ "GenSigStartValue" SG_ 1531 RSDS_RR_PER_OBJ28_YawRate 1570;
BA_ "SystemSignalLongSymbol" SG_ 1531 RSDS_RR_PER_OBJ28_ObstProbabilit "RSDS_RR_PER_OBJ28_ObstProbability";
BA_ "GenSigStartValue" SG_ 1531 RSDS_RR_PER_OBJ28_HeadingAng 1570;
BA_ "GenSigStartValue" SG_ 1531 RSDS_RR_PER_OBJ28_DistZ 512;
BA_ "GenSigStartValue" SG_ 1531 RSDS_RR_PER_OBJ28_DistY 2048;
BA_ "GenSigStartValue" SG_ 1531 RSDS_RR_PER_OBJ28_DistX 4096;
BA_ "GenSigStartValue" SG_ 1531 RSDS_RR_PER_OBJ28_AbsVelY 4102.5641025641;
BA_ "GenSigStartValue" SG_ 1531 RSDS_RR_PER_OBJ28_AbsVelX 4102.5641025641;
BA_ "GenSigStartValue" SG_ 1531 RSDS_RR_PER_OBJ28_AbsAccelY 512;
BA_ "GenSigStartValue" SG_ 1531 RSDS_RR_PER_OBJ28_AbsAccelX 512;
BA_ "GenSigStartValue" SG_ 1530 RSDS_RR_PER_OBJ27_YawRate 1570;
BA_ "SystemSignalLongSymbol" SG_ 1530 RSDS_RR_PER_OBJ27_ObstProbabilit "RSDS_RR_PER_OBJ27_ObstProbability";
BA_ "GenSigStartValue" SG_ 1530 RSDS_RR_PER_OBJ27_HeadingAng 1570;
BA_ "GenSigStartValue" SG_ 1530 RSDS_RR_PER_OBJ27_DistZ 512;
BA_ "GenSigStartValue" SG_ 1530 RSDS_RR_PER_OBJ27_DistY 2048;
BA_ "GenSigStartValue" SG_ 1530 RSDS_RR_PER_OBJ27_DistX 4096;
BA_ "GenSigStartValue" SG_ 1530 RSDS_RR_PER_OBJ27_AbsVelY 4102.5641025641;
BA_ "GenSigStartValue" SG_ 1530 RSDS_RR_PER_OBJ27_AbsVelX 4102.5641025641;
BA_ "GenSigStartValue" SG_ 1530 RSDS_RR_PER_OBJ27_AbsAccelY 512;
BA_ "GenSigStartValue" SG_ 1530 RSDS_RR_PER_OBJ27_AbsAccelX 512;
BA_ "GenSigStartValue" SG_ 1529 RSDS_RR_PER_OBJ26_YawRate 1570;
BA_ "SystemSignalLongSymbol" SG_ 1529 RSDS_RR_PER_OBJ26_ObstProbabilit "RSDS_RR_PER_OBJ26_ObstProbability";
BA_ "GenSigStartValue" SG_ 1529 RSDS_RR_PER_OBJ26_HeadingAng 1570;
BA_ "GenSigStartValue" SG_ 1529 RSDS_RR_PER_OBJ26_DistZ 512;
BA_ "GenSigStartValue" SG_ 1529 RSDS_RR_PER_OBJ26_DistY 2048;
BA_ "GenSigStartValue" SG_ 1529 RSDS_RR_PER_OBJ26_DistX 4096;
BA_ "GenSigStartValue" SG_ 1529 RSDS_RR_PER_OBJ26_AbsVelY 4102.5641025641;
BA_ "GenSigStartValue" SG_ 1529 RSDS_RR_PER_OBJ26_AbsVelX 4102.5641025641;
BA_ "GenSigStartValue" SG_ 1529 RSDS_RR_PER_OBJ26_AbsAccelY 512;
BA_ "GenSigStartValue" SG_ 1529 RSDS_RR_PER_OBJ26_AbsAccelX 512;
BA_ "GenSigStartValue" SG_ 1528 RSDS_RR_PER_OBJ25_YawRate 1570;
BA_ "SystemSignalLongSymbol" SG_ 1528 RSDS_RR_PER_OBJ25_ObstProbabilit "RSDS_RR_PER_OBJ25_ObstProbability";
BA_ "GenSigStartValue" SG_ 1528 RSDS_RR_PER_OBJ25_HeadingAng 1570;
BA_ "GenSigStartValue" SG_ 1528 RSDS_RR_PER_OBJ25_DistZ 512;
BA_ "GenSigStartValue" SG_ 1528 RSDS_RR_PER_OBJ25_DistY 2048;
BA_ "GenSigStartValue" SG_ 1528 RSDS_RR_PER_OBJ25_DistX 4096;
BA_ "GenSigStartValue" SG_ 1528 RSDS_RR_PER_OBJ25_AbsVelY 4102.5641025641;
BA_ "GenSigStartValue" SG_ 1528 RSDS_RR_PER_OBJ25_AbsVelX 4102.5641025641;
BA_ "GenSigStartValue" SG_ 1528 RSDS_RR_PER_OBJ25_AbsAccelY 512;
BA_ "GenSigStartValue" SG_ 1528 RSDS_RR_PER_OBJ25_AbsAccelX 512;
BA_ "GenSigStartValue" SG_ 1527 RSDS_RR_PER_OBJ24_YawRate 1570;
BA_ "SystemSignalLongSymbol" SG_ 1527 RSDS_RR_PER_OBJ24_ObstProbabilit "RSDS_RR_PER_OBJ24_ObstProbability";
BA_ "GenSigStartValue" SG_ 1527 RSDS_RR_PER_OBJ24_HeadingAng 1570;
BA_ "GenSigStartValue" SG_ 1527 RSDS_RR_PER_OBJ24_DistZ 512;
BA_ "GenSigStartValue" SG_ 1527 RSDS_RR_PER_OBJ24_DistY 2048;
BA_ "GenSigStartValue" SG_ 1527 RSDS_RR_PER_OBJ24_DistX 4096;
BA_ "GenSigStartValue" SG_ 1527 RSDS_RR_PER_OBJ24_AbsVelY 4102.5641025641;
BA_ "GenSigStartValue" SG_ 1527 RSDS_RR_PER_OBJ24_AbsVelX 4102.5641025641;
BA_ "GenSigStartValue" SG_ 1527 RSDS_RR_PER_OBJ24_AbsAccelY 512;
BA_ "GenSigStartValue" SG_ 1527 RSDS_RR_PER_OBJ24_AbsAccelX 512;
BA_ "GenSigStartValue" SG_ 1526 RSDS_RR_PER_OBJ23_YawRate 1570;
BA_ "SystemSignalLongSymbol" SG_ 1526 RSDS_RR_PER_OBJ23_ObstProbabilit "RSDS_RR_PER_OBJ23_ObstProbability";
BA_ "GenSigStartValue" SG_ 1526 RSDS_RR_PER_OBJ23_HeadingAng 1570;
BA_ "GenSigStartValue" SG_ 1526 RSDS_RR_PER_OBJ23_DistZ 512;
BA_ "GenSigStartValue" SG_ 1526 RSDS_RR_PER_OBJ23_DistY 2048;
BA_ "GenSigStartValue" SG_ 1526 RSDS_RR_PER_OBJ23_DistX 4096;
BA_ "GenSigStartValue" SG_ 1526 RSDS_RR_PER_OBJ23_AbsVelY 4102.5641025641;
BA_ "GenSigStartValue" SG_ 1526 RSDS_RR_PER_OBJ23_AbsVelX 4102.5641025641;
BA_ "GenSigStartValue" SG_ 1526 RSDS_RR_PER_OBJ23_AbsAccelY 512;
BA_ "GenSigStartValue" SG_ 1526 RSDS_RR_PER_OBJ23_AbsAccelX 512;
BA_ "GenSigStartValue" SG_ 1525 RSDS_RR_PER_OBJ22_YawRate 1570;
BA_ "SystemSignalLongSymbol" SG_ 1525 RSDS_RR_PER_OBJ22_ObstProbabilit "RSDS_RR_PER_OBJ22_ObstProbability";
BA_ "GenSigStartValue" SG_ 1525 RSDS_RR_PER_OBJ22_HeadingAng 1570;
BA_ "GenSigStartValue" SG_ 1525 RSDS_RR_PER_OBJ22_DistZ 512;
BA_ "GenSigStartValue" SG_ 1525 RSDS_RR_PER_OBJ22_DistY 2048;
BA_ "GenSigStartValue" SG_ 1525 RSDS_RR_PER_OBJ22_DistX 4096;
BA_ "GenSigStartValue" SG_ 1525 RSDS_RR_PER_OBJ22_AbsVelY 4102.5641025641;
BA_ "GenSigStartValue" SG_ 1525 RSDS_RR_PER_OBJ22_AbsVelX 4102.5641025641;
BA_ "GenSigStartValue" SG_ 1525 RSDS_RR_PER_OBJ22_AbsAccelY 512;
BA_ "GenSigStartValue" SG_ 1525 RSDS_RR_PER_OBJ22_AbsAccelX 512;
BA_ "GenSigStartValue" SG_ 1524 RSDS_RR_PER_OBJ21_YawRate 1570;
BA_ "SystemSignalLongSymbol" SG_ 1524 RSDS_RR_PER_OBJ21_ObstProbabilit "RSDS_RR_PER_OBJ21_ObstProbability";
BA_ "GenSigStartValue" SG_ 1524 RSDS_RR_PER_OBJ21_HeadingAng 1570;
BA_ "GenSigStartValue" SG_ 1524 RSDS_RR_PER_OBJ21_DistZ 512;
BA_ "GenSigStartValue" SG_ 1524 RSDS_RR_PER_OBJ21_DistY 2048;
BA_ "GenSigStartValue" SG_ 1524 RSDS_RR_PER_OBJ21_DistX 4096;
BA_ "GenSigStartValue" SG_ 1524 RSDS_RR_PER_OBJ21_AbsVelY 4102.5641025641;
BA_ "GenSigStartValue" SG_ 1524 RSDS_RR_PER_OBJ21_AbsVelX 4102.5641025641;
BA_ "GenSigStartValue" SG_ 1524 RSDS_RR_PER_OBJ21_AbsAccelY 512;
BA_ "GenSigStartValue" SG_ 1524 RSDS_RR_PER_OBJ21_AbsAccelX 512;
BA_ "GenSigStartValue" SG_ 1523 RSDS_RR_PER_OBJ20_YawRate 1570;
BA_ "SystemSignalLongSymbol" SG_ 1523 RSDS_RR_PER_OBJ20_ObstProbabilit "RSDS_RR_PER_OBJ20_ObstProbability";
BA_ "GenSigStartValue" SG_ 1523 RSDS_RR_PER_OBJ20_HeadingAng 1570;
BA_ "GenSigStartValue" SG_ 1523 RSDS_RR_PER_OBJ20_DistZ 512;
BA_ "GenSigStartValue" SG_ 1523 RSDS_RR_PER_OBJ20_DistY 2048;
BA_ "GenSigStartValue" SG_ 1523 RSDS_RR_PER_OBJ20_DistX 4096;
BA_ "GenSigStartValue" SG_ 1523 RSDS_RR_PER_OBJ20_AbsVelY 4102.5641025641;
BA_ "GenSigStartValue" SG_ 1523 RSDS_RR_PER_OBJ20_AbsVelX 4102.5641025641;
BA_ "GenSigStartValue" SG_ 1523 RSDS_RR_PER_OBJ20_AbsAccelY 512;
BA_ "GenSigStartValue" SG_ 1523 RSDS_RR_PER_OBJ20_AbsAccelX 512;
BA_ "GenSigStartValue" SG_ 1522 RSDS_RR_PER_OBJ19_YawRate 1570;
BA_ "SystemSignalLongSymbol" SG_ 1522 RSDS_RR_PER_OBJ19_ObstProbabilit "RSDS_RR_PER_OBJ19_ObstProbability";
BA_ "GenSigStartValue" SG_ 1522 RSDS_RR_PER_OBJ19_HeadingAng 1570;
BA_ "GenSigStartValue" SG_ 1522 RSDS_RR_PER_OBJ19_DistZ 512;
BA_ "GenSigStartValue" SG_ 1522 RSDS_RR_PER_OBJ19_DistY 2048;
BA_ "GenSigStartValue" SG_ 1522 RSDS_RR_PER_OBJ19_DistX 4096;
BA_ "GenSigStartValue" SG_ 1522 RSDS_RR_PER_OBJ19_AbsVelY 4102.5641025641;
BA_ "GenSigStartValue" SG_ 1522 RSDS_RR_PER_OBJ19_AbsVelX 4102.5641025641;
BA_ "GenSigStartValue" SG_ 1522 RSDS_RR_PER_OBJ19_AbsAccelY 512;
BA_ "GenSigStartValue" SG_ 1522 RSDS_RR_PER_OBJ19_AbsAccelX 512;
BA_ "GenSigStartValue" SG_ 1521 RSDS_RR_PER_OBJ18_YawRate 1570;
BA_ "SystemSignalLongSymbol" SG_ 1521 RSDS_RR_PER_OBJ18_ObstProbabilit "RSDS_RR_PER_OBJ18_ObstProbability";
BA_ "GenSigStartValue" SG_ 1521 RSDS_RR_PER_OBJ18_HeadingAng 1570;
BA_ "GenSigStartValue" SG_ 1521 RSDS_RR_PER_OBJ18_DistZ 512;
BA_ "GenSigStartValue" SG_ 1521 RSDS_RR_PER_OBJ18_DistY 2048;
BA_ "GenSigStartValue" SG_ 1521 RSDS_RR_PER_OBJ18_DistX 4096;
BA_ "GenSigStartValue" SG_ 1521 RSDS_RR_PER_OBJ18_AbsVelY 4102.5641025641;
BA_ "GenSigStartValue" SG_ 1521 RSDS_RR_PER_OBJ18_AbsVelX 4102.5641025641;
BA_ "GenSigStartValue" SG_ 1521 RSDS_RR_PER_OBJ18_AbsAccelY 512;
BA_ "GenSigStartValue" SG_ 1521 RSDS_RR_PER_OBJ18_AbsAccelX 512;
BA_ "GenSigStartValue" SG_ 1520 RSDS_RR_PER_OBJ17_YawRate 1570;
BA_ "SystemSignalLongSymbol" SG_ 1520 RSDS_RR_PER_OBJ17_ObstProbabilit "RSDS_RR_PER_OBJ17_ObstProbability";
BA_ "GenSigStartValue" SG_ 1520 RSDS_RR_PER_OBJ17_HeadingAng 1570;
BA_ "GenSigStartValue" SG_ 1520 RSDS_RR_PER_OBJ17_DistZ 512;
BA_ "GenSigStartValue" SG_ 1520 RSDS_RR_PER_OBJ17_DistY 2048;
BA_ "GenSigStartValue" SG_ 1520 RSDS_RR_PER_OBJ17_DistX 4096;
BA_ "GenSigStartValue" SG_ 1520 RSDS_RR_PER_OBJ17_AbsVelY 4102.5641025641;
BA_ "GenSigStartValue" SG_ 1520 RSDS_RR_PER_OBJ17_AbsVelX 4102.5641025641;
BA_ "GenSigStartValue" SG_ 1520 RSDS_RR_PER_OBJ17_AbsAccelY 512;
BA_ "GenSigStartValue" SG_ 1520 RSDS_RR_PER_OBJ17_AbsAccelX 512;
BA_ "GenSigStartValue" SG_ 1519 RSDS_RR_PER_OBJ16_YawRate 1570;
BA_ "SystemSignalLongSymbol" SG_ 1519 RSDS_RR_PER_OBJ16_ObstProbabilit "RSDS_RR_PER_OBJ16_ObstProbability";
BA_ "GenSigStartValue" SG_ 1519 RSDS_RR_PER_OBJ16_HeadingAng 1570;
BA_ "GenSigStartValue" SG_ 1519 RSDS_RR_PER_OBJ16_DistZ 512;
BA_ "GenSigStartValue" SG_ 1519 RSDS_RR_PER_OBJ16_DistY 2048;
BA_ "GenSigStartValue" SG_ 1519 RSDS_RR_PER_OBJ16_DistX 4096;
BA_ "GenSigStartValue" SG_ 1519 RSDS_RR_PER_OBJ16_AbsVelY 4102.5641025641;
BA_ "GenSigStartValue" SG_ 1519 RSDS_RR_PER_OBJ16_AbsVelX 4102.5641025641;
BA_ "GenSigStartValue" SG_ 1519 RSDS_RR_PER_OBJ16_AbsAccelY 512;
BA_ "GenSigStartValue" SG_ 1519 RSDS_RR_PER_OBJ16_AbsAccelX 512;
BA_ "GenSigStartValue" SG_ 1518 RSDS_RR_PER_OBJ15_YawRate 1570;
BA_ "SystemSignalLongSymbol" SG_ 1518 RSDS_RR_PER_OBJ15_ObstProbabilit "RSDS_RR_PER_OBJ15_ObstProbability";
BA_ "GenSigStartValue" SG_ 1518 RSDS_RR_PER_OBJ15_HeadingAng 1570;
BA_ "GenSigStartValue" SG_ 1518 RSDS_RR_PER_OBJ15_DistZ 512;
BA_ "GenSigStartValue" SG_ 1518 RSDS_RR_PER_OBJ15_DistY 2048;
BA_ "GenSigStartValue" SG_ 1518 RSDS_RR_PER_OBJ15_DistX 4096;
BA_ "GenSigStartValue" SG_ 1518 RSDS_RR_PER_OBJ15_AbsVelY 4102.5641025641;
BA_ "GenSigStartValue" SG_ 1518 RSDS_RR_PER_OBJ15_AbsVelX 4102.5641025641;
BA_ "GenSigStartValue" SG_ 1518 RSDS_RR_PER_OBJ15_AbsAccelY 512;
BA_ "GenSigStartValue" SG_ 1518 RSDS_RR_PER_OBJ15_AbsAccelX 512;
BA_ "GenSigStartValue" SG_ 1517 RSDS_RR_PER_OBJ14_YawRate 1570;
BA_ "SystemSignalLongSymbol" SG_ 1517 RSDS_RR_PER_OBJ14_ObstProbabilit "RSDS_RR_PER_OBJ14_ObstProbability";
BA_ "GenSigStartValue" SG_ 1517 RSDS_RR_PER_OBJ14_HeadingAng 1570;
BA_ "GenSigStartValue" SG_ 1517 RSDS_RR_PER_OBJ14_DistZ 512;
BA_ "GenSigStartValue" SG_ 1517 RSDS_RR_PER_OBJ14_DistY 2048;
BA_ "GenSigStartValue" SG_ 1517 RSDS_RR_PER_OBJ14_DistX 4096;
BA_ "GenSigStartValue" SG_ 1517 RSDS_RR_PER_OBJ14_AbsVelY 4102.5641025641;
BA_ "GenSigStartValue" SG_ 1517 RSDS_RR_PER_OBJ14_AbsVelX 4102.5641025641;
BA_ "GenSigStartValue" SG_ 1517 RSDS_RR_PER_OBJ14_AbsAccelY 512;
BA_ "GenSigStartValue" SG_ 1517 RSDS_RR_PER_OBJ14_AbsAccelX 512;
BA_ "GenSigStartValue" SG_ 1516 RSDS_RR_PER_OBJ13_YawRate 1570;
BA_ "SystemSignalLongSymbol" SG_ 1516 RSDS_RR_PER_OBJ13_ObstProbabilit "RSDS_RR_PER_OBJ13_ObstProbability";
BA_ "GenSigStartValue" SG_ 1516 RSDS_RR_PER_OBJ13_HeadingAng 1570;
BA_ "GenSigStartValue" SG_ 1516 RSDS_RR_PER_OBJ13_DistZ 512;
BA_ "GenSigStartValue" SG_ 1516 RSDS_RR_PER_OBJ13_DistY 2048;
BA_ "GenSigStartValue" SG_ 1516 RSDS_RR_PER_OBJ13_DistX 4096;
BA_ "GenSigStartValue" SG_ 1516 RSDS_RR_PER_OBJ13_AbsVelY 4102.5641025641;
BA_ "GenSigStartValue" SG_ 1516 RSDS_RR_PER_OBJ13_AbsVelX 4102.5641025641;
BA_ "GenSigStartValue" SG_ 1516 RSDS_RR_PER_OBJ13_AbsAccelY 512;
BA_ "GenSigStartValue" SG_ 1516 RSDS_RR_PER_OBJ13_AbsAccelX 512;
BA_ "GenSigStartValue" SG_ 1515 RSDS_RR_PER_OBJ12_YawRate 1570;
BA_ "SystemSignalLongSymbol" SG_ 1515 RSDS_RR_PER_OBJ12_ObstProbabilit "RSDS_RR_PER_OBJ12_ObstProbability";
BA_ "GenSigStartValue" SG_ 1515 RSDS_RR_PER_OBJ12_HeadingAng 1570;
BA_ "GenSigStartValue" SG_ 1515 RSDS_RR_PER_OBJ12_DistZ 512;
BA_ "GenSigStartValue" SG_ 1515 RSDS_RR_PER_OBJ12_DistY 2048;
BA_ "GenSigStartValue" SG_ 1515 RSDS_RR_PER_OBJ12_DistX 4096;
BA_ "GenSigStartValue" SG_ 1515 RSDS_RR_PER_OBJ12_AbsVelY 4102.5641025641;
BA_ "GenSigStartValue" SG_ 1515 RSDS_RR_PER_OBJ12_AbsVelX 4102.5641025641;
BA_ "GenSigStartValue" SG_ 1515 RSDS_RR_PER_OBJ12_AbsAccelY 512;
BA_ "GenSigStartValue" SG_ 1515 RSDS_RR_PER_OBJ12_AbsAccelX 512;
BA_ "GenSigStartValue" SG_ 1514 RSDS_RR_PER_OBJ11_YawRate 1570;
BA_ "SystemSignalLongSymbol" SG_ 1514 RSDS_RR_PER_OBJ11_ObstProbabilit "RSDS_RR_PER_OBJ11_ObstProbability";
BA_ "GenSigStartValue" SG_ 1514 RSDS_RR_PER_OBJ11_HeadingAng 1570;
BA_ "GenSigStartValue" SG_ 1514 RSDS_RR_PER_OBJ11_DistZ 512;
BA_ "GenSigStartValue" SG_ 1514 RSDS_RR_PER_OBJ11_DistY 2048;
BA_ "GenSigStartValue" SG_ 1514 RSDS_RR_PER_OBJ11_DistX 4096;
BA_ "GenSigStartValue" SG_ 1514 RSDS_RR_PER_OBJ11_AbsVelY 4102.5641025641;
BA_ "GenSigStartValue" SG_ 1514 RSDS_RR_PER_OBJ11_AbsVelX 4102.5641025641;
BA_ "GenSigStartValue" SG_ 1514 RSDS_RR_PER_OBJ11_AbsAccelY 512;
BA_ "GenSigStartValue" SG_ 1514 RSDS_RR_PER_OBJ11_AbsAccelX 512;
BA_ "GenSigStartValue" SG_ 1513 RSDS_RR_PER_OBJ10_YawRate 1570;
BA_ "SystemSignalLongSymbol" SG_ 1513 RSDS_RR_PER_OBJ10_ObstProbabilit "RSDS_RR_PER_OBJ10_ObstProbability";
BA_ "GenSigStartValue" SG_ 1513 RSDS_RR_PER_OBJ10_HeadingAng 1570;
BA_ "GenSigStartValue" SG_ 1513 RSDS_RR_PER_OBJ10_DistZ 512;
BA_ "GenSigStartValue" SG_ 1513 RSDS_RR_PER_OBJ10_DistY 2048;
BA_ "GenSigStartValue" SG_ 1513 RSDS_RR_PER_OBJ10_DistX 4096;
BA_ "GenSigStartValue" SG_ 1513 RSDS_RR_PER_OBJ10_AbsVelY 4102.5641025641;
BA_ "GenSigStartValue" SG_ 1513 RSDS_RR_PER_OBJ10_AbsVelX 4102.5641025641;
BA_ "GenSigStartValue" SG_ 1513 RSDS_RR_PER_OBJ10_AbsAccelY 512;
BA_ "GenSigStartValue" SG_ 1513 RSDS_RR_PER_OBJ10_AbsAccelX 512;
BA_ "GenSigStartValue" SG_ 1512 RSDS_RR_PER_OBJ9_YawRate 1570;
BA_ "GenSigStartValue" SG_ 1512 RSDS_RR_PER_OBJ9_HeadingAng 1570;
BA_ "GenSigStartValue" SG_ 1512 RSDS_RR_PER_OBJ9_DistZ 512;
BA_ "GenSigStartValue" SG_ 1512 RSDS_RR_PER_OBJ9_DistY 2048;
BA_ "GenSigStartValue" SG_ 1512 RSDS_RR_PER_OBJ9_DistX 4096;
BA_ "GenSigStartValue" SG_ 1512 RSDS_RR_PER_OBJ9_AbsVelY 4102.5641025641;
BA_ "GenSigStartValue" SG_ 1512 RSDS_RR_PER_OBJ9_AbsVelX 4102.5641025641;
BA_ "GenSigStartValue" SG_ 1512 RSDS_RR_PER_OBJ9_AbsAccelY 512;
BA_ "GenSigStartValue" SG_ 1512 RSDS_RR_PER_OBJ9_AbsAccelX 512;
BA_ "GenSigStartValue" SG_ 1511 RSDS_RR_PER_OBJ8_YawRate 1570;
BA_ "GenSigStartValue" SG_ 1511 RSDS_RR_PER_OBJ8_HeadingAng 1570;
BA_ "GenSigStartValue" SG_ 1511 RSDS_RR_PER_OBJ8_DistZ 512;
BA_ "GenSigStartValue" SG_ 1511 RSDS_RR_PER_OBJ8_DistY 2048;
BA_ "GenSigStartValue" SG_ 1511 RSDS_RR_PER_OBJ8_DistX 4096;
BA_ "GenSigStartValue" SG_ 1511 RSDS_RR_PER_OBJ8_AbsVelY 4102.5641025641;
BA_ "GenSigStartValue" SG_ 1511 RSDS_RR_PER_OBJ8_AbsVelX 4102.5641025641;
BA_ "GenSigStartValue" SG_ 1511 RSDS_RR_PER_OBJ8_AbsAccelY 512;
BA_ "GenSigStartValue" SG_ 1511 RSDS_RR_PER_OBJ8_AbsAccelX 512;
BA_ "GenSigStartValue" SG_ 1510 RSDS_RR_PER_OBJ7_YawRate 1570;
BA_ "GenSigStartValue" SG_ 1510 RSDS_RR_PER_OBJ7_HeadingAng 1570;
BA_ "GenSigStartValue" SG_ 1510 RSDS_RR_PER_OBJ7_DistZ 512;
BA_ "GenSigStartValue" SG_ 1510 RSDS_RR_PER_OBJ7_DistY 2048;
BA_ "GenSigStartValue" SG_ 1510 RSDS_RR_PER_OBJ7_DistX 4096;
BA_ "GenSigStartValue" SG_ 1510 RSDS_RR_PER_OBJ7_AbsVelY 4102.5641025641;
BA_ "GenSigStartValue" SG_ 1510 RSDS_RR_PER_OBJ7_AbsVelX 4102.5641025641;
BA_ "GenSigStartValue" SG_ 1510 RSDS_RR_PER_OBJ7_AbsAccelY 512;
BA_ "GenSigStartValue" SG_ 1510 RSDS_RR_PER_OBJ7_AbsAccelX 512;
